VERSION "dbc-export 1 2026.26.6.5"

NS_ :

BS_:

BU_: ADSP APB APP APS APSB BB BMS CC CMP CMPD CP DAS DI DIF DIR DPB EPAS3P EPAS3S EPASTP EPASTS EPBL EPBR ESP EVSE FC GTW HCML HCMR HVP IBST ICR IDB LS OCS1P ODIN PARK PCS PCS2 PLG PM PMF PMR PNCD PTC RADC RCM RCM2 RCM3 RCU SCCM SCM SCS SDCR TAS TCU TCU2 TPMS TRCM UDS UI UIS UMC USM V2G VC VCBATT VCBATT0 VCBATT1 VCBATT2 VCCC VCFRONT VCFRONT1 VCFRONT2 VCLEFT VCRIGHT VCSEAT2L VCSEAT2R VCSEC VEH

BO_ 935 DIR_alertMatrix: 8 DIR
 SG_ DIR_matrixIndex M : 0|4@1+ (1,0) [0|15] "" Vector__XXX
 SG_ DIR_a001_hwPhaseAgateDrive m0 : 4|1@1+ (1,0) [0|1] "" Vector__XXX
 SG_ DIR_a002_hwPhaseBgateDrive m0 : 5|1@1+ (1,0) [0|1] "" Vector__XXX
 SG_ DIR_a003_hwPhaseCgateDrive m0 : 6|1@1+ (1,0) [0|1] "" Vector__XXX
 SG_ DIR_a004_hwPhaseApeak m0 : 7|1@1+ (1,0) [0|1] "" Vector__XXX
 SG_ DIR_a005_hwPhaseBpeak m0 : 8|1@1+ (1,0) [0|1] "" Vector__XXX
 SG_ DIR_a006_hwPhaseCpeak m0 : 9|1@1+ (1,0) [0|1] "" Vector__XXX
 SG_ DIR_a007_statorAnomalyDetected m0 : 10|1@1+ (1,0) [0|1] "" Vector__XXX
 SG_ DIR_a008_hwEncoderA m0 : 11|1@1+ (1,0) [0|1] "" Vector__XXX
 SG_ DIR_a009_hwEncoderB m0 : 12|1@1+ (1,0) [0|1] "" Vector__XXX
 SG_ DIR_a010_unintendedReset m0 : 13|1@1+ (1,0) [0|1] "" Vector__XXX
 SG_ DIR_a011_swPowerStageNotReady m0 : 14|1@1+ (1,0) [0|1] "" Vector__XXX
 SG_ DIR_a012_hvilNotClosed m0 : 15|1@1+ (1,0) [0|1] "" Vector__XXX
 SG_ DIR_a013_eccError m0 : 16|1@1+ (1,0) [0|1] "" Vector__XXX
 SG_ DIR_a014_activeDamping m0 : 17|1@1+ (1,0) [0|1] "" Vector__XXX
 SG_ DIR_a015_mechSafeStateAnomaly m0 : 18|1@1+ (1,0) [0|1] "" Vector__XXX
 SG_ DIR_a016_safeStateApplied m0 : 19|1@1+ (1,0) [0|1] "" Vector__XXX
 SG_ DIR_a017_hwPedalMonitor m0 : 20|1@1+ (1,0) [0|1] "" Vector__XXX
 SG_ DIR_a018_hwLVSupplyUV m0 : 21|1@1+ (1,0) [0|1] "" Vector__XXX
 SG_ DIR_a020_hwMotorEncoder m0 : 23|1@1+ (1,0) [0|1] "" Vector__XXX
 SG_ DIR_a021_hwBusOV m0 : 24|1@1+ (1,0) [0|1] "" Vector__XXX
 SG_ DIR_a022_hw5vSupplyUV m0 : 25|1@1+ (1,0) [0|1] "" Vector__XXX
 SG_ DIR_a024_selfTest m0 : 27|1@1+ (1,0) [0|1] "" Vector__XXX
 SG_ DIR_a025_phaseApeak m0 : 28|1@1+ (1,0) [0|1] "" Vector__XXX
 SG_ DIR_a026_phaseBpeak m0 : 29|1@1+ (1,0) [0|1] "" Vector__XXX
 SG_ DIR_a027_phaseCpeak m0 : 30|1@1+ (1,0) [0|1] "" Vector__XXX
 SG_ DIR_a028_phaseArms m0 : 31|1@1+ (1,0) [0|1] "" Vector__XXX
 SG_ DIR_a029_phaseBrms m0 : 32|1@1+ (1,0) [0|1] "" Vector__XXX
 SG_ DIR_a030_phaseCrms m0 : 33|1@1+ (1,0) [0|1] "" Vector__XXX
 SG_ DIR_a031_phaseAcurrentOffset m0 : 34|1@1+ (1,0) [0|1] "" Vector__XXX
 SG_ DIR_a032_phaseBcurrentOffset m0 : 35|1@1+ (1,0) [0|1] "" Vector__XXX
 SG_ DIR_a033_phaseAcurrentSensor m0 : 36|1@1+ (1,0) [0|1] "" Vector__XXX
 SG_ DIR_a034_phaseBcurrentSensor m0 : 37|1@1+ (1,0) [0|1] "" Vector__XXX
 SG_ DIR_a035_phaseCurrentBalance m0 : 38|1@1+ (1,0) [0|1] "" Vector__XXX
 SG_ DIR_a036_busOV m0 : 39|1@1+ (1,0) [0|1] "" Vector__XXX
 SG_ DIR_a037_busUV m0 : 40|1@1+ (1,0) [0|1] "" Vector__XXX
 SG_ DIR_a038_busVsensor m0 : 41|1@1+ (1,0) [0|1] "" Vector__XXX
 SG_ DIR_a039_exceptionUndefinedInstr m0 : 42|1@1+ (1,0) [0|1] "" Vector__XXX
 SG_ DIR_a040_difMIA m0 : 43|1@1+ (1,0) [0|1] "" Vector__XXX
 SG_ DIR_a041_sdcMIA m0 : 44|1@1+ (1,0) [0|1] "" Vector__XXX
 SG_ DIR_a042_inletSensor m0 : 45|1@1+ (1,0) [0|1] "" Vector__XXX
 SG_ DIR_a043_outletOT m0 : 46|1@1+ (1,0) [0|1] "" Vector__XXX
 SG_ DIR_a044_outletUT m0 : 47|1@1+ (1,0) [0|1] "" Vector__XXX
 SG_ DIR_a045_outletSensor m0 : 48|1@1+ (1,0) [0|1] "" Vector__XXX
 SG_ DIR_a046_statorOT m0 : 49|1@1+ (1,0) [0|1] "" Vector__XXX
 SG_ DIR_a047_statorSensor1 m0 : 50|1@1+ (1,0) [0|1] "" Vector__XXX
 SG_ DIR_a048_statorSensor2 m0 : 51|1@1+ (1,0) [0|1] "" Vector__XXX
 SG_ DIR_a049_statorSensorDiff m0 : 52|1@1+ (1,0) [0|1] "" Vector__XXX
 SG_ DIR_a050_noStatorSensor m0 : 53|1@1+ (1,0) [0|1] "" Vector__XXX
 SG_ DIR_a052_dirMIA m0 : 55|1@1+ (1,0) [0|1] "" Vector__XXX
 SG_ DIR_a053_unexpectedLatchState m0 : 56|1@1+ (1,0) [0|1] "" Vector__XXX
 SG_ DIR_a054_driveInverterOT m0 : 57|1@1+ (1,0) [0|1] "" Vector__XXX
 SG_ DIR_a055_trqCrossCheck m0 : 58|1@1+ (1,0) [0|1] "" Vector__XXX
 SG_ DIR_a056_ambientOT m0 : 59|1@1+ (1,0) [0|1] "" Vector__XXX
 SG_ DIR_a057_ambientUT m0 : 60|1@1+ (1,0) [0|1] "" Vector__XXX
 SG_ DIR_a058_ambientSensor m0 : 61|1@1+ (1,0) [0|1] "" Vector__XXX
 SG_ DIR_a059_heatsinkOT m0 : 62|1@1+ (1,0) [0|1] "" Vector__XXX
 SG_ DIR_a060_heatsinkUT m0 : 63|1@1+ (1,0) [0|1] "" Vector__XXX
 SG_ DIR_a061_heatsinkSensor m1 : 4|1@1+ (1,0) [0|1] "" Vector__XXX
 SG_ DIR_a062_systemLimpMode m1 : 5|1@1+ (1,0) [0|1] "" Vector__XXX
 SG_ DIR_a063_bbMIA m1 : 6|1@1+ (1,0) [0|1] "" Vector__XXX
 SG_ DIR_a064_torqueIntervention m1 : 7|1@1+ (1,0) [0|1] "" Vector__XXX
 SG_ DIR_a065_canHardwareBusB m1 : 8|1@1+ (1,0) [0|1] "" Vector__XXX
 SG_ DIR_a066_canDataBusB m1 : 9|1@1+ (1,0) [0|1] "" Vector__XXX
 SG_ DIR_a067_canOverrunBusB m1 : 10|1@1+ (1,0) [0|1] "" Vector__XXX
 SG_ DIR_a069_rotorTempLimit m1 : 12|1@1+ (1,0) [0|1] "" Vector__XXX
 SG_ DIR_a070_udsTransactionInitiated m1 : 13|1@1+ (1,0) [0|1] "" Vector__XXX
 SG_ DIR_a071_busDisconnected m1 : 14|1@1+ (1,0) [0|1] "" Vector__XXX
 SG_ DIR_a072_gateDriveFaultCounter m1 : 15|1@1+ (1,0) [0|1] "" Vector__XXX
 SG_ DIR_a073_motorSpeed m1 : 16|1@1+ (1,0) [0|1] "" Vector__XXX
 SG_ DIR_a074_motorEncoder m1 : 17|1@1+ (1,0) [0|1] "" Vector__XXX
 SG_ DIR_a075_motorSpeedMismatch m1 : 18|1@1+ (1,0) [0|1] "" Vector__XXX
 SG_ DIR_a076_lvSupplyOV m1 : 19|1@1+ (1,0) [0|1] "" Vector__XXX
 SG_ DIR_a077_lvSupplyUV m1 : 20|1@1+ (1,0) [0|1] "" Vector__XXX
 SG_ DIR_a078_adcRefLow m1 : 21|1@1+ (1,0) [0|1] "" Vector__XXX
 SG_ DIR_a079_adcRefHigh m1 : 22|1@1+ (1,0) [0|1] "" Vector__XXX
 SG_ DIR_a084_eccTestData0 m1 : 27|1@1+ (1,0) [0|1] "" Vector__XXX
 SG_ DIR_d085_driveInverterBoardFailu m1 : 28|1@1+ (1,0) [0|1] "" Vector__XXX
 SG_ DIR_a086_activeDischargeOn m1 : 29|1@1+ (1,0) [0|1] "" Vector__XXX
 SG_ DIR_a087_gtwMIA m1 : 30|1@1+ (1,0) [0|1] "" Vector__XXX
 SG_ DIR_a088_uiMIA m1 : 31|1@1+ (1,0) [0|1] "" Vector__XXX
 SG_ DIR_d089_invalidTorqueCommand m1 : 32|1@1+ (1,0) [0|1] "" Vector__XXX
 SG_ DIR_a090_pmMIA m1 : 33|1@1+ (1,0) [0|1] "" Vector__XXX
 SG_ DIR_a091_espMIA m1 : 34|1@1+ (1,0) [0|1] "" Vector__XXX
 SG_ DIR_a092_bmsMIA m1 : 35|1@1+ (1,0) [0|1] "" Vector__XXX
 SG_ DIR_a093_canHardwareBusA m1 : 36|1@1+ (1,0) [0|1] "" Vector__XXX
 SG_ DIR_a094_canDataBusA m1 : 37|1@1+ (1,0) [0|1] "" Vector__XXX
 SG_ DIR_a095_canOverrunBusA m1 : 38|1@1+ (1,0) [0|1] "" Vector__XXX
 SG_ DIR_a096_memoryError m1 : 39|1@1+ (1,0) [0|1] "" Vector__XXX
 SG_ DIR_a097_eepromError m1 : 40|1@1+ (1,0) [0|1] "" Vector__XXX
 SG_ DIR_a098_intTimeTooLong m1 : 41|1@1+ (1,0) [0|1] "" Vector__XXX
 SG_ DIR_a099_threadOverrun m1 : 42|1@1+ (1,0) [0|1] "" Vector__XXX
 SG_ DIR_a100_assertion m1 : 43|1@1+ (1,0) [0|1] "" Vector__XXX
 SG_ DIR_a101_eccTestData1 m1 : 44|1@1+ (1,0) [0|1] "" Vector__XXX
 SG_ DIR_a102_exceptionPrefetchAbort m1 : 45|1@1+ (1,0) [0|1] "" Vector__XXX
 SG_ DIR_a103_lowFlow m1 : 46|1@1+ (1,0) [0|1] "" Vector__XXX
 SG_ DIR_d104_resetUnintended m1 : 47|1@1+ (1,0) [0|1] "" Vector__XXX
 SG_ DIR_d105_busVoltageSensorIssue m1 : 48|1@1+ (1,0) [0|1] "" Vector__XXX
 SG_ DIR_a106_idleTaskStarving m1 : 49|1@1+ (1,0) [0|1] "" Vector__XXX
 SG_ DIR_a107_fpgaError m1 : 50|1@1+ (1,0) [0|1] "" Vector__XXX
 SG_ DIR_a108_stateTrans m1 : 51|1@1+ (1,0) [0|1] "" Vector__XXX
 SG_ DIR_a109_ahbWriteError m1 : 52|1@1+ (1,0) [0|1] "" Vector__XXX
 SG_ DIR_a110_brakeMIA m1 : 53|1@1+ (1,0) [0|1] "" Vector__XXX
 SG_ DIR_a111_badPhaseSensorCalib m1 : 54|1@1+ (1,0) [0|1] "" Vector__XXX
 SG_ DIR_a112_noPhaseCurrent m1 : 55|1@1+ (1,0) [0|1] "" Vector__XXX
 SG_ DIR_a113_noFuncHeatsinkSensor m1 : 56|1@1+ (1,0) [0|1] "" Vector__XXX
 SG_ DIR_a114_exceptionDataAbort m1 : 57|1@1+ (1,0) [0|1] "" Vector__XXX
 SG_ DIR_a115_exceptionDataAbort2 m1 : 58|1@1+ (1,0) [0|1] "" Vector__XXX
 SG_ DIR_a116_highSpeedWearCounter m1 : 59|1@1+ (1,0) [0|1] "" Vector__XXX
 SG_ DIR_a117_diMIA m1 : 60|1@1+ (1,0) [0|1] "" Vector__XXX
 SG_ DIR_d118_oilPumpCommsLost m1 : 61|1@1+ (1,0) [0|1] "" Vector__XXX
 SG_ DIR_a119_hvpMIA m1 : 62|1@1+ (1,0) [0|1] "" Vector__XXX
 SG_ DIR_a120_hvlinkMIA m1 : 63|1@1+ (1,0) [0|1] "" Vector__XXX
 SG_ DIR_a121_motorControlRegulation m2 : 4|1@1+ (1,0) [0|1] "" Vector__XXX
 SG_ DIR_a122_highStackUsage m2 : 5|1@1+ (1,0) [0|1] "" Vector__XXX
 SG_ DIR_a123_lossMotorControl m2 : 6|1@1+ (1,0) [0|1] "" Vector__XXX
 SG_ DIR_d124_oilPumpServiceRequired m2 : 7|1@1+ (1,0) [0|1] "" Vector__XXX
 SG_ DIR_d125_currentSensorIssue m2 : 8|1@1+ (1,0) [0|1] "" Vector__XXX
 SG_ DIR_a126_limpMode m2 : 9|1@1+ (1,0) [0|1] "" Vector__XXX
 SG_ DIR_a127_gracefulPowerOff m2 : 10|1@1+ (1,0) [0|1] "" Vector__XXX
 SG_ DIR_a128_fpgaVersionMismatch m2 : 11|1@1+ (1,0) [0|1] "" Vector__XXX
 SG_ DIR_d129_oilPumpIssue m2 : 12|1@1+ (1,0) [0|1] "" Vector__XXX
 SG_ DIR_d130_positionSensorIssue m2 : 13|1@1+ (1,0) [0|1] "" Vector__XXX
 SG_ DIR_d131_currentSensorOffset m2 : 14|1@1+ (1,0) [0|1] "" Vector__XXX
 SG_ DIR_d132_busUVIssue m2 : 15|1@1+ (1,0) [0|1] "" Vector__XXX
 SG_ DIR_a133_capacitorOT m2 : 16|1@1+ (1,0) [0|1] "" Vector__XXX
 SG_ DIR_a134_wheelSpeedIrrational m2 : 17|1@1+ (1,0) [0|1] "" Vector__XXX
 SG_ DIR_d135_rotatedStator m2 : 18|1@1+ (1,0) [0|1] "" Vector__XXX
 SG_ DIR_a136_spiError m2 : 19|1@1+ (1,0) [0|1] "" Vector__XXX
 SG_ DIR_d137_currentSensorOutOfRange m2 : 20|1@1+ (1,0) [0|1] "" Vector__XXX
 SG_ DIR_d138_inverterLVPowerSupplyLo m2 : 21|1@1+ (1,0) [0|1] "" Vector__XXX
 SG_ DIR_d141_coolingSystemIssue m2 : 24|1@1+ (1,0) [0|1] "" Vector__XXX
 SG_ DIR_a142_highLashAngle m2 : 25|1@1+ (1,0) [0|1] "" Vector__XXX
 SG_ DIR_d143_wheelSpeedCorrelationIs m2 : 26|1@1+ (1,0) [0|1] "" Vector__XXX
 SG_ DIR_a144_configMismatch m2 : 27|1@1+ (1,0) [0|1] "" Vector__XXX
 SG_ DIR_a147_highTorqueWearLimit m2 : 30|1@1+ (1,0) [0|1] "" Vector__XXX
 SG_ DIR_a148_burnInCycleEnded m2 : 31|1@1+ (1,0) [0|1] "" Vector__XXX
 SG_ DIR_a149_oilPumpFailure m2 : 32|1@1+ (1,0) [0|1] "" Vector__XXX
 SG_ DIR_a150_busVD m2 : 33|1@1+ (1,0) [0|1] "" Vector__XXX
 SG_ DIR_a151_shockTorqueLimiter m2 : 34|1@1+ (1,0) [0|1] "" Vector__XXX
 SG_ DIR_a152_linError m2 : 35|1@1+ (1,0) [0|1] "" Vector__XXX
 SG_ DIR_a153_oilPumpDiagnostics m2 : 36|1@1+ (1,0) [0|1] "" Vector__XXX
 SG_ DIR_a154_resolver m2 : 37|1@1+ (1,0) [0|1] "" Vector__XXX
 SG_ DIR_a155_vcfrontMIA m2 : 38|1@1+ (1,0) [0|1] "" Vector__XXX
 SG_ DIR_a156_currentObserver m2 : 39|1@1+ (1,0) [0|1] "" Vector__XXX
 SG_ DIR_a157_rcmMIA m2 : 40|1@1+ (1,0) [0|1] "" Vector__XXX
 SG_ DIR_a158_ibstMIA m2 : 41|1@1+ (1,0) [0|1] "" Vector__XXX
 SG_ DIR_a160_busVoltageAnomaly m2 : 43|1@1+ (1,0) [0|1] "" Vector__XXX
 SG_ DIR_a161_epas3pMIA m2 : 44|1@1+ (1,0) [0|1] "" Vector__XXX
 SG_ DIR_a162_endOfLifetimeBurnIn m2 : 45|1@1+ (1,0) [0|1] "" Vector__XXX
 SG_ DIR_d163_recoverableOvercurrent m2 : 46|1@1+ (1,0) [0|1] "" Vector__XXX
 SG_ DIR_d164_firmwareConfigMismatch m2 : 47|1@1+ (1,0) [0|1] "" Vector__XXX
 SG_ DIR_d165_statorOverTemperature m2 : 48|1@1+ (1,0) [0|1] "" Vector__XXX
 SG_ DIR_d166_rotorOverTemperature m2 : 49|1@1+ (1,0) [0|1] "" Vector__XXX
 SG_ DIR_d167_tempSensorIssue m2 : 50|1@1+ (1,0) [0|1] "" Vector__XXX
 SG_ DIR_a171_rdcError m2 : 54|1@1+ (1,0) [0|1] "" Vector__XXX
 SG_ DIR_a172_statorOilTempOT m2 : 55|1@1+ (1,0) [0|1] "" Vector__XXX
 SG_ DIR_a173_ascFdbkDiagnostic m2 : 56|1@1+ (1,0) [0|1] "" Vector__XXX
 SG_ DIR_a174_unitMayNotRestart m2 : 57|1@1+ (1,0) [0|1] "" Vector__XXX
 SG_ DIR_d175_oilPumpBCommsLost m2 : 58|1@1+ (1,0) [0|1] "" Vector__XXX
 SG_ DIR_a176_safetyICFault m2 : 59|1@1+ (1,0) [0|1] "" Vector__XXX
 SG_ DIR_a177_fluxReferenceCorrected m2 : 60|1@1+ (1,0) [0|1] "" Vector__XXX
 SG_ DIR_a178_spindownLearningBrakeAl m2 : 61|1@1+ (1,0) [0|1] "" Vector__XXX
 SG_ DIR_d179_oilPumpBIssue m2 : 62|1@1+ (1,0) [0|1] "" Vector__XXX
 SG_ DIR_a194_resolverGainAnomaly m3 : 17|1@1+ (1,0) [0|1] "" Vector__XXX
 SG_ DIR_a202_excessHeatUnavailable m3 : 25|1@1+ (1,0) [0|1] "" Vector__XXX
 SG_ DIR_a225_tmpEstPlausibility m3 : 48|1@1+ (1,0) [0|1] "" Vector__XXX
 SG_ DIR_a229_busVsensorOverCAN m3 : 52|1@1+ (1,0) [0|1] "" Vector__XXX
 SG_ DIR_a233_diMsgMissed m3 : 56|1@1+ (1,0) [0|1] "" Vector__XXX
 SG_ DIR_a234_pcsMIA m3 : 57|1@1+ (1,0) [0|1] "" Vector__XXX
 SG_ DIR_a236_tasMIA m3 : 59|1@1+ (1,0) [0|1] "" Vector__XXX
 SG_ DIR_a239_rotorDemagnetizationDet m3 : 62|1@1+ (1,0) [0|1] "" Vector__XXX
 SG_ DIR_a240_clearFusesRoutine m3 : 63|1@1+ (1,0) [0|1] "" Vector__XXX
 SG_ DIR_a241_systemThermallyLimited m4 : 4|1@1+ (1,0) [0|1] "" Vector__XXX
 SG_ DIR_a242_spinDownLearning m4 : 5|1@1+ (1,0) [0|1] "" Vector__XXX
 SG_ DIR_a243_ecuLogAvailable m4 : 6|1@1+ (1,0) [0|1] "" Vector__XXX
 SG_ DIR_a244_mechSafeStateApplied m4 : 7|1@1+ (1,0) [0|1] "" Vector__XXX
 SG_ DIR_a245_mechSafeStatePreWarn m4 : 8|1@1+ (1,0) [0|1] "" Vector__XXX
 SG_ DIR_a246_recoveryAtSpeedError m4 : 9|1@1+ (1,0) [0|1] "" Vector__XXX
 SG_ DIR_a247_rotorOffsetError m4 : 10|1@1+ (1,0) [0|1] "" Vector__XXX
 SG_ DIR_a248_vehicleSpeedLimited m4 : 11|1@1+ (1,0) [0|1] "" Vector__XXX
 SG_ DIR_a249_highStatorTempFromResis m4 : 12|1@1+ (1,0) [0|1] "" Vector__XXX
 SG_ DIR_a250_preregulatorRail m4 : 13|1@1+ (1,0) [0|1] "" Vector__XXX
 SG_ DIR_a251_oilPumpService m4 : 14|1@1+ (1,0) [0|1] "" Vector__XXX
 SG_ DIR_a252_currentCoreFallback m4 : 15|1@1+ (1,0) [0|1] "" Vector__XXX
 SG_ DIR_a253_lvBoostedRail m4 : 16|1@1+ (1,0) [0|1] "" Vector__XXX
 SG_ DIR_a254_activeDischargeRail m4 : 17|1@1+ (1,0) [0|1] "" Vector__XXX
 SG_ DIR_a255_currentGainFallback m4 : 18|1@1+ (1,0) [0|1] "" Vector__XXX

BO_ 2005 DIR_debug: 8 DIR
 SG_ DIR_debugSelector M : 0|8@1+ (1,0) [0|255] "" Vector__XXX
 SG_ DIR_phaseOutBusbarTemp m70 : 8|8@1+ (1,-40) [-39|215] "DegC" Vector__XXX
 SG_ DIR_phaseOutBusbarWeldTemp m70 : 16|8@1+ (1,-40) [-39|215] "DegC" Vector__XXX
 SG_ DIR_phaseOutLugTemp m70 : 24|8@1+ (1,-40) [-39|215] "DegC" Vector__XXX
 SG_ DIR_dcLinkCapTemp m70 : 32|8@1+ (1,-40) [-39|215] "DegC" Vector__XXX
 SG_ DIR_hvDcCableTemp m70 : 40|8@1+ (1,-40) [-39|215] "DegC" Vector__XXX
 SG_ DIR_negDcBusbarTemp m70 : 48|8@1+ (1,-40) [-39|215] "DegC" Vector__XXX
 SG_ DIR_posDcBusbarTemp m70 : 56|8@1+ (1,-40) [-39|215] "DegC" Vector__XXX
 SG_ DIR_statorEndWindingTemp m72 : 8|8@1+ (1,-40) [-39|215] "DegC" Vector__XXX
 SG_ DIR_rotorMaxMagnetTemp m72 : 16|8@1+ (1,-40) [-39|215] "DegC" Vector__XXX
 SG_ DIR_lightSenseV m72 : 24|6@1+ (0.1,0) [0|3.3] "V" Vector__XXX
 SG_ DIR_pyroSenseV m72 : 30|8@1+ (0.02,0) [0|3.3] "V" Vector__XXX
 SG_ DIR_statorSlotWindingTemp m72 : 46|8@1+ (1,-40) [-39|215] "DegC" Vector__XXX
 SG_ DIR_intervalMaxHvBusV m72 : 54|10@1+ (1,0) [0|1023] "V" Vector__XXX

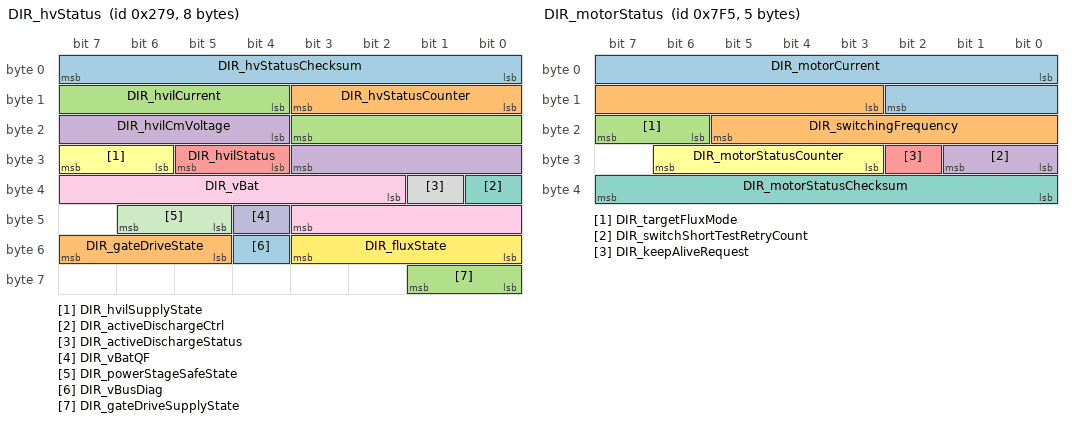
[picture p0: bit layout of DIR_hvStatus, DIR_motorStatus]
BO_ 633 DIR_hvStatus: 8 DIR
 SG_ DIR_hvStatusChecksum : 0|8@1+ (1,0) [0|255] "" Vector__XXX
 SG_ DIR_hvStatusCounter : 8|4@1+ (1,0) [0|15] "" Vector__XXX
 SG_ DIR_hvilCurrent : 12|8@1+ (0.1,0) [0|25.5] "mA" Vector__XXX
 SG_ DIR_hvilCmVoltage : 20|8@1+ (0.08,0) [0|20.4] "V" Vector__XXX
 SG_ DIR_hvilStatus : 28|2@1+ (1,0) [0|2] "" Vector__XXX
 SG_ DIR_hvilSupplyState : 30|2@1+ (1,0) [0|3] "" Vector__XXX
 SG_ DIR_activeDischargeCtrl : 32|1@1+ (1,0) [0|1] "" Vector__XXX
 SG_ DIR_activeDischargeStatus : 33|1@1+ (1,0) [0|1] "" Vector__XXX
 SG_ DIR_vBat : 34|10@1+ (1,0) [0|1023] "V" Vector__XXX
 SG_ DIR_vBatQF : 44|1@1+ (1,0) [0|1] "" Vector__XXX
 SG_ DIR_powerStageSafeState : 45|2@1+ (1,0) [0|3] "" Vector__XXX
 SG_ DIR_fluxState : 48|4@1+ (1,0) [0|15] "" Vector__XXX
 SG_ DIR_vBusDiag : 52|1@1+ (1,0) [0|1] "" Vector__XXX
 SG_ DIR_gateDriveState : 53|3@1+ (1,0) [0|7] "" Vector__XXX
 SG_ DIR_gateDriveSupplyState : 56|2@1+ (1,0) [0|3] "" Vector__XXX

BO_ 821 DIR_info: 8 DIR
 SG_ DIR_infoIndex M : 0|8@1+ (1,0) [0|255] "" Vector__XXX
 SG_ DIR_buildType m10 : 8|3@1+ (1,0) [0|7] "" Vector__XXX
 SG_ DIR_buildConfigurationId m10 : 16|16@1+ (1,0) [0|65535] "" Vector__XXX
 SG_ DIR_hardwareId m10 : 32|8@1+ (1,0) [0|252] "" Vector__XXX
 SG_ DIR_componentId m10 : 48|16@1+ (1,0) [0|65535] "" Vector__XXX
 SG_ DIR_pcbaId m11 : 16|8@1+ (1,0) [0|255] "" Vector__XXX
 SG_ DIR_assemblyId m11 : 24|8@1+ (1,0) [0|255] "" Vector__XXX
 SG_ DIR_usageId m11 : 32|16@1+ (1,0) [0|65535] "" Vector__XXX
 SG_ DIR_subUsageId m11 : 48|16@1+ (1,0) [0|65535] "" Vector__XXX
 SG_ DIR_motorType m12 : 8|6@1+ (1,0) [1|63] "" Vector__XXX
 SG_ DIR_siliconType m12 : 16|1@1+ (1,0) [0|1] "" Vector__XXX
 SG_ DIR_mechSafeStateType m12 : 24|2@1+ (1,0) [1|3] "" Vector__XXX
 SG_ DIR_applicationCrc m13 : 32|32@1+ (1,0) [0|4294967295] "" Vector__XXX
 SG_ DIR_oilPumpBuildType m16 : 8|3@1+ (1,0) [0|7] "" Vector__XXX
 SG_ DIR_oilPumpAppCrc m16 : 16|32@1+ (1,0) [0|4294967295] "" Vector__XXX
 SG_ DIR_FPGA_version m16 : 48|8@1+ (1,0) [0|254] "" Vector__XXX
 SG_ DIR_appGitHash m17 : 8|56@1+ (1,0) [0|7.20575940379e+16] "" Vector__XXX
 SG_ DIR_bootGitHash m18 : 8|56@1+ (1,0) [0|7.20575940379e+16] "" Vector__XXX
 SG_ DIR_infoBootLdUdsProtocolVersion m20 : 8|8@1+ (1,0) [0|255] "" Vector__XXX
 SG_ DIR_bootloaderCrc m20 : 32|32@1+ (1,0) [0|4294967295] "" Vector__XXX
 SG_ DIR_oilPumpPcbaId m33 : 8|8@1+ (1,0) [0|255] "" Vector__XXX
 SG_ DIR_oilPumpAssemblyId m33 : 16|8@1+ (1,0) [0|255] "" Vector__XXX
 SG_ DIR_oilPumpUsageId m33 : 24|16@1+ (1,0) [0|65535] "" Vector__XXX
 SG_ DIR_refRotorFlux m35 : 8|16@1+ (0.0001,0) [0|6.5535] "Wb" Vector__XXX
 SG_ DIR_refRotorOffset m35 : 24|12@1- (0.1,0) [-180|180] "deg" Vector__XXX
 SG_ DIR_speedWearTotal m36 : 8|8@1+ (0.4,0) [0|100] "%" Vector__XXX
 SG_ DIR_torqueWearTotal m36 : 24|8@1+ (0.02,0) [0|5.08] "1" Vector__XXX

BO_ 2037 DIR_motorStatus: 5 DIR
 SG_ DIR_motorCurrent : 0|11@1+ (1,0) [0|2047] "A" Vector__XXX
 SG_ DIR_switchingFrequency : 11|11@1+ (0.01,0) [0|20] "kHz" Vector__XXX
 SG_ DIR_targetFluxMode : 22|2@1+ (1,0) [0|3] "" Vector__XXX
 SG_ DIR_switchShortTestRetryCount : 24|2@1+ (1,0) [0|3] "" Vector__XXX
 SG_ DIR_keepAliveRequest : 26|1@1+ (1,0) [0|1] "" Vector__XXX
 SG_ DIR_motorStatusCounter : 27|4@1+ (1,0) [0|15] "" Vector__XXX
 SG_ DIR_motorStatusChecksum : 32|8@1+ (1,0) [0|255] "" Vector__XXX

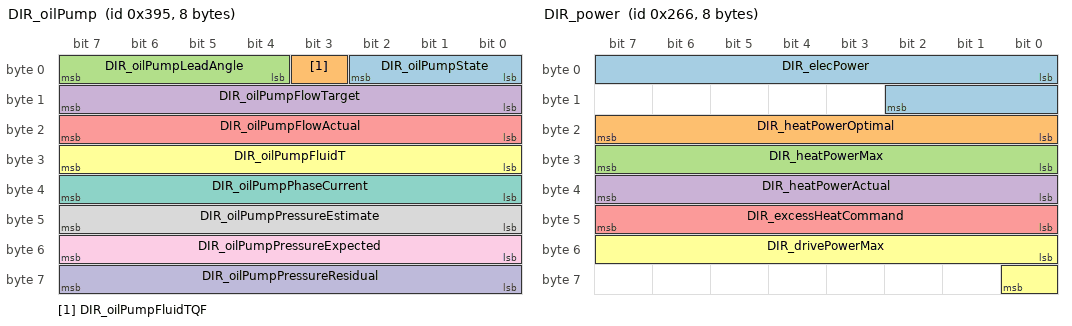
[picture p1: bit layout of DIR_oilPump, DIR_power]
BO_ 917 DIR_oilPump: 8 DIR
 SG_ DIR_oilPumpState : 0|3@1+ (1,0) [0|6] "" Vector__XXX
 SG_ DIR_oilPumpFluidTQF : 3|1@1+ (1,0) [0|1] "" Vector__XXX
 SG_ DIR_oilPumpLeadAngle : 4|4@1+ (1.875,0) [0|28.125] "degrees" Vector__XXX
 SG_ DIR_oilPumpFlowTarget : 8|8@1+ (0.1,0) [0|25.4] "LPM" Vector__XXX
 SG_ DIR_oilPumpFlowActual : 16|8@1+ (0.1,0) [0|25.4] "LPM" Vector__XXX
 SG_ DIR_oilPumpFluidT : 24|8@1+ (1,-40) [-40|214] "DegC" Vector__XXX
 SG_ DIR_oilPumpPhaseCurrent : 32|8@1+ (0.1,0) [0|25.4] "A" Vector__XXX
 SG_ DIR_oilPumpPressureEstimate : 40|8@1+ (2,0) [0|500] "kPa" Vector__XXX
 SG_ DIR_oilPumpPressureExpected : 48|8@1+ (2,0) [0|500] "kPa" Vector__XXX
 SG_ DIR_oilPumpPressureResidual : 56|8@1+ (4,-500) [-500|500] "kPa" Vector__XXX

BO_ 614 DIR_power: 8 DIR
 SG_ DIR_elecPower : 0|11@1- (0.5,0) [-500|500] "kW" Vector__XXX
 SG_ DIR_heatPowerOptimal : 16|8@1+ (0.08,0) [0|20] "kW" Vector__XXX
 SG_ DIR_heatPowerMax : 24|8@1+ (0.08,0) [0|20] "kW" Vector__XXX
 SG_ DIR_heatPowerActual : 32|8@1+ (0.08,0) [0|20] "kW" Vector__XXX
 SG_ DIR_excessHeatCommand : 40|8@1+ (0.08,0) [0|20] "kW" Vector__XXX
 SG_ DIR_drivePowerMax : 48|9@1+ (1,0) [0|400] "kW" Vector__XXX

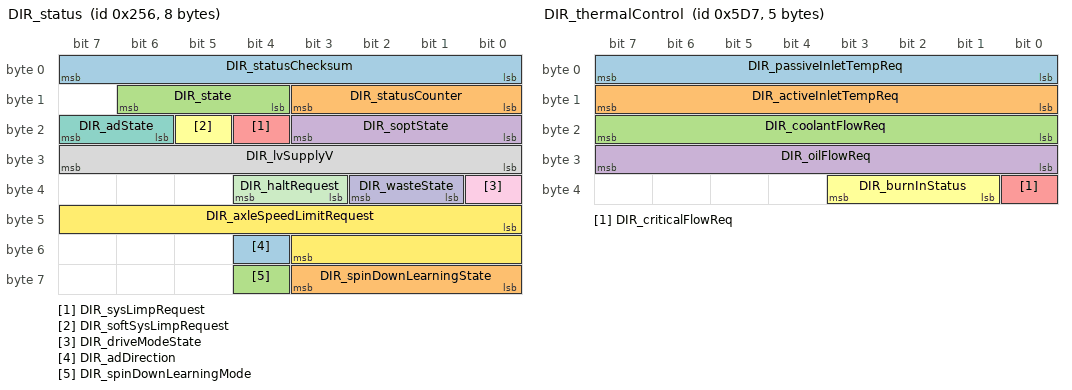
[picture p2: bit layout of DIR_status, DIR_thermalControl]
BO_ 598 DIR_status: 8 DIR
 SG_ DIR_statusChecksum : 0|8@1+ (1,0) [0|255] "" Vector__XXX
 SG_ DIR_statusCounter : 8|4@1+ (1,0) [0|15] "" Vector__XXX
 SG_ DIR_state : 12|3@1+ (1,0) [0|7] "" Vector__XXX
 SG_ DIR_soptState : 16|4@1+ (1,0) [0|15] "" Vector__XXX
 SG_ DIR_sysLimpRequest : 20|1@1+ (1,0) [0|1] "" Vector__XXX
 SG_ DIR_softSysLimpRequest : 21|1@1+ (1,0) [0|1] "" Vector__XXX
 SG_ DIR_adState : 22|2@1+ (1,0) [0|3] "" Vector__XXX
 SG_ DIR_lvSupplyV : 24|8@1+ (0.1,0) [0|25.5] "V" Vector__XXX
 SG_ DIR_driveModeState : 32|1@1+ (1,0) [0|1] "" Vector__XXX
 SG_ DIR_wasteState : 33|2@1+ (1,0) [0|3] "" Vector__XXX
 SG_ DIR_haltRequest : 35|2@1+ (1,0) [0|3] "" Vector__XXX
 SG_ DIR_axleSpeedLimitRequest : 40|12@1+ (1,40) [400|2750] "RPM" Vector__XXX
 SG_ DIR_adDirection : 52|1@1+ (1,0) [0|1] "" Vector__XXX
 SG_ DIR_spinDownLearningState : 56|4@1+ (1,0) [0|15] "" Vector__XXX
 SG_ DIR_spinDownLearningMode : 60|1@1+ (1,0) [0|1] "" Vector__XXX

BO_ 789 DIR_temperature: 8 DIR
 SG_ DIR_tempIndex M : 0|3@1+ (1,0) [0|7] "" Vector__XXX
 SG_ DIR_inverterTQF m0 : 3|2@1+ (1,0) [0|3] "" Vector__XXX
 SG_ DIR_pcbT m0 : 8|8@1+ (1,-40) [-39|215] "DegC" Vector__XXX
 SG_ DIR_inverterT m0 : 16|8@1+ (1,-40) [-40|215] "DegC" Vector__XXX
 SG_ DIR_statorT m0 : 24|8@1+ (1,-40) [-39|215] "DegC" Vector__XXX
 SG_ DIR_dcCapT m0 : 32|8@1+ (1,-40) [-39|215] "DegC" Vector__XXX
 SG_ DIR_heatsinkT m0 : 40|8@1+ (1,-40) [-39|215] "DegC" Vector__XXX
 SG_ DIR_inverterTpct m0 : 48|8@1+ (0.4,0) [0|100] "%" Vector__XXX
 SG_ DIR_statorTpct m0 : 56|8@1+ (0.4,0) [0|100] "%" Vector__XXX
 SG_ DIR_fluidInTemp m2 : 8|8@1+ (1,-40) [-39|215] "DegC" Vector__XXX
 SG_ DIR_normalFetBurnIn m2 : 16|16@1+ (0.00763,0) [0|500] "Hours" Vector__XXX
 SG_ DIR_additionalFetBurnIn m2 : 32|16@1+ (0.00763,0) [0|500] "Hours" Vector__XXX
 SG_ DIR_currentWeibullMiles m3 : 3|16@1+ (8,0) [0|500000] "miles" Vector__XXX
 SG_ DIR_endOfServiceWeibullMiles m3 : 19|16@1+ (8,0) [0|500000] "miles" Vector__XXX
 SG_ DIR_burnInDamageRatio m3 : 35|9@1+ (0.01,0) [0|5] "1" Vector__XXX
 SG_ DIR_inverterSensorEst m3 : 44|8@1+ (1,-40) [-40|120] "C" Vector__XXX
 SG_ DIR_inverterHS1Est m3 : 52|8@1+ (1,-40) [-40|120] "C" Vector__XXX
 SG_ DIR_initialBurnInVehicleOdometer m4 : 8|32@1+ (0.001,0) [0|4294967.294] "km" Vector__XXX
 SG_ DIR_inverterHS2Est m4 : 40|8@1+ (1,-40) [-40|120] "C" Vector__XXX
 SG_ DIR_inverterInletEst m4 : 48|8@1+ (1,-40) [-40|120] "C" Vector__XXX
 SG_ DIR_statorHousingTemp m4 : 56|8@1+ (1,-40) [-39|215] "DegC" Vector__XXX

BO_ 1495 DIR_thermalControl: 5 DIR
 SG_ DIR_passiveInletTempReq : 0|8@1+ (1,-40) [-40|215] "DegC" Vector__XXX
 SG_ DIR_activeInletTempReq : 8|8@1+ (1,-40) [-40|215] "DegC" Vector__XXX
 SG_ DIR_coolantFlowReq : 16|8@1+ (0.2,0) [0|50] "LPM" Vector__XXX
 SG_ DIR_oilFlowReq : 24|8@1+ (0.1,0) [0|25.4] "LPM" Vector__XXX
 SG_ DIR_criticalFlowReq : 32|1@1+ (1,0) [0|1] "" Vector__XXX
 SG_ DIR_burnInStatus : 33|3@1+ (1,0) [0|7] "" Vector__XXX

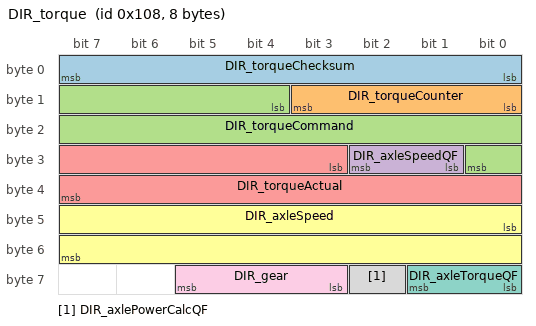
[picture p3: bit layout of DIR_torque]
BO_ 264 DIR_torque: 8 DIR
 SG_ DIR_torqueChecksum : 0|8@1+ (1,0) [0|255] "" Vector__XXX
 SG_ DIR_torqueCounter : 8|4@1+ (1,0) [0|15] "" Vector__XXX
 SG_ DIR_torqueCommand : 12|13@1- (2,0) [-7500|7500] "Nm" Vector__XXX
 SG_ DIR_axleSpeedQF : 25|2@1+ (1,0) [0|3] "" Vector__XXX
 SG_ DIR_torqueActual : 27|13@1- (2,0) [-7500|7500] "Nm" Vector__XXX
 SG_ DIR_axleSpeed : 40|16@1- (0.1,0) [-2750|2750] "RPM" Vector__XXX
 SG_ DIR_axleTorqueQF : 56|2@1+ (1,0) [0|3] "" Vector__XXX
 SG_ DIR_axlePowerCalcQF : 58|1@1+ (1,0) [0|1] "" Vector__XXX
 SG_ DIR_gear : 59|3@1+ (1,0) [0|6] "" Vector__XXX

BO_ 1558 DIR_udsResponse: 8 DIR
 SG_ DIR_udsResponseData : 7|64@0+ (1,0) [0|1.84467440737e+19] "" Vector__XXX

BO_ 1319 DI_alertLog: 8 DI
 SG_ DI_alertID M : 0|8@1+ (1,0) [0|255] "" Vector__XXX
 SG_ DI_alertState : 15|1@1+ (1,0) [0|1] "" Vector__XXX
 SG_ DI_a004_unavailableReason m4 : 16|5@1+ (1,0) [1|31] "" Vector__XXX
 SG_ DI_a007_button m7 : 16|2@1+ (1,0) [0|3] "" Vector__XXX
 SG_ DI_a007_buttonStuckTime m7 : 24|15@1+ (0.25,0) [0|8191.75] "second" Vector__XXX
 SG_ DI_a010_sccReset m10 : 16|1@1+ (1,0) [0|1] "" Vector__XXX
 SG_ DI_a010_hibernate m10 : 17|1@1+ (1,0) [0|1] "" Vector__XXX
 SG_ DI_a010_hwBist m10 : 18|1@1+ (1,0) [0|1] "" Vector__XXX
 SG_ DI_a010_nmiWatchdog m10 : 19|1@1+ (1,0) [0|1] "" Vector__XXX
 SG_ DI_a010_watchdog m10 : 20|1@1+ (1,0) [0|1] "" Vector__XXX
 SG_ DI_a010_clockFailNmi m10 : 21|1@1+ (1,0) [0|1] "" Vector__XXX
 SG_ DI_a010_ramUncErrorNmi m10 : 22|1@1+ (1,0) [0|1] "" Vector__XXX
 SG_ DI_a010_flashUncErrorNmi m10 : 23|1@1+ (1,0) [0|1] "" Vector__XXX
 SG_ DI_a010_cpu1signMismatchNmi m10 : 24|1@1+ (1,0) [0|1] "" Vector__XXX
 SG_ DI_a010_cpu2signMismatchNmi m10 : 25|1@1+ (1,0) [0|1] "" Vector__XXX
 SG_ DI_a010_pieVectErrorNmi m10 : 26|1@1+ (1,0) [0|1] "" Vector__XXX
 SG_ DI_a010_sysDbgNmi m10 : 27|1@1+ (1,0) [0|1] "" Vector__XXX
 SG_ DI_a010_rlNmi m10 : 28|1@1+ (1,0) [0|1] "" Vector__XXX
 SG_ DI_a010_ovfNmi m10 : 29|1@1+ (1,0) [0|1] "" Vector__XXX
 SG_ DI_a010_wdtFlags m10 : 32|16@1+ (1,0) [0|65535] "" Vector__XXX
 SG_ DI_a012_accel1SupplyV m12 : 16|16@1+ (0.001,0) [0|65.535] "V" Vector__XXX
 SG_ DI_a012_accel2SupplyV m12 : 32|16@1+ (0.001,0) [0|65.535] "V" Vector__XXX
 SG_ DI_a013_address m13 : 16|32@1+ (1,0) [0|4294967295] "" Vector__XXX
 SG_ DI_a013_errorType m13 : 48|4@1+ (1,0) [0|15] "" Vector__XXX
 SG_ DI_a015_reason m15 : 16|1@1+ (1,0) [0|1] "" Vector__XXX
 SG_ DI_a020_difHvilStatus m20 : 16|2@1+ (1,0) [0|2] "" Vector__XXX
 SG_ DI_a020_difStatusValid m20 : 18|1@1+ (1,0) [0|1] "" Vector__XXX
 SG_ DI_a020_dirHvilStatus m20 : 19|2@1+ (1,0) [0|2] "" Vector__XXX
 SG_ DI_a020_dirStatusValid m20 : 21|1@1+ (1,0) [0|1] "" Vector__XXX
 SG_ DI_a020_vehiclePowerState m20 : 22|2@1+ (1,0) [0|3] "" Vector__XXX
 SG_ DI_a020_hvilSystemStatus m20 : 24|2@1+ (1,0) [0|2] "" Vector__XXX
 SG_ DI_a021_packVoltage m21 : 16|16@1+ (0.1,0) [0|6553.5] "V" Vector__XXX
 SG_ DI_a021_maxBusVoltage m21 : 32|16@1+ (0.1,0) [0|6553.5] "V" Vector__XXX
 SG_ DI_a024_pedalPos m24 : 16|8@1+ (0.4,0) [0|102] "%" Vector__XXX
 SG_ DI_a024_brakePressed m24 : 24|1@1+ (1,0) [0|1] "" Vector__XXX
 SG_ DI_a024_currentGear m24 : 25|3@1+ (1,0) [0|6] "" Vector__XXX
 SG_ DI_a025_backfillState m25 : 16|2@1+ (1,0) [0|3] "" Vector__XXX
 SG_ DI_a025_bfillUnavailableReason m25 : 18|5@1+ (1,0) [0|31] "" Vector__XXX
 SG_ DI_a036_numFaultedUnits m36 : 16|4@1+ (1,0) [0|15] "" Vector__XXX
 SG_ DI_a036_numAvailableUnits m36 : 20|4@1+ (1,0) [0|15] "" Vector__XXX
 SG_ DI_a040_torque m40 : 16|1@1+ (1,0) [0|1] "" Vector__XXX
 SG_ DI_a040_capability m40 : 17|1@1+ (1,0) [0|1] "" Vector__XXX
 SG_ DI_a040_power m40 : 18|1@1+ (1,0) [0|1] "" Vector__XXX
 SG_ DI_a040_status m40 : 19|1@1+ (1,0) [0|1] "" Vector__XXX
 SG_ DI_a040_capability2 m40 : 20|1@1+ (1,0) [0|1] "" Vector__XXX
 SG_ DI_a040_hvStatus m40 : 21|1@1+ (1,0) [0|1] "" Vector__XXX
 SG_ DI_a040_temperature m40 : 22|1@1+ (1,0) [0|1] "" Vector__XXX
 SG_ DI_a042_state4 m42 : 16|1@1+ (1,0) [0|1] "" Vector__XXX
 SG_ DI_a043_state4 m43 : 16|1@1+ (1,0) [0|1] "" Vector__XXX
 SG_ DI_a051_dcCableCurrentEst m51 : 16|16@1- (0.1,0) [-3276.8|3276.7] "A" Vector__XXX
 SG_ DI_a051_packCurrent m51 : 32|16@1- (0.1,0) [-3276.8|3276.7] "A" Vector__XXX
 SG_ DI_a052_torque m52 : 16|1@1+ (1,0) [0|1] "" Vector__XXX
 SG_ DI_a052_capability m52 : 17|1@1+ (1,0) [0|1] "" Vector__XXX
 SG_ DI_a052_power m52 : 18|1@1+ (1,0) [0|1] "" Vector__XXX
 SG_ DI_a052_status m52 : 19|1@1+ (1,0) [0|1] "" Vector__XXX
 SG_ DI_a052_capability2 m52 : 20|1@1+ (1,0) [0|1] "" Vector__XXX
 SG_ DI_a052_hvStatus m52 : 21|1@1+ (1,0) [0|1] "" Vector__XXX
 SG_ DI_a052_temperature m52 : 22|1@1+ (1,0) [0|1] "" Vector__XXX
 SG_ DI_a062_limpReason m62 : 16|6@1+ (1,0) [0|63] "" Vector__XXX
 SG_ DI_a063_gpoReason m63 : 16|4@1+ (1,0) [0|15] "" Vector__XXX
 SG_ DI_a064_hvState m64 : 16|3@1+ (1,0) [0|7] "" Vector__XXX
 SG_ DI_a064_vehiclePowerState m64 : 19|2@1+ (1,0) [0|3] "" Vector__XXX
 SG_ DI_a064_vehicleSpeed m64 : 24|12@1+ (0.08,-40) [-40|287.6] "kph" Vector__XXX
 SG_ DI_a074_recoveredGear m74 : 16|3@1+ (1,0) [0|6] "" Vector__XXX
 SG_ DI_a074_vehicleSpeed m74 : 19|12@1+ (0.08,-40) [-40|287.6] "kph" Vector__XXX
 SG_ DI_a074_attemptCount m74 : 32|4@1+ (1,0) [0|15] "" Vector__XXX
 SG_ DI_a074_unit0Gear m74 : 36|3@1+ (1,0) [0|6] "" Vector__XXX
 SG_ DI_a074_unit1Gear m74 : 40|3@1+ (1,0) [0|6] "" Vector__XXX
 SG_ DI_a074_unit2Gear m74 : 43|3@1+ (1,0) [0|6] "" Vector__XXX
 SG_ DI_a074_failureReason m74 : 48|4@1+ (1,0) [0|15] "" Vector__XXX
 SG_ DI_a074_epbSystemStatus m74 : 52|4@1+ (1,0) [0|14] "" Vector__XXX
 SG_ DI_a076_lvSupplyV m76 : 16|16@1+ (0.001,0) [0|65.535] "V" Vector__XXX
 SG_ DI_a077_lvSupplyV m77 : 16|16@1+ (0.001,0) [0|65.535] "V" Vector__XXX
 SG_ DI_a078_adcRefChan m78 : 16|4@1+ (1,0) [0|15] "" Vector__XXX
 SG_ DI_a078_adcRefLowAvg m78 : 24|16@1+ (1,0) [0|65535] "" Vector__XXX
 SG_ DI_a079_adcRefChan m79 : 16|4@1+ (1,0) [0|15] "" Vector__XXX
 SG_ DI_a079_adcRefHighAvg m79 : 24|16@1+ (1,0) [0|65535] "" Vector__XXX
 SG_ DI_a083_brakeSwitchNO m83 : 16|1@1+ (1,0) [0|1] "" Vector__XXX
 SG_ DI_a083_brakeSwitchNC m83 : 17|1@1+ (1,0) [0|1] "" Vector__XXX
 SG_ DI_a083_brakeSwitchIrrationalNO m83 : 18|1@1+ (1,0) [0|1] "" Vector__XXX
 SG_ DI_a083_brakeSwitchIrrationalNC m83 : 19|1@1+ (1,0) [0|1] "" Vector__XXX
 SG_ DI_a086_DPB_actuator3 m86 : 16|1@1+ (1,0) [0|1] "" Vector__XXX
 SG_ DI_a086_DPB_redundantBrakingStat m86 : 17|1@1+ (1,0) [0|1] "" Vector__XXX
 SG_ DI_a087_gtwCarConfig m87 : 16|1@1+ (1,0) [0|1] "" Vector__XXX
 SG_ DI_a087_gtwTime m87 : 17|1@1+ (1,0) [0|1] "" Vector__XXX
 SG_ DI_a087_gtwUpdateStatus m87 : 18|1@1+ (1,0) [0|1] "" Vector__XXX
 SG_ DI_a087_gearControl m87 : 19|1@1+ (1,0) [0|1] "" Vector__XXX
 SG_ DI_a087_carState m87 : 20|1@1+ (1,0) [0|1] "" Vector__XXX
 SG_ DI_a089_SCCM_rightStalk m89 : 16|1@1+ (1,0) [0|1] "" Vector__XXX
 SG_ DI_a090_reason m90 : 16|1@1+ (1,0) [0|1] "" Vector__XXX
 SG_ DI_a090_systemState m90 : 17|1@1+ (1,0) [0|1] "" Vector__XXX
 SG_ DI_a090_state m90 : 18|1@1+ (1,0) [0|1] "" Vector__XXX
 SG_ DI_a090_locState m90 : 19|1@1+ (1,0) [0|1] "" Vector__XXX
 SG_ DI_a090_state2 m90 : 20|1@1+ (1,0) [0|1] "" Vector__XXX
 SG_ DI_a090_state4 m90 : 21|1@1+ (1,0) [0|1] "" Vector__XXX
 SG_ DI_a091_ESP_brakeTorque m91 : 16|1@1+ (1,0) [0|1] "" Vector__XXX
 SG_ DI_a091_ESP_wheelSpeeds m91 : 17|1@1+ (1,0) [0|1] "" Vector__XXX
 SG_ DI_a091_ESP_wheelRotation m91 : 18|1@1+ (1,0) [0|1] "" Vector__XXX
 SG_ DI_a091_ESP_motorLimits m91 : 19|1@1+ (1,0) [0|1] "" Vector__XXX
 SG_ DI_a091_ESP_offsets m91 : 20|1@1+ (1,0) [0|1] "" Vector__XXX
 SG_ DI_a091_ESP_status m91 : 21|1@1+ (1,0) [0|1] "" Vector__XXX
 SG_ DI_a091_ESP_party3 m91 : 22|1@1+ (1,0) [0|1] "" Vector__XXX
 SG_ DI_a091_ESP_redundantBrakingStat m91 : 23|1@1+ (1,0) [0|1] "" Vector__XXX
 SG_ DI_a092_bmsStatus m92 : 16|1@1+ (1,0) [0|1] "" Vector__XXX
 SG_ DI_a092_bmsDriveLimits m92 : 17|1@1+ (1,0) [0|1] "" Vector__XXX
 SG_ DI_a092_bmsHvBusStatus m92 : 18|1@1+ (1,0) [0|1] "" Vector__XXX
 SG_ DI_a092_bmsPowerAvailable m92 : 19|1@1+ (1,0) [0|1] "" Vector__XXX
 SG_ DI_a092_bmsBmbMinMax m92 : 20|1@1+ (1,0) [0|1] "" Vector__XXX
 SG_ DI_a092_bmsSocStatus m92 : 21|1@1+ (1,0) [0|1] "" Vector__XXX
 SG_ DI_a092_bmsThermalStatus m92 : 22|1@1+ (1,0) [0|1] "" Vector__XXX
 SG_ DI_a092_bmsCtrStatus m92 : 23|1@1+ (1,0) [0|1] "" Vector__XXX
 SG_ DI_a092_bmsVoltageRegGain m92 : 24|1@1+ (1,0) [0|1] "" Vector__XXX
 SG_ DI_a092_bmsPackConfig m92 : 25|1@1+ (1,0) [0|1] "" Vector__XXX
 SG_ DI_a092_bmsSystemStatus m92 : 26|1@1+ (1,0) [0|1] "" Vector__XXX
 SG_ DI_a096_const_fast m96 : 16|1@1+ (1,0) [0|1] "" Vector__XXX
 SG_ DI_a096_text_fast m96 : 17|1@1+ (1,0) [0|1] "" Vector__XXX
 SG_ DI_a096_text_flash m96 : 18|1@1+ (1,0) [0|1] "" Vector__XXX
 SG_ DI_a096_mem_data m96 : 19|1@1+ (1,0) [0|1] "" Vector__XXX
 SG_ DI_a096_mem_regs m96 : 20|1@1+ (1,0) [0|1] "" Vector__XXX
 SG_ DI_a096_boot_flash m96 : 21|1@1+ (1,0) [0|1] "" Vector__XXX
 SG_ DI_a096_word1 m96 : 24|16@1+ (1,0) [0|65535] "" Vector__XXX
 SG_ DI_a096_word2 m96 : 40|16@1+ (1,0) [0|65535] "" Vector__XXX
 SG_ DI_a097_errorType m97 : 16|3@1+ (1,0) [0|7] "" Vector__XXX
 SG_ DI_a097_lineNumber m97 : 24|16@1+ (1,0) [0|65535] "" Vector__XXX
 SG_ DI_a097_argument m97 : 40|16@1+ (1,0) [0|65535] "" Vector__XXX
 SG_ DI_a098_page0Counter m98 : 16|8@1+ (1,0) [0|255] "" Vector__XXX
 SG_ DI_a098_page1Counter m98 : 24|8@1+ (1,0) [0|255] "" Vector__XXX
 SG_ DI_a098_page2Counter m98 : 32|8@1+ (1,0) [0|255] "" Vector__XXX
 SG_ DI_a098_pageID m98 : 40|2@1+ (1,0) [0|3] "" Vector__XXX
 SG_ DI_a098_recordID m98 : 42|4@1+ (1,0) [0|15] "" Vector__XXX
 SG_ DI_a098_errorCode m98 : 48|4@1+ (1,0) [0|15] "" Vector__XXX
 SG_ DI_a103_BB_status m103 : 16|1@1+ (1,0) [0|1] "" Vector__XXX
 SG_ DI_a103_BB_brakeActuation m103 : 17|1@1+ (1,0) [0|1] "" Vector__XXX
 SG_ DI_a104_proxIrrationalReason m104 : 16|1@1+ (1,0) [0|1] "" Vector__XXX
 SG_ DI_a105_cpStatus m105 : 16|1@1+ (1,0) [0|1] "" Vector__XXX
 SG_ DI_a110_EPBL_status m110 : 16|1@1+ (1,0) [0|1] "" Vector__XXX
 SG_ DI_a110_EPBR_status m110 : 17|1@1+ (1,0) [0|1] "" Vector__XXX
 SG_ DI_a110_EPBL_autonomyHealth m110 : 18|1@1+ (1,0) [0|1] "" Vector__XXX
 SG_ DI_a110_EPBR_autonomyHealth m110 : 19|1@1+ (1,0) [0|1] "" Vector__XXX
 SG_ DI_a120_blendingState m120 : 16|2@1+ (1,0) [0|3] "" Vector__XXX
 SG_ DI_a120_blendingUnavailableReaso m120 : 18|5@1+ (1,0) [0|31] "" Vector__XXX
 SG_ DI_a124_undrivenWheelMPH m124 : 16|16@1+ (0.1,0) [0|6553.5] "MPH" Vector__XXX
 SG_ DI_a124_cruiseFaultReason m124 : 32|5@1+ (1,0) [0|31] "" Vector__XXX
 SG_ DI_a124_cruiseFaultStack m124 : 37|3@1+ (1,0) [1|7] "" Vector__XXX
 SG_ DI_a125_maxDischargeCurrent m125 : 16|16@1- (0.1,0) [-3276.8|3276.7] "A" Vector__XXX
 SG_ DI_a125_maxChargeCurrent m125 : 32|16@1- (0.1,0) [-3276.8|3276.7] "A" Vector__XXX
 SG_ DI_a125_minBusVoltage m125 : 48|16@1+ (0.1,0) [0|6553.5] "V" Vector__XXX
 SG_ DI_a130_aebFaultReason m130 : 16|4@1+ (1,0) [0|15] "" Vector__XXX
 SG_ DI_a130_aebSmState m130 : 20|3@1+ (1,0) [0|7] "" Vector__XXX
 SG_ DI_a130_dasAebEvent m130 : 24|2@1+ (1,0) [0|2] "" Vector__XXX
 SG_ DI_a130_aebBrakeTorqueCommand m130 : 26|13@1+ (3,0) [0|24573] "Nm" Vector__XXX
 SG_ DI_a131_totalTimeRemaining m131 : 16|16@1+ (1,0) [0|65535] "" Vector__XXX
 SG_ DI_a131_warnSpeedLimit m131 : 32|16@1+ (1,0) [0|65535] "RPM" Vector__XXX
 SG_ DI_a131_warnTimeRemaining m131 : 48|16@1+ (1,0) [0|65535] "" Vector__XXX
 SG_ DI_a133_vhldSmState m133 : 16|4@1+ (1,0) [0|15] "" Vector__XXX
 SG_ DI_a133_reverseGear m133 : 20|1@1+ (1,0) [0|1] "" Vector__XXX
 SG_ DI_a133_vhldGrade m133 : 24|8@1+ (0.01,-1) [-1|1.55] "G" Vector__XXX
 SG_ DI_a134_wheelSpeedDiffFrL m134 : 16|12@1- (0.0625,0) [-128|127.9375] "kph" Vector__XXX
 SG_ DI_a134_wheelSpeedDiffFrR m134 : 28|12@1- (0.0625,0) [-128|127.9375] "kph" Vector__XXX
 SG_ DI_a134_wheelSpeedDiffReL m134 : 40|12@1- (0.0625,0) [-128|127.9375] "kph" Vector__XXX
 SG_ DI_a134_wheelSpeedDiffReR m134 : 52|12@1- (0.0625,0) [-128|127.9375] "kph" Vector__XXX
 SG_ DI_a135_vhldFaultReason m135 : 16|4@1+ (1,0) [0|15] "" Vector__XXX
 SG_ DI_a135_vhldSmState m135 : 20|4@1+ (1,0) [0|15] "" Vector__XXX
 SG_ DI_a135_vhldBrakeApply m135 : 24|1@1+ (1,0) [0|1] "" Vector__XXX
 SG_ DI_a135_vhldBrakeTorqueCommand m135 : 25|10@1+ (10,0) [0|10230] "Nm" Vector__XXX
 SG_ DI_a135_vhldTotalBrakeTorque m135 : 35|10@1+ (10,0) [0|10230] "Nm" Vector__XXX
 SG_ DI_a135_vhldPropulsiveTorque m135 : 45|10@1- (1,0) [-512|511] "Nm" Vector__XXX
 SG_ DI_a135_vhldGrade m135 : 56|8@1+ (0.01,-1) [-1|1.55] "G" Vector__XXX
 SG_ DI_a140_PTC_feedbackStatus m140 : 16|1@1+ (1,0) [0|1] "" Vector__XXX
 SG_ DI_a141_DAS_control m141 : 16|1@1+ (1,0) [0|1] "" Vector__XXX
 SG_ DI_a141_DAS_pmmControl m141 : 17|1@1+ (1,0) [0|1] "" Vector__XXX
 SG_ DI_a141_DAS_status m141 : 18|1@1+ (1,0) [0|1] "" Vector__XXX
 SG_ DI_a141_DAS_status2 m141 : 19|1@1+ (1,0) [0|1] "" Vector__XXX
 SG_ DI_a141_DAS_smartShift m141 : 20|1@1+ (1,0) [0|1] "" Vector__XXX
 SG_ DI_a141_DAS_longControl m141 : 21|1@1+ (1,0) [0|1] "" Vector__XXX
 SG_ DI_a141_DAS_longControlTuningPar m141 : 22|1@1+ (1,0) [0|1] "" Vector__XXX
 SG_ DI_a141_DAS_autonomyControl m141 : 23|1@1+ (1,0) [0|1] "" Vector__XXX
 SG_ DI_a141_DAS_redundantBrakingCont m141 : 24|1@1+ (1,0) [0|1] "" Vector__XXX
 SG_ DI_a143_mechPowerLimit m143 : 16|1@1+ (1,0) [0|1] "" Vector__XXX
 SG_ DI_a143_systemTorqueLimit m143 : 17|1@1+ (1,0) [0|1] "" Vector__XXX
 SG_ DI_a144_autopilot m144 : 16|1@1+ (1,0) [0|1] "" Vector__XXX
 SG_ DI_a144_chassisType m144 : 17|1@1+ (1,0) [0|1] "" Vector__XXX
 SG_ DI_a144_drivetrainType m144 : 18|1@1+ (1,0) [0|1] "" Vector__XXX
 SG_ DI_a144_packEnergy m144 : 19|1@1+ (1,0) [0|1] "" Vector__XXX
 SG_ DI_a144_packPerformanceDeviation m144 : 20|1@1+ (1,0) [0|1] "" Vector__XXX
 SG_ DI_a144_performancePackage m144 : 21|1@1+ (1,0) [0|1] "" Vector__XXX
 SG_ DI_a144_vdcType m144 : 22|1@1+ (1,0) [0|1] "" Vector__XXX
 SG_ DI_a144_brakeHWType m144 : 23|1@1+ (1,0) [0|1] "" Vector__XXX
 SG_ DI_a144_inverterHardware m144 : 24|1@1+ (1,0) [0|1] "" Vector__XXX
 SG_ DI_a144_cabinPTCHeaterType m144 : 25|1@1+ (1,0) [0|1] "" Vector__XXX
 SG_ DI_a144_frunkLatchType m144 : 26|1@1+ (1,0) [0|1] "" Vector__XXX
 SG_ DI_a144_platformMaxBusVoltage m144 : 27|1@1+ (1,0) [0|1] "" Vector__XXX
 SG_ DI_a144_oilPump1HwType m144 : 28|1@1+ (1,0) [0|1] "" Vector__XXX
 SG_ DI_a144_oilPump2HwType m144 : 29|1@1+ (1,0) [0|1] "" Vector__XXX
 SG_ DI_a144_heatsinkType m144 : 30|1@1+ (1,0) [0|1] "" Vector__XXX
 SG_ DI_a144_softPerformanceLimit m144 : 31|1@1+ (1,0) [0|1] "" Vector__XXX
 SG_ DI_a144_brakeActuationType m144 : 32|1@1+ (1,0) [0|1] "" Vector__XXX
 SG_ DI_a144_dasHw m144 : 33|1@1+ (1,0) [0|1] "" Vector__XXX
 SG_ DI_a144_powerLiftgateType m144 : 34|1@1+ (1,0) [0|1] "" Vector__XXX
 SG_ DI_a144_chassisSubType m144 : 35|1@1+ (1,0) [0|1] "" Vector__XXX
 SG_ DI_a144_autonomyFeatureType m144 : 36|1@1+ (1,0) [0|1] "" Vector__XXX
 SG_ DI_a146_panicReason m146 : 16|3@1+ (1,0) [0|7] "" Vector__XXX
 SG_ DI_a155_sensors m155 : 16|1@1+ (1,0) [0|1] "" Vector__XXX
 SG_ DI_a155_coolant m155 : 17|1@1+ (1,0) [0|1] "" Vector__XXX
 SG_ DI_a155_LVPowerState m155 : 18|1@1+ (1,0) [0|1] "" Vector__XXX
 SG_ DI_a155_vehicleStatus m155 : 19|1@1+ (1,0) [0|1] "" Vector__XXX
 SG_ DI_a155_status m155 : 20|1@1+ (1,0) [0|1] "" Vector__XXX
 SG_ DI_a155_leftDoorStatus m155 : 21|1@1+ (1,0) [0|1] "" Vector__XXX
 SG_ DI_a155_rightDoorStatus m155 : 22|1@1+ (1,0) [0|1] "" Vector__XXX
 SG_ DI_a155_vcleftSwitchStatus m155 : 23|1@1+ (1,0) [0|1] "" Vector__XXX
 SG_ DI_a155_restraintStatus m155 : 24|1@1+ (1,0) [0|1] "" Vector__XXX
 SG_ DI_a155_systemStatus m155 : 25|1@1+ (1,0) [0|1] "" Vector__XXX
 SG_ DI_a155_prndStatus m155 : 26|1@1+ (1,0) [0|1] "" Vector__XXX
 SG_ DI_a155_liftgateStatus m155 : 27|1@1+ (1,0) [0|1] "" Vector__XXX
 SG_ DI_a157_RCM_inertial1 m157 : 16|1@1+ (1,0) [0|1] "" Vector__XXX
 SG_ DI_a157_RCM_inertial2 m157 : 17|1@1+ (1,0) [0|1] "" Vector__XXX
 SG_ DI_a158_IBST_party1 m158 : 16|1@1+ (1,0) [0|1] "" Vector__XXX
 SG_ DI_a158_BUS1_IBST_status m158 : 17|1@1+ (1,0) [0|1] "" Vector__XXX
 SG_ DI_a158_BUS2_IBST_status m158 : 18|1@1+ (1,0) [0|1] "" Vector__XXX
 SG_ DI_a158_IBST_redundantBrakingSta m158 : 19|1@1+ (1,0) [0|1] "" Vector__XXX
 SG_ DI_a160_kTire m160 : 16|7@1+ (0.001,0.008) [0.008|0.135] "-" Vector__XXX
 SG_ DI_a160_tireFitment m160 : 24|2@1+ (1,0) [0|2] "" Vector__XXX
 SG_ DI_a160_wearFactorFrL m160 : 26|6@1+ (0.00125,0.96) [0.96|1.03875] "ratio" Vector__XXX
 SG_ DI_a160_wearFactorFrR m160 : 32|6@1+ (0.00125,0.96) [0.96|1.03875] "ratio" Vector__XXX
 SG_ DI_a160_wearFactorReL m160 : 40|6@1+ (0.00125,0.96) [0.96|1.03875] "ratio" Vector__XXX
 SG_ DI_a160_distanceSinceLastTireCon m160 : 48|12@1+ (0.01,0) [0|40.94] "km" Vector__XXX
 SG_ DI_a161_EPAS3P_sysStatus m161 : 16|1@1+ (1,0) [0|1] "" Vector__XXX
 SG_ DI_a161_EPAS3P_angleCalib m161 : 17|1@1+ (1,0) [0|1] "" Vector__XXX
 SG_ DI_a162_shiftDeniedReason m162 : 16|4@1+ (1,0) [0|15] "" Vector__XXX
 SG_ DI_a162_motorSpeed m162 : 20|10@1- (0.2,0) [-102.4|102.2] "MPH" Vector__XXX
 SG_ DI_a162_essContClosed m162 : 30|1@1+ (1,0) [0|1] "" Vector__XXX
 SG_ DI_a162_autonomyBehavior m162 : 31|2@1+ (1,0) [0|3] "" Vector__XXX
 SG_ DI_a162_pedalPos m162 : 33|7@1+ (0.8,0) [0|101.6] "%" Vector__XXX
 SG_ DI_a162_currentGear m162 : 40|3@1+ (1,0) [0|6] "" Vector__XXX
 SG_ DI_a162_requestedGear m162 : 43|3@1+ (1,0) [0|6] "" Vector__XXX
 SG_ DI_a162_requestSource m162 : 46|4@1+ (1,0) [0|15] "" Vector__XXX
 SG_ DI_a162_timeSinceCruiseCancel m162 : 50|7@1+ (0.5,0) [0|63.5] "second" Vector__XXX
 SG_ DI_a162_chargeCableConnected m162 : 57|1@1+ (1,0) [0|1] "" Vector__XXX
 SG_ DI_a162_frunkOpen m162 : 58|1@1+ (1,0) [0|1] "" Vector__XXX
 SG_ DI_a162_sysStateExitCondition m162 : 59|5@1+ (1,0) [0|31] "" Vector__XXX
 SG_ DI_a163_motorSpeed m163 : 16|16@1- (0.01,0) [-327.68|327.67] "MPH" Vector__XXX
 SG_ DI_a163_currentGear m163 : 32|3@1+ (1,0) [0|6] "" Vector__XXX
 SG_ DI_a163_requestedGear m163 : 35|3@1+ (1,0) [0|6] "" Vector__XXX
 SG_ DI_a163_requestSource m163 : 40|4@1+ (1,0) [0|15] "" Vector__XXX
 SG_ DI_a164_motorSpeed m164 : 16|16@1- (0.01,0) [-327.68|327.67] "MPH" Vector__XXX
 SG_ DI_a164_pedalPos m164 : 32|8@1+ (0.4,0) [0|102] "%" Vector__XXX
 SG_ DI_a164_torqueDriver m164 : 40|14@1- (0.2,0) [-1638.4|1638.2] "Nm" Vector__XXX
 SG_ DI_a170_tireSeasonSelected m170 : 16|1@1+ (1,0) [0|1] "" Vector__XXX
 SG_ DI_a170_kTire m170 : 17|7@1+ (0.001,0.008) [0.008|0.135] "-" Vector__XXX
 SG_ DI_a170_tireFitment m170 : 24|2@1+ (1,0) [0|2] "" Vector__XXX
 SG_ DI_a170_wearFactorFrL m170 : 26|6@1+ (0.00125,0.96) [0.96|1.03875] "ratio" Vector__XXX
 SG_ DI_a170_wearFactorFrR m170 : 32|6@1+ (0.00125,0.96) [0.96|1.03875] "ratio" Vector__XXX
 SG_ DI_a170_wearFactorReL m170 : 38|6@1+ (0.00125,0.96) [0.96|1.03875] "ratio" Vector__XXX
 SG_ DI_a170_odometer m170 : 44|12@1+ (500,0) [0|2047000] "km" Vector__XXX
 SG_ DI_a170_distanceSinceLastTireCon m170 : 56|6@1+ (500,0) [0|31000] "km" Vector__XXX
 SG_ DI_a170_treadDepthAlertSet m170 : 62|1@1+ (1,0) [0|1] "" Vector__XXX
 SG_ DI_a172_motorSpeed m172 : 16|16@1- (0.01,0) [-327.68|327.67] "MPH" Vector__XXX
 SG_ DI_a172_pedalPos m172 : 32|8@1+ (0.4,0) [0|102] "%" Vector__XXX
 SG_ DI_a172_currentGear m172 : 40|3@1+ (1,0) [0|6] "" Vector__XXX
 SG_ DI_a172_timeSinceCruiseCancel m172 : 48|7@1+ (0.5,0) [0|63.5] "second" Vector__XXX
 SG_ DI_a173_brakeApply m173 : 16|16@1- (0.01,0) [-327.68|327.67] "bar" Vector__XXX
 SG_ DI_a173_pedalPos m173 : 32|8@1+ (0.4,0) [0|102] "%" Vector__XXX
 SG_ DI_a175_crsNotAvailableReason m175 : 16|6@1+ (1,0) [0|63] "" Vector__XXX
 SG_ DI_a175_crsNotAvailableStack m175 : 24|3@1+ (1,0) [1|7] "" Vector__XXX
 SG_ DI_a177_newFitment m177 : 16|2@1+ (1,0) [0|2] "" Vector__XXX
 SG_ DI_a178_offsetValue m178 : 16|8@1- (0.16,0) [-20.48|20.32] "deg" Vector__XXX
 SG_ DI_a180_crsNotAvailableReason m180 : 16|6@1+ (1,0) [0|63] "" Vector__XXX
 SG_ DI_a184_apcCancelReason m184 : 16|5@1+ (1,0) [0|31] "" Vector__XXX
 SG_ DI_a184_apcUnavailableReason m184 : 24|4@1+ (1,0) [0|15] "" Vector__XXX
 SG_ DI_a184_autoparkInternalState m184 : 32|5@1+ (1,0) [0|31] "" Vector__XXX
 SG_ DI_a185_summonActive m185 : 16|1@1+ (1,0) [0|1] "" Vector__XXX
 SG_ DI_a185_apcCancelReason m185 : 17|5@1+ (1,0) [0|31] "" Vector__XXX
 SG_ DI_a185_apcUnavailableReason m185 : 24|4@1+ (1,0) [0|15] "" Vector__XXX
 SG_ DI_a185_crsNotAvailableReason m185 : 32|6@1+ (1,0) [0|63] "" Vector__XXX
 SG_ DI_a185_crsFaultReason m185 : 40|5@1+ (1,0) [0|31] "" Vector__XXX
 SG_ DI_a185_autoparkInternalState m185 : 48|5@1+ (1,0) [0|31] "" Vector__XXX
 SG_ DI_a187_filteredAccel m187 : 16|16@1- (0.01,0) [-327.68|327.67] "m/s^2" Vector__XXX
 SG_ DI_a187_rawPedal m187 : 32|8@1+ (0.4,0) [0|102] "%" Vector__XXX
 SG_ DI_a187_systemTorqueCommand m187 : 40|16@1- (1,0) [-32768|32767] "Nm" Vector__XXX
 SG_ DI_a189_accelPedal m189 : 16|5@1+ (3.125,0) [0|96.875] "%" Vector__XXX
 SG_ DI_a189_grade m189 : 24|4@1- (4,0) [-32|28] "%" Vector__XXX
 SG_ DI_a189_brakePressed m189 : 28|1@1+ (1,0) [0|1] "" Vector__XXX
 SG_ DI_a189_systemTorque m189 : 32|8@1- (10,0) [-1280|1270] "Nm" Vector__XXX
 SG_ DI_a189_motorSpeed m189 : 40|5@1- (0.5,0) [-8|7.5] "MPH" Vector__XXX
 SG_ DI_a190_relativeTireTreadDepth m190 : 16|6@1+ (0.2,0) [0|12.6] "mm" Vector__XXX
 SG_ DI_a190_treadWearFactorFrL m190 : 24|6@1+ (0.001,0.969) [0.969|1.032] "ratio" Vector__XXX
 SG_ DI_a190_treadWearFactorFrR m190 : 32|6@1+ (0.001,0.969) [0.969|1.032] "ratio" Vector__XXX
 SG_ DI_a190_treadWearFactorReL m190 : 40|6@1+ (0.001,0.969) [0.969|1.032] "ratio" Vector__XXX
 SG_ DI_a190_treadWearFactorAvgConfid m190 : 48|5@1+ (0.05,0) [0|1.55] "ratio" Vector__XXX
 SG_ DI_a190_tireFitment m190 : 53|2@1+ (1,0) [0|2] "" Vector__XXX
 SG_ DI_a191_motorSpeed m191 : 16|16@1- (0.01,0) [-327.68|327.67] "MPH" Vector__XXX
 SG_ DI_a191_reverseDeniedAfterCruise m191 : 32|1@1+ (1,0) [0|1] "" Vector__XXX
 SG_ DI_a191_currentGear m191 : 33|3@1+ (1,0) [0|6] "" Vector__XXX
 SG_ DI_a191_requestedGear m191 : 36|3@1+ (1,0) [0|6] "" Vector__XXX
 SG_ DI_a191_requestSource m191 : 40|4@1+ (1,0) [0|15] "" Vector__XXX
 SG_ DI_a191_timeSinceCruiseCancel m191 : 48|7@1+ (0.5,0) [0|63.5] "second" Vector__XXX
 SG_ DI_a193_brakeTorqueFrL m193 : 16|3@1+ (1,0) [0|7] "" Vector__XXX
 SG_ DI_a193_brakeTorqueFrLLastVal m193 : 19|10@1+ (12,0) [0|12276] "Nm" Vector__XXX
 SG_ DI_a193_brakeTorqueFrLCurrVal m193 : 29|10@1+ (12,0) [0|12276] "Nm" Vector__XXX
 SG_ DI_a193_brakeTorqueFrR m193 : 40|3@1+ (1,0) [0|7] "" Vector__XXX
 SG_ DI_a193_brakeTorqueFrRLastVal m193 : 43|10@1+ (12,0) [0|12276] "Nm" Vector__XXX
 SG_ DI_a193_brakeTorqueFrRCurrVal m193 : 53|10@1+ (12,0) [0|12276] "Nm" Vector__XXX
 SG_ DI_a194_brakeTorqueReL m194 : 16|3@1+ (1,0) [0|7] "" Vector__XXX
 SG_ DI_a194_brakeTorqueReLLastVal m194 : 19|10@1+ (12,0) [0|12276] "Nm" Vector__XXX
 SG_ DI_a194_brakeTorqueReLCurrVal m194 : 29|10@1+ (12,0) [0|12276] "Nm" Vector__XXX
 SG_ DI_a194_brakeTorqueReR m194 : 40|3@1+ (1,0) [0|7] "" Vector__XXX
 SG_ DI_a194_brakeTorqueReRLastVal m194 : 43|10@1+ (12,0) [0|12276] "Nm" Vector__XXX
 SG_ DI_a194_brakeTorqueReRCurrVal m194 : 53|10@1+ (12,0) [0|12276] "Nm" Vector__XXX
 SG_ DI_a198_MCPressure m198 : 16|3@1+ (1,0) [0|7] "" Vector__XXX
 SG_ DI_a198_MCPressureLastValue m198 : 19|10@1- (0.3,123.6) [-30|276.9] "bar" Vector__XXX
 SG_ DI_a198_MCPressCurrValue m198 : 29|10@1- (0.3,123.6) [-30|276.9] "bar" Vector__XXX
 SG_ DI_a198_steeringAngle m198 : 40|3@1+ (1,0) [0|7] "" Vector__XXX
 SG_ DI_a198_steeringAngleLastVal m198 : 43|10@1- (1.6,0) [-819.2|817.6] "deg" Vector__XXX
 SG_ DI_a198_steeringAngleCurrVal m198 : 53|10@1- (1.6,0) [-819.2|817.6] "deg" Vector__XXX
 SG_ DI_a199_muVehicleLearnDown m199 : 16|5@1+ (0.05,0) [0|1.55] "-" Vector__XXX
 SG_ DI_a199_muVehicleDecFilt m199 : 21|5@1+ (0.05,0) [0|1.55] "-" Vector__XXX
 SG_ DI_a199_bankAngle m199 : 26|6@1- (0.016,0) [-0.512|0.496] "rad" Vector__XXX
 SG_ DI_a199_lateralAccelFilt m199 : 32|6@1- (0.5,0) [-16|15.5] "m/s^2" Vector__XXX
 SG_ DI_a199_driverIntendedYawRate m199 : 38|7@1- (0.024,0) [-1.536|1.512] "rad/s" Vector__XXX
 SG_ DI_a199_vehicleVelocity m199 : 45|5@1+ (2,0) [0|62] "m/s" Vector__XXX
 SG_ DI_a199_sensorYawRate m199 : 50|7@1- (0.024,0) [-1.536|1.512] "rad/s" Vector__XXX
 SG_ DI_a199_preControlActive m199 : 57|1@1+ (1,0) [0|1] "" Vector__XXX
 SG_ DI_a199_oversteerdMzActive m199 : 58|1@1+ (1,0) [0|1] "" Vector__XXX
 SG_ DI_a199_decelControlActive m199 : 59|1@1+ (1,0) [0|1] "" Vector__XXX
 SG_ DI_a199_understeerdMzActive m199 : 60|1@1+ (1,0) [0|1] "" Vector__XXX
 SG_ DI_a199_vdcMode m199 : 61|2@1+ (1,0) [0|3] "" Vector__XXX
 SG_ DI_a200_MBPCheckStatus m200 : 16|1@1+ (1,0) [0|1] "" Vector__XXX
 SG_ DI_a200_MBPFailedCase m200 : 17|6@1+ (1,0) [0|63] "" Vector__XXX
 SG_ DI_a200_MBPFaultProbability m200 : 24|10@1+ (0.008,0) [0|8.184] "-" Vector__XXX
 SG_ DI_a202_reason m202 : 16|4@1+ (1,0) [0|15] "" Vector__XXX
 SG_ DI_a202_movement m202 : 20|9@1+ (0.005,0) [0|2.555] "m" Vector__XXX
 SG_ DI_a202_sysStateExitCondition m202 : 32|5@1+ (1,0) [0|31] "" Vector__XXX
 SG_ DI_a203_ptcStateLocal m203 : 16|3@1+ (1,0) [0|7] "" Vector__XXX
 SG_ DI_a203_btcState m203 : 19|1@1+ (1,0) [0|1] "" Vector__XXX
 SG_ DI_a204_longAccel m204 : 16|3@1+ (1,0) [0|7] "" Vector__XXX
 SG_ DI_a204_longAccelLastVal m204 : 19|10@1- (0.08,0) [-40.96|40.88] "m/s^2" Vector__XXX
 SG_ DI_a204_longAccelCurrVal m204 : 29|10@1- (0.08,0) [-40.96|40.88] "m/s^2" Vector__XXX
 SG_ DI_a204_rollRate m204 : 40|3@1+ (1,0) [0|7] "" Vector__XXX
 SG_ DI_a204_rollRateLastVal m204 : 43|10@1- (0.006,0) [-3.072|3.066] "rad/s" Vector__XXX
 SG_ DI_a204_rollRateCurrVal m204 : 53|10@1- (0.006,0) [-3.072|3.066] "rad/s" Vector__XXX
 SG_ DI_a205_latAccel m205 : 16|3@1+ (1,0) [0|7] "" Vector__XXX
 SG_ DI_a205_latAccelLastVal m205 : 19|10@1- (0.08,0) [-40.96|40.88] "m/s^2" Vector__XXX
 SG_ DI_a205_latAccelCurrVal m205 : 29|10@1- (0.08,0) [-40.96|40.88] "m/s^2" Vector__XXX
 SG_ DI_a205_pitchRate m205 : 40|3@1+ (1,0) [0|7] "" Vector__XXX
 SG_ DI_a205_pitchRateLastVal m205 : 43|10@1- (0.006,0) [-3.072|3.066] "rad/s" Vector__XXX
 SG_ DI_a205_pitchRateCurrVal m205 : 53|10@1- (0.006,0) [-3.072|3.066] "rad/s" Vector__XXX
 SG_ DI_a206_verticalAccel m206 : 16|3@1+ (1,0) [0|7] "" Vector__XXX
 SG_ DI_a206_verticalAccelLastVal m206 : 19|10@1- (0.08,0) [-40.96|40.88] "m/s^2" Vector__XXX
 SG_ DI_a206_verticalAccelCurrVal m206 : 29|10@1- (0.08,0) [-40.96|40.88] "m/s^2" Vector__XXX
 SG_ DI_a206_yawRate m206 : 40|3@1+ (1,0) [0|7] "" Vector__XXX
 SG_ DI_a206_yawRateLastVal m206 : 43|10@1- (0.006,0) [-3.072|3.066] "rad/s" Vector__XXX
 SG_ DI_a206_yawRateCurrVal m206 : 53|10@1- (0.006,0) [-3.072|3.066] "rad/s" Vector__XXX
 SG_ DI_a210_ptcStateGlobal m210 : 16|2@1+ (1,0) [0|2] "" Vector__XXX
 SG_ DI_a210_espActuatorState m210 : 18|2@1+ (1,0) [0|3] "" Vector__XXX
 SG_ DI_a210_brakeTmpEstStateFaulted m210 : 20|1@1+ (1,0) [0|1] "" Vector__XXX
 SG_ DI_a210_secondaryBrakeActuatorIs m210 : 21|1@1+ (1,0) [0|1] "" Vector__XXX
 SG_ DI_a223_ptcStateLocal m223 : 16|3@1+ (1,0) [0|7] "" Vector__XXX
 SG_ DI_a223_btcState m223 : 19|1@1+ (1,0) [0|1] "" Vector__XXX
 SG_ DI_a223_velocityEstimatorState m223 : 20|3@1+ (1,0) [0|7] "" Vector__XXX
 SG_ DI_a223_addState_dir m223 : 24|2@1+ (1,0) [0|3] "" Vector__XXX
 SG_ DI_a223_addState_dif m223 : 26|2@1+ (1,0) [0|3] "" Vector__XXX
 SG_ DI_a223_DI_tractionControlMode m223 : 28|3@1+ (1,0) [0|7] "" Vector__XXX
 SG_ DI_a223_UI_tractionControlMode m223 : 32|3@1+ (1,0) [0|7] "" Vector__XXX
 SG_ DI_a223_vehicleVelocity m223 : 40|7@1- (1,48) [-16|111] "m/s" Vector__XXX
 SG_ DI_a223_musurf m223 : 48|4@1+ (0.1,0) [0|1.5] "-" Vector__XXX
 SG_ DI_a223_musurfHigh m223 : 52|4@1+ (0.1,0) [0|1.5] "-" Vector__XXX
 SG_ DI_a223_driveTCActive m223 : 56|1@1+ (1,0) [0|1] "" Vector__XXX
 SG_ DI_a223_regenTCActive m223 : 57|1@1+ (1,0) [0|1] "" Vector__XXX
 SG_ DI_a223_surfaceUtility m223 : 58|3@1+ (15,0) [0|105] "%" Vector__XXX
 SG_ DI_a224_brakeFLTemp m224 : 16|10@1- (1,300) [-212|811] "degC" Vector__XXX
 SG_ DI_a224_brakeFRTemp m224 : 26|10@1- (1,300) [-212|811] "degC" Vector__XXX
 SG_ DI_a224_brakeRLTemp m224 : 36|10@1- (1,300) [-212|811] "degC" Vector__XXX
 SG_ DI_a224_brakeRRTemp m224 : 46|10@1- (1,300) [-212|811] "degC" Vector__XXX
 SG_ DI_a227_hvState m227 : 16|3@1+ (1,0) [0|7] "" Vector__XXX
 SG_ DI_a227_vehiclePowerState m227 : 19|2@1+ (1,0) [0|3] "" Vector__XXX
 SG_ DI_a230_CMP_HVStatus m230 : 16|1@1+ (1,0) [0|1] "" Vector__XXX
 SG_ DI_a230_CMPD_state m230 : 17|1@1+ (1,0) [0|1] "" Vector__XXX
 SG_ DI_a232_velocityEstimatorState m232 : 16|3@1+ (1,0) [0|7] "" Vector__XXX
 SG_ DI_a232_UI_tractionControlMode m232 : 19|3@1+ (1,0) [0|7] "" Vector__XXX
 SG_ DI_a232_vehicleVelocity m232 : 24|6@1+ (1,0) [0|63] "m/s" Vector__XXX
 SG_ DI_a232_musurf m232 : 32|3@1+ (0.15,0.15) [0.15|1.2] "-" Vector__XXX
 SG_ DI_a232_musurfHigh m232 : 35|3@1+ (0.15,0.15) [0.15|1.2] "-" Vector__XXX
 SG_ DI_a232_allWhlSpeedRotationAvail m232 : 38|1@1+ (1,0) [0|1] "" Vector__XXX
 SG_ DI_a232_BrakeMasterCylPressValid m232 : 39|1@1+ (1,0) [0|1] "" Vector__XXX
 SG_ DI_a232_WheelBrakeTorquesValid m232 : 40|1@1+ (1,0) [0|1] "" Vector__XXX
 SG_ DI_a232_AbsBrakeEventActiveValid m232 : 41|1@1+ (1,0) [0|1] "" Vector__XXX
 SG_ DI_a232_UndersteerActiveValid m232 : 42|1@1+ (1,0) [0|1] "" Vector__XXX
 SG_ DI_a232_OversteerActiveValid m232 : 43|1@1+ (1,0) [0|1] "" Vector__XXX
 SG_ DI_a232_allMotorTorquesValid m232 : 44|1@1+ (1,0) [0|1] "" Vector__XXX
 SG_ DI_a232_lateralAccelValid m232 : 45|1@1+ (1,0) [0|1] "" Vector__XXX
 SG_ DI_a232_longitudinalAccelValid m232 : 46|1@1+ (1,0) [0|1] "" Vector__XXX
 SG_ DI_a232_yawRateValid m232 : 47|1@1+ (1,0) [0|1] "" Vector__XXX
 SG_ DI_a232_steerAngleValid m232 : 48|1@1+ (1,0) [0|1] "" Vector__XXX
 SG_ DI_a236_states m236 : 16|1@1+ (1,0) [0|1] "" Vector__XXX
 SG_ DI_a237_lateralAccel m237 : 16|8@1- (0.25,0) [-32|31.75] "m/s^2" Vector__XXX
 SG_ DI_a237_verticalAccel m237 : 24|8@1- (0.25,0) [-32|31.75] "m/s^2" Vector__XXX
 SG_ DI_a237_longitudinalAccel m237 : 32|8@1- (0.25,0) [-32|31.75] "m/s^2" Vector__XXX
 SG_ DI_a237_vehicleSpeed m237 : 40|6@1+ (1,0) [0|63] "m/s" Vector__XXX
 SG_ DI_a239_numRequests m239 : 16|16@1+ (1,0) [0|65535] "" Vector__XXX
 SG_ DI_a243_RCU_status m243 : 16|1@1+ (1,0) [0|1] "" Vector__XXX
 SG_ DI_a243_RCU_actuation m243 : 17|1@1+ (1,0) [0|1] "" Vector__XXX
 SG_ DI_a245_ebrStatus m245 : 16|2@1+ (1,0) [0|3] "" Vector__XXX
 SG_ DI_a245_vehicleHoldState m245 : 18|3@1+ (1,0) [0|7] "" Vector__XXX
 SG_ DI_a246_onePedalDrivingState m246 : 16|4@1+ (1,0) [0|15] "" Vector__XXX
 SG_ DI_a246_opdUnavailableReason m246 : 24|5@1+ (1,0) [0|31] "" Vector__XXX
 SG_ DI_a249_learning_DIF m249 : 16|1@1+ (1,0) [0|1] "" Vector__XXX
 SG_ DI_a249_learning_DIR m249 : 17|1@1+ (1,0) [0|1] "" Vector__XXX
 SG_ DI_a250_tasRequest m250 : 16|1@1+ (1,0) [0|1] "" Vector__XXX
 SG_ DI_a250_tasMIA m250 : 17|1@1+ (1,0) [0|1] "" Vector__XXX

BO_TX_BU_ 935 : DIR;
BO_TX_BU_ 2005 : DIR;
BO_TX_BU_ 633 : DIR;
BO_TX_BU_ 821 : DIR;
BO_TX_BU_ 2037 : DIR;
BO_TX_BU_ 917 : DIR;
BO_TX_BU_ 614 : DIR;
BO_TX_BU_ 598 : DIR;
BO_TX_BU_ 789 : DIR;
BO_TX_BU_ 1495 : DIR;
BO_TX_BU_ 264 : DIR;
BO_TX_BU_ 1558 : DIR;
BO_TX_BU_ 1319 : DI;
CM_ BO_ 935 "Rear drive inverter message: alert matrix";
CM_ SG_ 935 DIR_matrixIndex "Rear drive inverter: matrix index";
CM_ SG_ 935 DIR_a001_hwPhaseAgateDrive "Rear drive inverter: a001 hw phase agate drive";
CM_ SG_ 935 DIR_a002_hwPhaseBgateDrive "Rear drive inverter: a002 hw phase bgate drive";
CM_ SG_ 935 DIR_a003_hwPhaseCgateDrive "Rear drive inverter: a003 hw phase cgate drive";
CM_ SG_ 935 DIR_a004_hwPhaseApeak "Rear drive inverter: a004 hw phase apeak";
CM_ SG_ 935 DIR_a005_hwPhaseBpeak "Rear drive inverter: a005 hw phase bpeak";
CM_ SG_ 935 DIR_a006_hwPhaseCpeak "Rear drive inverter: a006 hw phase cpeak";
CM_ SG_ 935 DIR_a007_statorAnomalyDetected "Rear drive inverter: a007 stator anomaly detected";
CM_ SG_ 935 DIR_a008_hwEncoderA "Rear drive inverter: a008 hw encoder a";
CM_ SG_ 935 DIR_a009_hwEncoderB "Rear drive inverter: a009 hw encoder b";
CM_ SG_ 935 DIR_a010_unintendedReset "Rear drive inverter: a010 unintended reset";
CM_ SG_ 935 DIR_a011_swPowerStageNotReady "Rear drive inverter: a011 sw power stage not ready";
CM_ SG_ 935 DIR_a012_hvilNotClosed "Rear drive inverter: a012 hvil not closed";
CM_ SG_ 935 DIR_a013_eccError "Rear drive inverter: a013 ecc error";
CM_ SG_ 935 DIR_a014_activeDamping "Rear drive inverter: a014 active damping";
CM_ SG_ 935 DIR_a015_mechSafeStateAnomaly "Rear drive inverter: a015 mech safe state anomaly";
CM_ SG_ 935 DIR_a016_safeStateApplied "Rear drive inverter: a016 safe state applied";
CM_ SG_ 935 DIR_a017_hwPedalMonitor "Rear drive inverter: a017 hw pedal monitor";
CM_ SG_ 935 DIR_a018_hwLVSupplyUV "Rear drive inverter: a018 hw LV supply UV";
CM_ SG_ 935 DIR_a020_hwMotorEncoder "Rear drive inverter: a020 hw motor encoder";
CM_ SG_ 935 DIR_a021_hwBusOV "Rear drive inverter: a021 hw bus OV";
CM_ SG_ 935 DIR_a022_hw5vSupplyUV "Rear drive inverter: a022 hw5v supply UV";
CM_ SG_ 935 DIR_a024_selfTest "Rear drive inverter: a024 self test";
CM_ SG_ 935 DIR_a025_phaseApeak "Rear drive inverter: a025 phase apeak";
CM_ SG_ 935 DIR_a026_phaseBpeak "Rear drive inverter: a026 phase bpeak";
CM_ SG_ 935 DIR_a027_phaseCpeak "Rear drive inverter: a027 phase cpeak";
CM_ SG_ 935 DIR_a028_phaseArms "Rear drive inverter: a028 phase arms";
CM_ SG_ 935 DIR_a029_phaseBrms "Rear drive inverter: a029 phase brms";
CM_ SG_ 935 DIR_a030_phaseCrms "Rear drive inverter: a030 phase crms";
CM_ SG_ 935 DIR_a031_phaseAcurrentOffset "Rear drive inverter: a031 phase acurrent offset";
CM_ SG_ 935 DIR_a032_phaseBcurrentOffset "Rear drive inverter: a032 phase bcurrent offset";
CM_ SG_ 935 DIR_a033_phaseAcurrentSensor "Rear drive inverter: a033 phase acurrent sensor";
CM_ SG_ 935 DIR_a034_phaseBcurrentSensor "Rear drive inverter: a034 phase bcurrent sensor";
CM_ SG_ 935 DIR_a035_phaseCurrentBalance "Rear drive inverter: a035 phase current balance";
CM_ SG_ 935 DIR_a036_busOV "Rear drive inverter: a036 bus OV";
CM_ SG_ 935 DIR_a037_busUV "Rear drive inverter: a037 bus UV";
CM_ SG_ 935 DIR_a038_busVsensor "Rear drive inverter: a038 bus vsensor";
CM_ SG_ 935 DIR_a039_exceptionUndefinedInstr "Rear drive inverter: a039 exception undefined instruction";
CM_ SG_ 935 DIR_a040_difMIA "Rear drive inverter: a040 dif MIA";
CM_ SG_ 935 DIR_a041_sdcMIA "Rear drive inverter: a041 sdc MIA";
CM_ SG_ 935 DIR_a042_inletSensor "Rear drive inverter: a042 inlet sensor";
CM_ SG_ 935 DIR_a043_outletOT "Rear drive inverter: a043 outlet OT";
CM_ SG_ 935 DIR_a044_outletUT "Rear drive inverter: a044 outlet UT";
CM_ SG_ 935 DIR_a045_outletSensor "Rear drive inverter: a045 outlet sensor";
CM_ SG_ 935 DIR_a046_statorOT "Rear drive inverter: a046 stator OT";
CM_ SG_ 935 DIR_a047_statorSensor1 "Rear drive inverter: a047 stator sensor1";
CM_ SG_ 935 DIR_a048_statorSensor2 "Rear drive inverter: a048 stator sensor2";
CM_ SG_ 935 DIR_a049_statorSensorDiff "Rear drive inverter: a049 stator sensor diff";
CM_ SG_ 935 DIR_a050_noStatorSensor "Rear drive inverter: a050 no stator sensor";
CM_ SG_ 935 DIR_a052_dirMIA "Rear drive inverter: a052 dir MIA";
CM_ SG_ 935 DIR_a053_unexpectedLatchState "Rear drive inverter: a053 unexpected latch state";
CM_ SG_ 935 DIR_a054_driveInverterOT "Rear drive inverter: a054 drive inverter OT";
CM_ SG_ 935 DIR_a055_trqCrossCheck "Rear drive inverter: a055 trq cross check";
CM_ SG_ 935 DIR_a056_ambientOT "Rear drive inverter: a056 ambient OT";
CM_ SG_ 935 DIR_a057_ambientUT "Rear drive inverter: a057 ambient UT";
CM_ SG_ 935 DIR_a058_ambientSensor "Rear drive inverter: a058 ambient sensor";
CM_ SG_ 935 DIR_a059_heatsinkOT "Rear drive inverter: a059 heatsink OT";
CM_ SG_ 935 DIR_a060_heatsinkUT "Rear drive inverter: a060 heatsink UT";
CM_ SG_ 935 DIR_a061_heatsinkSensor "Rear drive inverter: a061 heatsink sensor";
CM_ SG_ 935 DIR_a062_systemLimpMode "Rear drive inverter: a062 system limp mode";
CM_ SG_ 935 DIR_a063_bbMIA "Rear drive inverter: a063 bb MIA";
CM_ SG_ 935 DIR_a064_torqueIntervention "Rear drive inverter: a064 torque intervention";
CM_ SG_ 935 DIR_a065_canHardwareBusB "Rear drive inverter: a065 can hardware bus b";
CM_ SG_ 935 DIR_a066_canDataBusB "Rear drive inverter: a066 can data bus b";
CM_ SG_ 935 DIR_a067_canOverrunBusB "Rear drive inverter: a067 can overrun bus b";
CM_ SG_ 935 DIR_a069_rotorTempLimit "Rear drive inverter: a069 rotor temp limit";
CM_ SG_ 935 DIR_a070_udsTransactionInitiated "Rear drive inverter: a070 uds transaction initiated";
CM_ SG_ 935 DIR_a071_busDisconnected "Rear drive inverter: a071 bus disconnected";
CM_ SG_ 935 DIR_a072_gateDriveFaultCounter "Rear drive inverter: a072 gate drive fault counter";
CM_ SG_ 935 DIR_a073_motorSpeed "Rear drive inverter: a073 motor speed";
CM_ SG_ 935 DIR_a074_motorEncoder "Rear drive inverter: a074 motor encoder";
CM_ SG_ 935 DIR_a075_motorSpeedMismatch "Rear drive inverter: a075 motor speed mismatch";
CM_ SG_ 935 DIR_a076_lvSupplyOV "Rear drive inverter: a076 lv supply OV";
CM_ SG_ 935 DIR_a077_lvSupplyUV "Rear drive inverter: a077 lv supply UV";
CM_ SG_ 935 DIR_a078_adcRefLow "Rear drive inverter: a078 adc ref low";
CM_ SG_ 935 DIR_a079_adcRefHigh "Rear drive inverter: a079 adc ref high";
CM_ SG_ 935 DIR_a084_eccTestData0 "Rear drive inverter: a084 ecc test data0";
CM_ SG_ 935 DIR_d085_driveInverterBoardFailu "Rear drive inverter: d085 drive inverter board failure";
CM_ SG_ 935 DIR_a086_activeDischargeOn "Rear drive inverter: a086 active discharge on";
CM_ SG_ 935 DIR_a087_gtwMIA "Rear drive inverter: a087 gtw MIA";
CM_ SG_ 935 DIR_a088_uiMIA "Rear drive inverter: a088 ui MIA";
CM_ SG_ 935 DIR_d089_invalidTorqueCommand "Rear drive inverter: d089 invalid torque command";
CM_ SG_ 935 DIR_a090_pmMIA "Rear drive inverter: a090 pm MIA";
CM_ SG_ 935 DIR_a091_espMIA "Rear drive inverter: a091 esp MIA";
CM_ SG_ 935 DIR_a092_bmsMIA "Rear drive inverter: a092 bms MIA";
CM_ SG_ 935 DIR_a093_canHardwareBusA "Rear drive inverter: a093 can hardware bus a";
CM_ SG_ 935 DIR_a094_canDataBusA "Rear drive inverter: a094 can data bus a";
CM_ SG_ 935 DIR_a095_canOverrunBusA "Rear drive inverter: a095 can overrun bus a";
CM_ SG_ 935 DIR_a096_memoryError "Rear drive inverter: a096 memory error";
CM_ SG_ 935 DIR_a097_eepromError "Rear drive inverter: a097 eeprom error";
CM_ SG_ 935 DIR_a098_intTimeTooLong "Rear drive inverter: a098 int time too long";
CM_ SG_ 935 DIR_a099_threadOverrun "Rear drive inverter: a099 thread overrun";
CM_ SG_ 935 DIR_a100_assertion "Rear drive inverter: a100 assertion";
CM_ SG_ 935 DIR_a101_eccTestData1 "Rear drive inverter: a101 ecc test data1";
CM_ SG_ 935 DIR_a102_exceptionPrefetchAbort "Rear drive inverter: a102 exception prefetch abort";
CM_ SG_ 935 DIR_a103_lowFlow "Rear drive inverter: a103 low flow";
CM_ SG_ 935 DIR_d104_resetUnintended "Rear drive inverter: d104 reset unintended";
CM_ SG_ 935 DIR_d105_busVoltageSensorIssue "Rear drive inverter: d105 bus voltage sensor issue";
CM_ SG_ 935 DIR_a106_idleTaskStarving "Rear drive inverter: a106 idle task starving";
CM_ SG_ 935 DIR_a107_fpgaError "Rear drive inverter: a107 fpga error";
CM_ SG_ 935 DIR_a108_stateTrans "Rear drive inverter: a108 state trans";
CM_ SG_ 935 DIR_a109_ahbWriteError "Rear drive inverter: a109 ahb write error";
CM_ SG_ 935 DIR_a110_brakeMIA "Rear drive inverter: a110 brake MIA";
CM_ SG_ 935 DIR_a111_badPhaseSensorCalib "Rear drive inverter: a111 bad phase sensor calib";
CM_ SG_ 935 DIR_a112_noPhaseCurrent "Rear drive inverter: a112 no phase current";
CM_ SG_ 935 DIR_a113_noFuncHeatsinkSensor "Rear drive inverter: a113 no func heatsink sensor";
CM_ SG_ 935 DIR_a114_exceptionDataAbort "Rear drive inverter: a114 exception data abort";
CM_ SG_ 935 DIR_a115_exceptionDataAbort2 "Rear drive inverter: a115 exception data abort2";
CM_ SG_ 935 DIR_a116_highSpeedWearCounter "Rear drive inverter: a116 high speed wear counter";
CM_ SG_ 935 DIR_a117_diMIA "Rear drive inverter: a117 di MIA";
CM_ SG_ 935 DIR_d118_oilPumpCommsLost "Rear drive inverter: d118 oil pump comms lost";
CM_ SG_ 935 DIR_a119_hvpMIA "Rear drive inverter: a119 hvp MIA";
CM_ SG_ 935 DIR_a120_hvlinkMIA "Rear drive inverter: a120 hvlink MIA";
CM_ SG_ 935 DIR_a121_motorControlRegulation "Rear drive inverter: a121 motor control regulation";
CM_ SG_ 935 DIR_a122_highStackUsage "Rear drive inverter: a122 high stack usage";
CM_ SG_ 935 DIR_a123_lossMotorControl "Rear drive inverter: a123 loss motor control";
CM_ SG_ 935 DIR_d124_oilPumpServiceRequired "Rear drive inverter: d124 oil pump service required";
CM_ SG_ 935 DIR_d125_currentSensorIssue "Rear drive inverter: d125 current sensor issue";
CM_ SG_ 935 DIR_a126_limpMode "Rear drive inverter: a126 limp mode";
CM_ SG_ 935 DIR_a127_gracefulPowerOff "Rear drive inverter: a127 graceful power off";
CM_ SG_ 935 DIR_a128_fpgaVersionMismatch "Rear drive inverter: a128 fpga version mismatch";
CM_ SG_ 935 DIR_d129_oilPumpIssue "Rear drive inverter: d129 oil pump issue";
CM_ SG_ 935 DIR_d130_positionSensorIssue "Rear drive inverter: d130 position sensor issue";
CM_ SG_ 935 DIR_d131_currentSensorOffset "Rear drive inverter: d131 current sensor offset";
CM_ SG_ 935 DIR_d132_busUVIssue "Rear drive inverter: d132 bus UV issue";
CM_ SG_ 935 DIR_a133_capacitorOT "Rear drive inverter: a133 capacitor OT";
CM_ SG_ 935 DIR_a134_wheelSpeedIrrational "Rear drive inverter: a134 wheel speed irrational";
CM_ SG_ 935 DIR_d135_rotatedStator "Rear drive inverter: d135 rotated stator";
CM_ SG_ 935 DIR_a136_spiError "Rear drive inverter: a136 spi error";
CM_ SG_ 935 DIR_d137_currentSensorOutOfRange "Rear drive inverter: d137 current sensor out of range";
CM_ SG_ 935 DIR_d138_inverterLVPowerSupplyLo "Rear drive inverter: d138 inverter LV power supply low";
CM_ SG_ 935 DIR_d141_coolingSystemIssue "Rear drive inverter: d141 cooling system issue";
CM_ SG_ 935 DIR_a142_highLashAngle "Rear drive inverter: a142 high lash angle";
CM_ SG_ 935 DIR_d143_wheelSpeedCorrelationIs "Rear drive inverter: d143 wheel speed correlation issue";
CM_ SG_ 935 DIR_a144_configMismatch "Rear drive inverter: a144 config mismatch";
CM_ SG_ 935 DIR_a147_highTorqueWearLimit "Rear drive inverter: a147 high torque wear limit";
CM_ SG_ 935 DIR_a148_burnInCycleEnded "Rear drive inverter: a148 burn in cycle ended";
CM_ SG_ 935 DIR_a149_oilPumpFailure "Rear drive inverter: a149 oil pump failure";
CM_ SG_ 935 DIR_a150_busVD "Rear drive inverter: a150 bus VD";
CM_ SG_ 935 DIR_a151_shockTorqueLimiter "Rear drive inverter: a151 shock torque limiter";
CM_ SG_ 935 DIR_a152_linError "Rear drive inverter: a152 lin error";
CM_ SG_ 935 DIR_a153_oilPumpDiagnostics "Rear drive inverter: a153 oil pump diagnostics";
CM_ SG_ 935 DIR_a154_resolver "Rear drive inverter: a154 resolver";
CM_ SG_ 935 DIR_a155_vcfrontMIA "Rear drive inverter: a155 vcfront MIA";
CM_ SG_ 935 DIR_a156_currentObserver "Rear drive inverter: a156 current observer";
CM_ SG_ 935 DIR_a157_rcmMIA "Rear drive inverter: a157 rcm MIA";
CM_ SG_ 935 DIR_a158_ibstMIA "Rear drive inverter: a158 ibst MIA";
CM_ SG_ 935 DIR_a160_busVoltageAnomaly "Rear drive inverter: a160 bus voltage anomaly";
CM_ SG_ 935 DIR_a161_epas3pMIA "Rear drive inverter: a161 epas3p MIA";
CM_ SG_ 935 DIR_a162_endOfLifetimeBurnIn "Rear drive inverter: a162 end of lifetime burn in";
CM_ SG_ 935 DIR_d163_recoverableOvercurrent "Rear drive inverter: d163 recoverable overcurrent";
CM_ SG_ 935 DIR_d164_firmwareConfigMismatch "Rear drive inverter: d164 firmware config mismatch";
CM_ SG_ 935 DIR_d165_statorOverTemperature "Rear drive inverter: d165 stator over temperature";
CM_ SG_ 935 DIR_d166_rotorOverTemperature "Rear drive inverter: d166 rotor over temperature";
CM_ SG_ 935 DIR_d167_tempSensorIssue "Rear drive inverter: d167 temp sensor issue";
CM_ SG_ 935 DIR_a171_rdcError "Rear drive inverter: a171 rdc error";
CM_ SG_ 935 DIR_a172_statorOilTempOT "Rear drive inverter: a172 stator oil temp OT";
CM_ SG_ 935 DIR_a173_ascFdbkDiagnostic "Rear drive inverter: a173 asc fdbk diagnostic";
CM_ SG_ 935 DIR_a174_unitMayNotRestart "Rear drive inverter: a174 unit may not restart";
CM_ SG_ 935 DIR_d175_oilPumpBCommsLost "Rear drive inverter: d175 oil pump b comms lost";
CM_ SG_ 935 DIR_a176_safetyICFault "Rear drive inverter: a176 safety IC fault";
CM_ SG_ 935 DIR_a177_fluxReferenceCorrected "Rear drive inverter: a177 flux reference corrected";
CM_ SG_ 935 DIR_a178_spindownLearningBrakeAl "Rear drive inverter: a178 spindown learning brake allowed";
CM_ SG_ 935 DIR_d179_oilPumpBIssue "Rear drive inverter: d179 oil pump b issue";
CM_ SG_ 935 DIR_a194_resolverGainAnomaly "Rear drive inverter: a194 resolver gain anomaly";
CM_ SG_ 935 DIR_a202_excessHeatUnavailable "Rear drive inverter: a202 excess heat unavailable";
CM_ SG_ 935 DIR_a225_tmpEstPlausibility "Rear drive inverter: a225 tmp est plausibility";
CM_ SG_ 935 DIR_a229_busVsensorOverCAN "Rear drive inverter: a229 bus vsensor over CAN";
CM_ SG_ 935 DIR_a233_diMsgMissed "Rear drive inverter: a233 di msg missed";
CM_ SG_ 935 DIR_a234_pcsMIA "Rear drive inverter: a234 pcs MIA";
CM_ SG_ 935 DIR_a236_tasMIA "Rear drive inverter: a236 tas MIA";
CM_ SG_ 935 DIR_a239_rotorDemagnetizationDet "Rear drive inverter: a239 rotor demagnetization detected";
CM_ SG_ 935 DIR_a240_clearFusesRoutine "Rear drive inverter: a240 clear fuses routine";
CM_ SG_ 935 DIR_a241_systemThermallyLimited "Rear drive inverter: a241 system thermally limited";
CM_ SG_ 935 DIR_a242_spinDownLearning "Rear drive inverter: a242 spin down learning";
CM_ SG_ 935 DIR_a243_ecuLogAvailable "Rear drive inverter: a243 ecu log available";
CM_ SG_ 935 DIR_a244_mechSafeStateApplied "Rear drive inverter: a244 mech safe state applied";
CM_ SG_ 935 DIR_a245_mechSafeStatePreWarn "Rear drive inverter: a245 mech safe state pre warn";
CM_ SG_ 935 DIR_a246_recoveryAtSpeedError "Rear drive inverter: a246 recovery at speed error";
CM_ SG_ 935 DIR_a247_rotorOffsetError "Rear drive inverter: a247 rotor offset error";
CM_ SG_ 935 DIR_a248_vehicleSpeedLimited "Rear drive inverter: a248 vehicle speed limited";
CM_ SG_ 935 DIR_a249_highStatorTempFromResis "Rear drive inverter: a249 high stator temp from resist";
CM_ SG_ 935 DIR_a250_preregulatorRail "Rear drive inverter: a250 preregulator rail";
CM_ SG_ 935 DIR_a251_oilPumpService "Rear drive inverter: a251 oil pump service";
CM_ SG_ 935 DIR_a252_currentCoreFallback "Rear drive inverter: a252 current core fallback";
CM_ SG_ 935 DIR_a253_lvBoostedRail "Rear drive inverter: a253 lv boosted rail";
CM_ SG_ 935 DIR_a254_activeDischargeRail "Rear drive inverter: a254 active discharge rail";
CM_ SG_ 935 DIR_a255_currentGainFallback "Rear drive inverter: a255 current gain fallback";
CM_ BO_ 2005 "Rear drive inverter message: debug";
CM_ SG_ 2005 DIR_debugSelector "Rear drive inverter: debug selector";
CM_ SG_ 2005 DIR_phaseOutBusbarTemp "Rear drive inverter: phase out busbar temp; raw 0 = signal not available (SNA)";
CM_ SG_ 2005 DIR_phaseOutBusbarWeldTemp "Rear drive inverter: phase out busbar weld temp; raw 0 = signal not available (SNA)";
CM_ SG_ 2005 DIR_phaseOutLugTemp "Rear drive inverter: phase out lug temp; raw 0 = signal not available (SNA)";
CM_ SG_ 2005 DIR_dcLinkCapTemp "Rear drive inverter: dc link cap temp; raw 0 = signal not available (SNA)";
CM_ SG_ 2005 DIR_hvDcCableTemp "Rear drive inverter: hv dc cable temp; raw 0 = signal not available (SNA)";
CM_ SG_ 2005 DIR_negDcBusbarTemp "Rear drive inverter: neg dc busbar temp; raw 0 = signal not available (SNA)";
CM_ SG_ 2005 DIR_posDcBusbarTemp "Rear drive inverter: pos dc busbar temp; raw 0 = signal not available (SNA)";
CM_ SG_ 2005 DIR_statorEndWindingTemp "Rear drive inverter: stator end winding temp; raw 0 = signal not available (SNA)";
CM_ SG_ 2005 DIR_rotorMaxMagnetTemp "Reports the maximum temperature of the rotor magnet; raw 0 = signal not available (SNA)";
CM_ SG_ 2005 DIR_lightSenseV "Rear drive inverter: light sense v";
CM_ SG_ 2005 DIR_pyroSenseV "Rear drive inverter: pyro sense v";
CM_ SG_ 2005 DIR_statorSlotWindingTemp "Rear drive inverter: stator slot winding temp; raw 0 = signal not available (SNA)";
CM_ SG_ 2005 DIR_intervalMaxHvBusV "Rear drive inverter: interval max hv bus v";
CM_ BO_ 633 "Rear drive inverter message: hv status";
CM_ SG_ 633 DIR_hvStatusChecksum "Rear drive inverter: hv status checksum";
CM_ SG_ 633 DIR_hvStatusCounter "Rear drive inverter: hv status counter";
CM_ SG_ 633 DIR_hvilCurrent "HVIL Current";
CM_ SG_ 633 DIR_hvilCmVoltage "HVIL Common Mode Voltage";
CM_ SG_ 633 DIR_hvilStatus "Aggregated hardware and measured HVIL unit status; raw 3 = signal not available (SNA)";
CM_ SG_ 633 DIR_hvilSupplyState "Rear drive inverter: hvil supply state";
CM_ SG_ 633 DIR_activeDischargeCtrl "Rear drive inverter: active discharge ctrl";
CM_ SG_ 633 DIR_activeDischargeStatus "Active discharge status from HVIL_FAULT signal.";
CM_ SG_ 633 DIR_vBat "Reports the battery voltage measured by the Drive Inverter's local Analog to Digital Converter (ADC).";
CM_ SG_ 633 DIR_vBatQF "Rear drive inverter: v bat QF";
CM_ SG_ 633 DIR_powerStageSafeState "Rear drive inverter: power stage safe state";
CM_ SG_ 633 DIR_fluxState "Rear drive inverter: flux state";
CM_ SG_ 633 DIR_vBusDiag "Rear drive inverter: v bus diag";
CM_ SG_ 633 DIR_gateDriveState "Rear drive inverter: gate drive state";
CM_ SG_ 633 DIR_gateDriveSupplyState "Rear drive inverter: gate drive supply state";
CM_ BO_ 821 "Rear drive inverter message: info";
CM_ SG_ 821 DIR_infoIndex "Rear drive inverter: info index";
CM_ SG_ 821 DIR_buildType "Rear drive inverter: build type";
CM_ SG_ 821 DIR_buildConfigurationId "Rear drive inverter: build configuration id";
CM_ SG_ 821 DIR_hardwareId "Rear drive inverter: hardware id";
CM_ SG_ 821 DIR_componentId "Rear drive inverter: component id";
CM_ SG_ 821 DIR_pcbaId "Rear drive inverter: pcba id";
CM_ SG_ 821 DIR_assemblyId "Rear drive inverter: assembly id";
CM_ SG_ 821 DIR_usageId "Rear drive inverter: usage id";
CM_ SG_ 821 DIR_subUsageId "Rear drive inverter: sub usage id";
CM_ SG_ 821 DIR_motorType "Rear drive inverter: motor type; raw 0 = signal not available (SNA)";
CM_ SG_ 821 DIR_siliconType "Rear drive inverter: silicon type";
CM_ SG_ 821 DIR_mechSafeStateType "Rear drive inverter: mech safe state type; raw 0 = signal not available (SNA)";
CM_ SG_ 821 DIR_applicationCrc "Rear drive inverter: application crc";
CM_ SG_ 821 DIR_oilPumpBuildType "Rear drive inverter: oil pump build type";
CM_ SG_ 821 DIR_oilPumpAppCrc "Rear drive inverter: oil pump app crc";
CM_ SG_ 821 DIR_FPGA_version "Rear drive inverter: FPGA version; raw 255 = signal not available (SNA)";
CM_ SG_ 821 DIR_appGitHash "Rear drive inverter: app git hash";
CM_ SG_ 821 DIR_bootGitHash "Rear drive inverter: boot git hash";
CM_ SG_ 821 DIR_infoBootLdUdsProtocolVersion "Rear drive inverter: info boot ld uds protocol version";
CM_ SG_ 821 DIR_bootloaderCrc "Rear drive inverter: bootloader crc";
CM_ SG_ 821 DIR_oilPumpPcbaId "Rear drive inverter: oil pump pcba id";
CM_ SG_ 821 DIR_oilPumpAssemblyId "Rear drive inverter: oil pump assembly id";
CM_ SG_ 821 DIR_oilPumpUsageId "Rear drive inverter: oil pump usage id";
CM_ SG_ 821 DIR_refRotorFlux "Rear drive inverter: ref rotor flux";
CM_ SG_ 821 DIR_refRotorOffset "Rear drive inverter: ref rotor offset; raw 2048 = signal not available (SNA)";
CM_ SG_ 821 DIR_speedWearTotal "Rear drive inverter: speed wear total; raw 255 = signal not available (SNA)";
CM_ SG_ 821 DIR_torqueWearTotal "Rear drive inverter: torque wear total; raw 255 = signal not available (SNA)";
CM_ BO_ 2037 "Rear drive inverter message: motor status";
CM_ SG_ 2037 DIR_motorCurrent "Drive Inverer measured motor RMS phase current.";
CM_ SG_ 2037 DIR_switchingFrequency "Rear drive inverter: switching frequency";
CM_ SG_ 2037 DIR_targetFluxMode "Rear drive inverter: target flux mode";
CM_ SG_ 2037 DIR_switchShortTestRetryCount "Rear drive inverter: switch short test retry count";
CM_ SG_ 2037 DIR_keepAliveRequest "Used to detect that the Drive Inverter (DI) expects 12V and High Voltage (HV) to be kept up in order to protect hardware.";
CM_ SG_ 2037 DIR_motorStatusCounter "Rear drive inverter: motor status counter";
CM_ SG_ 2037 DIR_motorStatusChecksum "Rear drive inverter: motor status checksum";
CM_ BO_ 917 "Rear drive inverter message: oil pump";
CM_ SG_ 917 DIR_oilPumpState "Reports the state of the oil pump; raw 7 = signal not available (SNA)";
CM_ SG_ 917 DIR_oilPumpFluidTQF "Rear drive inverter: oil pump fluid TQF";
CM_ SG_ 917 DIR_oilPumpLeadAngle "Rear drive inverter: oil pump lead angle";
CM_ SG_ 917 DIR_oilPumpFlowTarget "Detects oil pump flow target; raw 255 = signal not available (SNA)";
CM_ SG_ 917 DIR_oilPumpFlowActual "Detects oil pump flow; raw 255 = signal not available (SNA)";
CM_ SG_ 917 DIR_oilPumpFluidT "Detects oil pump fluid tester; raw 255 = signal not available (SNA)";
CM_ SG_ 917 DIR_oilPumpPhaseCurrent "Rear drive inverter: oil pump phase current; raw 255 = signal not available (SNA)";
CM_ SG_ 917 DIR_oilPumpPressureEstimate "Oil pump pressure estimate; raw 255 = signal not available (SNA)";
CM_ SG_ 917 DIR_oilPumpPressureExpected "Oil pump pressure expected; raw 255 = signal not available (SNA)";
CM_ SG_ 917 DIR_oilPumpPressureResidual "Oil pressure error outside of allowed tolerance; raw 255 = signal not available (SNA)";
CM_ BO_ 614 "Rear drive inverter message: power";
CM_ SG_ 614 DIR_elecPower "Rear drive inverter: elec power; raw 1024 = signal not available (SNA)";
CM_ SG_ 614 DIR_heatPowerOptimal "Rear drive inverter: heat power optimal";
CM_ SG_ 614 DIR_heatPowerMax "Drive Inverter maximum heat power capability";
CM_ SG_ 614 DIR_heatPowerActual "Drive Inverter heat power";
CM_ SG_ 614 DIR_excessHeatCommand "Drive Inverter excess heat command";
CM_ SG_ 614 DIR_drivePowerMax "Rear drive inverter: drive power max; raw 511 = signal not available (SNA)";
CM_ BO_ 598 "Rear drive inverter message: status";
CM_ SG_ 598 DIR_statusChecksum "Rear drive inverter: status checksum";
CM_ SG_ 598 DIR_statusCounter "Rear drive inverter: status counter";
CM_ SG_ 598 DIR_state "DI unit state machine state.";
CM_ SG_ 598 DIR_soptState "Detects the state of the the Switch Off Path Test (SOPT); raw 8 = signal not available (SNA)";
CM_ SG_ 598 DIR_sysLimpRequest "Rear drive inverter: sys limp request";
CM_ SG_ 598 DIR_softSysLimpRequest "Rear drive inverter: soft sys limp request";
CM_ SG_ 598 DIR_adState "Rear drive inverter: ad state";
CM_ SG_ 598 DIR_lvSupplyV "Rear drive inverter: lv supply v";
CM_ SG_ 598 DIR_driveModeState "Rear drive inverter: drive mode state";
CM_ SG_ 598 DIR_wasteState "Reports the Drive Inverter (DI) waste heat state.";
CM_ SG_ 598 DIR_haltRequest "Rear drive inverter: halt request";
CM_ SG_ 598 DIR_axleSpeedLimitRequest "Rear drive inverter: axle speed limit request";
CM_ SG_ 598 DIR_adDirection "Rear drive inverter: ad direction";
CM_ SG_ 598 DIR_spinDownLearningState "Rear drive inverter: spin down learning state";
CM_ SG_ 598 DIR_spinDownLearningMode "Rear drive inverter: spin down learning mode";
CM_ BO_ 789 "Rear drive inverter message: temperature";
CM_ SG_ 789 DIR_tempIndex "Rear drive inverter: temp index";
CM_ SG_ 789 DIR_inverterTQF "Detects the Drive Inverter (DI) outlet temperature qualifier.";
CM_ SG_ 789 DIR_pcbT "Rear drive inverter: pcb t; raw 0 = signal not available (SNA)";
CM_ SG_ 789 DIR_inverterT "Drive Inverter measured outlet temperature";
CM_ SG_ 789 DIR_statorT "Drive Inverter measured stator temperature; raw 0 = signal not available (SNA)";
CM_ SG_ 789 DIR_dcCapT "Rear drive inverter: dc cap t; raw 0 = signal not available (SNA)";
CM_ SG_ 789 DIR_heatsinkT "Drive Inverter measured heatsink temperature; raw 0 = signal not available (SNA)";
CM_ SG_ 789 DIR_inverterTpct "Rear drive inverter: inverter tpct";
CM_ SG_ 789 DIR_statorTpct "Rear drive inverter: stator tpct";
CM_ SG_ 789 DIR_fluidInTemp "Inlet fluid temperature; raw 0 = signal not available (SNA)";
CM_ SG_ 789 DIR_normalFetBurnIn "Rear drive inverter: normal fet burn in; raw 65535 = signal not available (SNA)";
CM_ SG_ 789 DIR_additionalFetBurnIn "Rear drive inverter: additional fet burn in; raw 65535 = signal not available (SNA)";
CM_ SG_ 789 DIR_currentWeibullMiles "Rear drive inverter: current weibull miles; raw 32767 = signal not available (SNA)";
CM_ SG_ 789 DIR_endOfServiceWeibullMiles "Rear drive inverter: end of service weibull miles; raw 32767 = signal not available (SNA)";
CM_ SG_ 789 DIR_burnInDamageRatio "Rear drive inverter: burn in damage ratio; raw 511 = signal not available (SNA)";
CM_ SG_ 789 DIR_inverterSensorEst "Rear drive inverter: inverter sensor est";
CM_ SG_ 789 DIR_inverterHS1Est "Rear drive inverter: inverter HS1 est";
CM_ SG_ 789 DIR_initialBurnInVehicleOdometer "Rear drive inverter: initial burn in vehicle odometer; raw 4294967295 = signal not available (SNA)";
CM_ SG_ 789 DIR_inverterHS2Est "Rear drive inverter: inverter HS2 est";
CM_ SG_ 789 DIR_inverterInletEst "Rear drive inverter: inverter inlet est";
CM_ SG_ 789 DIR_statorHousingTemp "Rear drive inverter: stator housing temp; raw 0 = signal not available (SNA)";
CM_ BO_ 1495 "Rear drive inverter message: thermal control";
CM_ SG_ 1495 DIR_passiveInletTempReq "Rear drive inverter: passive inlet temp req";
CM_ SG_ 1495 DIR_activeInletTempReq "Rear drive inverter: active inlet temp req";
CM_ SG_ 1495 DIR_coolantFlowReq "Coolant flow requested";
CM_ SG_ 1495 DIR_oilFlowReq "Rear drive inverter: oil flow req; raw 255 = signal not available (SNA)";
CM_ SG_ 1495 DIR_criticalFlowReq "Rear drive inverter: critical flow req";
CM_ SG_ 1495 DIR_burnInStatus "Rear drive inverter: burn in status";
CM_ BO_ 264 "Rear drive inverter message: torque";
CM_ SG_ 264 DIR_torqueChecksum "Rear drive inverter: torque checksum";
CM_ SG_ 264 DIR_torqueCounter "Rear drive inverter: torque counter";
CM_ SG_ 264 DIR_torqueCommand "Torque commanded to the drive unit, referred to the axle/wheel; raw 4096 = signal not available (SNA)";
CM_ SG_ 264 DIR_axleSpeedQF "Rear drive inverter: axle speed QF";
CM_ SG_ 264 DIR_torqueActual "Actual torque the drive unit is controlling to referred to the axle/wheel; raw 4096 = signal not available (SNA)";
CM_ SG_ 264 DIR_axleSpeed "Drive Inverter motor speed normalized at axle level; raw 32768 = signal not available (SNA)";
CM_ SG_ 264 DIR_axleTorqueQF "Rear drive inverter: axle torque QF";
CM_ SG_ 264 DIR_axlePowerCalcQF "Rear drive inverter: axle power calc QF";
CM_ SG_ 264 DIR_gear "Rear drive inverter: gear; raw 7 = signal not available (SNA)";
CM_ BO_ 1558 "Rear drive inverter message: uds response";
CM_ SG_ 1558 DIR_udsResponseData "Rear drive inverter: uds response data";
CM_ BO_ 1319 "Drive inverter message: alert log";
CM_ SG_ 1319 DI_alertID "Drive inverter: alert ID";
CM_ SG_ 1319 DI_alertState "Drive inverter: alert state";
CM_ SG_ 1319 DI_a004_unavailableReason "Drive inverter: a004 unavailable reason; raw 0 = signal not available (SNA)";
CM_ SG_ 1319 DI_a007_button "Drive inverter: a007 button";
CM_ SG_ 1319 DI_a007_buttonStuckTime "Drive inverter: a007 button stuck time";
CM_ SG_ 1319 DI_a010_sccReset "Drive inverter: a010 scc reset";
CM_ SG_ 1319 DI_a010_hibernate "Drive inverter: a010 hibernate";
CM_ SG_ 1319 DI_a010_hwBist "Drive inverter: a010 hw bist";
CM_ SG_ 1319 DI_a010_nmiWatchdog "Drive inverter: a010 nmi watchdog";
CM_ SG_ 1319 DI_a010_watchdog "Drive inverter: a010 watchdog";
CM_ SG_ 1319 DI_a010_clockFailNmi "Drive inverter: a010 clock fail nmi";
CM_ SG_ 1319 DI_a010_ramUncErrorNmi "Drive inverter: a010 ram unc error nmi";
CM_ SG_ 1319 DI_a010_flashUncErrorNmi "Drive inverter: a010 flash unc error nmi";
CM_ SG_ 1319 DI_a010_cpu1signMismatchNmi "Drive inverter: a010 cpu1sign mismatch nmi";
CM_ SG_ 1319 DI_a010_cpu2signMismatchNmi "Drive inverter: a010 cpu2sign mismatch nmi";
CM_ SG_ 1319 DI_a010_pieVectErrorNmi "Drive inverter: a010 pie vect error nmi";
CM_ SG_ 1319 DI_a010_sysDbgNmi "Drive inverter: a010 sys dbg nmi";
CM_ SG_ 1319 DI_a010_rlNmi "Drive inverter: a010 rl nmi";
CM_ SG_ 1319 DI_a010_ovfNmi "Drive inverter: a010 ovf nmi";
CM_ SG_ 1319 DI_a010_wdtFlags "Drive inverter: a010 wdt flags";
CM_ SG_ 1319 DI_a012_accel1SupplyV "Drive inverter: a012 accel1 supply v";
CM_ SG_ 1319 DI_a012_accel2SupplyV "Drive inverter: a012 accel2 supply v";
CM_ SG_ 1319 DI_a013_address "Drive inverter: a013 address";
CM_ SG_ 1319 DI_a013_errorType "Drive inverter: a013 error type";
CM_ SG_ 1319 DI_a015_reason "Drive inverter: a015 reason";
CM_ SG_ 1319 DI_a020_difHvilStatus "Drive inverter: a020 dif hvil status; raw 3 = signal not available (SNA)";
CM_ SG_ 1319 DI_a020_difStatusValid "Drive inverter: a020 dif status valid";
CM_ SG_ 1319 DI_a020_dirHvilStatus "Drive inverter: a020 dir hvil status; raw 3 = signal not available (SNA)";
CM_ SG_ 1319 DI_a020_dirStatusValid "Drive inverter: a020 dir status valid";
CM_ SG_ 1319 DI_a020_vehiclePowerState "Drive inverter: a020 vehicle power state";
CM_ SG_ 1319 DI_a020_hvilSystemStatus "Drive inverter: a020 hvil system status; raw 3 = signal not available (SNA)";
CM_ SG_ 1319 DI_a021_packVoltage "Drive inverter: a021 pack voltage";
CM_ SG_ 1319 DI_a021_maxBusVoltage "Drive inverter: a021 max bus voltage";
CM_ SG_ 1319 DI_a024_pedalPos "Drive inverter: a024 pedal pos";
CM_ SG_ 1319 DI_a024_brakePressed "Drive inverter: a024 brake pressed";
CM_ SG_ 1319 DI_a024_currentGear "Drive inverter: a024 current gear; raw 7 = signal not available (SNA)";
CM_ SG_ 1319 DI_a025_backfillState "Drive inverter: a025 backfill state";
CM_ SG_ 1319 DI_a025_bfillUnavailableReason "Drive inverter: a025 bfill unavailable reason";
CM_ SG_ 1319 DI_a036_numFaultedUnits "Drive inverter: a036 num faulted units";
CM_ SG_ 1319 DI_a036_numAvailableUnits "Drive inverter: a036 num available units";
CM_ SG_ 1319 DI_a040_torque "Drive inverter: a040 torque";
CM_ SG_ 1319 DI_a040_capability "Drive inverter: a040 capability";
CM_ SG_ 1319 DI_a040_power "Drive inverter: a040 power";
CM_ SG_ 1319 DI_a040_status "Drive inverter: a040 status";
CM_ SG_ 1319 DI_a040_capability2 "Drive inverter: a040 capability2";
CM_ SG_ 1319 DI_a040_hvStatus "Drive inverter: a040 hv status";
CM_ SG_ 1319 DI_a040_temperature "Drive inverter: a040 temperature";
CM_ SG_ 1319 DI_a042_state4 "Drive inverter: a042 state4";
CM_ SG_ 1319 DI_a043_state4 "Drive inverter: a043 state4";
CM_ SG_ 1319 DI_a051_dcCableCurrentEst "Drive inverter: a051 dc cable current est";
CM_ SG_ 1319 DI_a051_packCurrent "Drive inverter: a051 pack current";
CM_ SG_ 1319 DI_a052_torque "Drive inverter: a052 torque";
CM_ SG_ 1319 DI_a052_capability "Drive inverter: a052 capability";
CM_ SG_ 1319 DI_a052_power "Drive inverter: a052 power";
CM_ SG_ 1319 DI_a052_status "Drive inverter: a052 status";
CM_ SG_ 1319 DI_a052_capability2 "Drive inverter: a052 capability2";
CM_ SG_ 1319 DI_a052_hvStatus "Drive inverter: a052 hv status";
CM_ SG_ 1319 DI_a052_temperature "Drive inverter: a052 temperature";
CM_ SG_ 1319 DI_a062_limpReason "Drive inverter: a062 limp reason";
CM_ SG_ 1319 DI_a063_gpoReason "Drive inverter: a063 gpo reason";
CM_ SG_ 1319 DI_a064_hvState "Drive inverter: a064 hv state";
CM_ SG_ 1319 DI_a064_vehiclePowerState "Drive inverter: a064 vehicle power state";
CM_ SG_ 1319 DI_a064_vehicleSpeed "Drive inverter: a064 vehicle speed";
CM_ SG_ 1319 DI_a074_recoveredGear "Drive inverter: a074 recovered gear; raw 7 = signal not available (SNA)";
CM_ SG_ 1319 DI_a074_vehicleSpeed "Drive inverter: a074 vehicle speed";
CM_ SG_ 1319 DI_a074_attemptCount "Drive inverter: a074 attempt count";
CM_ SG_ 1319 DI_a074_unit0Gear "Drive inverter: a074 unit0 gear; raw 7 = signal not available (SNA)";
CM_ SG_ 1319 DI_a074_unit1Gear "Drive inverter: a074 unit1 gear; raw 7 = signal not available (SNA)";
CM_ SG_ 1319 DI_a074_unit2Gear "Drive inverter: a074 unit2 gear; raw 7 = signal not available (SNA)";
CM_ SG_ 1319 DI_a074_failureReason "Drive inverter: a074 failure reason";
CM_ SG_ 1319 DI_a074_epbSystemStatus "Drive inverter: a074 epb system status; raw 15 = signal not available (SNA)";
CM_ SG_ 1319 DI_a076_lvSupplyV "Drive inverter: a076 lv supply v";
CM_ SG_ 1319 DI_a077_lvSupplyV "Drive inverter: a077 lv supply v";
CM_ SG_ 1319 DI_a078_adcRefChan "Drive inverter: a078 adc ref chan";
CM_ SG_ 1319 DI_a078_adcRefLowAvg "Drive inverter: a078 adc ref low avg";
CM_ SG_ 1319 DI_a079_adcRefChan "Drive inverter: a079 adc ref chan";
CM_ SG_ 1319 DI_a079_adcRefHighAvg "Drive inverter: a079 adc ref high avg";
CM_ SG_ 1319 DI_a083_brakeSwitchNO "Drive inverter: a083 brake switch NO";
CM_ SG_ 1319 DI_a083_brakeSwitchNC "Drive inverter: a083 brake switch NC";
CM_ SG_ 1319 DI_a083_brakeSwitchIrrationalNO "Drive inverter: a083 brake switch irrational NO";
CM_ SG_ 1319 DI_a083_brakeSwitchIrrationalNC "Drive inverter: a083 brake switch irrational NC";
CM_ SG_ 1319 DI_a086_DPB_actuator3 "Drive inverter: a086 DPB actuator3";
CM_ SG_ 1319 DI_a086_DPB_redundantBrakingStat "Drive inverter: a086 DPB redundant braking status";
CM_ SG_ 1319 DI_a087_gtwCarConfig "Drive inverter: a087 gtw car config";
CM_ SG_ 1319 DI_a087_gtwTime "Drive inverter: a087 gtw time";
CM_ SG_ 1319 DI_a087_gtwUpdateStatus "Drive inverter: a087 gtw update status";
CM_ SG_ 1319 DI_a087_gearControl "Drive inverter: a087 gear control";
CM_ SG_ 1319 DI_a087_carState "Drive inverter: a087 car state";
CM_ SG_ 1319 DI_a089_SCCM_rightStalk "Drive inverter: a089 SCCM right stalk";
CM_ SG_ 1319 DI_a090_reason "Drive inverter: a090 reason";
CM_ SG_ 1319 DI_a090_systemState "Drive inverter: a090 system state";
CM_ SG_ 1319 DI_a090_state "Drive inverter: a090 state";
CM_ SG_ 1319 DI_a090_locState "Drive inverter: a090 loc state";
CM_ SG_ 1319 DI_a090_state2 "Drive inverter: a090 state2";
CM_ SG_ 1319 DI_a090_state4 "Drive inverter: a090 state4";
CM_ SG_ 1319 DI_a091_ESP_brakeTorque "Drive inverter: a091 ESP brake torque";
CM_ SG_ 1319 DI_a091_ESP_wheelSpeeds "Drive inverter: a091 ESP wheel speeds";
CM_ SG_ 1319 DI_a091_ESP_wheelRotation "Drive inverter: a091 ESP wheel rotation";
CM_ SG_ 1319 DI_a091_ESP_motorLimits "Drive inverter: a091 ESP motor limits";
CM_ SG_ 1319 DI_a091_ESP_offsets "Drive inverter: a091 ESP offsets";
CM_ SG_ 1319 DI_a091_ESP_status "Drive inverter: a091 ESP status";
CM_ SG_ 1319 DI_a091_ESP_party3 "Drive inverter: a091 ESP party3";
CM_ SG_ 1319 DI_a091_ESP_redundantBrakingStat "Drive inverter: a091 ESP redundant braking status";
CM_ SG_ 1319 DI_a092_bmsStatus "Drive inverter: a092 bms status";
CM_ SG_ 1319 DI_a092_bmsDriveLimits "Drive inverter: a092 bms drive limits";
CM_ SG_ 1319 DI_a092_bmsHvBusStatus "Drive inverter: a092 bms hv bus status";
CM_ SG_ 1319 DI_a092_bmsPowerAvailable "Drive inverter: a092 bms power available";
CM_ SG_ 1319 DI_a092_bmsBmbMinMax "Drive inverter: a092 bms bmb min max";
CM_ SG_ 1319 DI_a092_bmsSocStatus "Drive inverter: a092 bms soc status";
CM_ SG_ 1319 DI_a092_bmsThermalStatus "Drive inverter: a092 bms thermal status";
CM_ SG_ 1319 DI_a092_bmsCtrStatus "Drive inverter: a092 bms ctr status";
CM_ SG_ 1319 DI_a092_bmsVoltageRegGain "Drive inverter: a092 bms voltage reg gain";
CM_ SG_ 1319 DI_a092_bmsPackConfig "Drive inverter: a092 bms pack config";
CM_ SG_ 1319 DI_a092_bmsSystemStatus "Drive inverter: a092 bms system status";
CM_ SG_ 1319 DI_a096_const_fast "Drive inverter: a096 const fast";
CM_ SG_ 1319 DI_a096_text_fast "Drive inverter: a096 text fast";
CM_ SG_ 1319 DI_a096_text_flash "Drive inverter: a096 text flash";
CM_ SG_ 1319 DI_a096_mem_data "Drive inverter: a096 mem data";
CM_ SG_ 1319 DI_a096_mem_regs "Drive inverter: a096 mem regs";
CM_ SG_ 1319 DI_a096_boot_flash "Drive inverter: a096 boot flash";
CM_ SG_ 1319 DI_a096_word1 "Drive inverter: a096 word1";
CM_ SG_ 1319 DI_a096_word2 "Drive inverter: a096 word2";
CM_ SG_ 1319 DI_a097_errorType "Drive inverter: a097 error type";
CM_ SG_ 1319 DI_a097_lineNumber "Drive inverter: a097 line number";
CM_ SG_ 1319 DI_a097_argument "Drive inverter: a097 argument";
CM_ SG_ 1319 DI_a098_page0Counter "Drive inverter: a098 page0 counter";
CM_ SG_ 1319 DI_a098_page1Counter "Drive inverter: a098 page1 counter";
CM_ SG_ 1319 DI_a098_page2Counter "Drive inverter: a098 page2 counter";
CM_ SG_ 1319 DI_a098_pageID "Drive inverter: a098 page ID";
CM_ SG_ 1319 DI_a098_recordID "Drive inverter: a098 record ID";
CM_ SG_ 1319 DI_a098_errorCode "Drive inverter: a098 error code";
CM_ SG_ 1319 DI_a103_BB_status "Drive inverter: a103 BB status";
CM_ SG_ 1319 DI_a103_BB_brakeActuation "Drive inverter: a103 BB brake actuation";
CM_ SG_ 1319 DI_a104_proxIrrationalReason "Drive inverter: a104 prox irrational reason";
CM_ SG_ 1319 DI_a105_cpStatus "Drive inverter: a105 cp status";
CM_ SG_ 1319 DI_a110_EPBL_status "Drive inverter: a110 EPBL status";
CM_ SG_ 1319 DI_a110_EPBR_status "Drive inverter: a110 EPBR status";
CM_ SG_ 1319 DI_a110_EPBL_autonomyHealth "Drive inverter: a110 EPBL autonomy health";
CM_ SG_ 1319 DI_a110_EPBR_autonomyHealth "Drive inverter: a110 EPBR autonomy health";
CM_ SG_ 1319 DI_a120_blendingState "Drive inverter: a120 blending state";
CM_ SG_ 1319 DI_a120_blendingUnavailableReaso "Drive inverter: a120 blending unavailable reason";
CM_ SG_ 1319 DI_a124_undrivenWheelMPH "Drive inverter: a124 undriven wheel MPH";
CM_ SG_ 1319 DI_a124_cruiseFaultReason "Drive inverter: a124 cruise fault reason; raw 17 = signal not available (SNA)";
CM_ SG_ 1319 DI_a124_cruiseFaultStack "Drive inverter: a124 cruise fault stack; raw 0 = signal not available (SNA)";
CM_ SG_ 1319 DI_a125_maxDischargeCurrent "Drive inverter: a125 max discharge current";
CM_ SG_ 1319 DI_a125_maxChargeCurrent "Drive inverter: a125 max charge current";
CM_ SG_ 1319 DI_a125_minBusVoltage "Drive inverter: a125 min bus voltage";
CM_ SG_ 1319 DI_a130_aebFaultReason "Drive inverter: a130 aeb fault reason; raw 6 = signal not available (SNA)";
CM_ SG_ 1319 DI_a130_aebSmState "Drive inverter: a130 aeb sm state";
CM_ SG_ 1319 DI_a130_dasAebEvent "Drive inverter: a130 das aeb event; raw 3 = signal not available (SNA)";
CM_ SG_ 1319 DI_a130_aebBrakeTorqueCommand "Drive inverter: a130 aeb brake torque command";
CM_ SG_ 1319 DI_a131_totalTimeRemaining "Drive inverter: a131 total time remaining";
CM_ SG_ 1319 DI_a131_warnSpeedLimit "Drive inverter: a131 warn speed limit";
CM_ SG_ 1319 DI_a131_warnTimeRemaining "Drive inverter: a131 warn time remaining";
CM_ SG_ 1319 DI_a133_vhldSmState "Drive inverter: a133 vhld sm state";
CM_ SG_ 1319 DI_a133_reverseGear "Drive inverter: a133 reverse gear";
CM_ SG_ 1319 DI_a133_vhldGrade "Drive inverter: a133 vhld grade";
CM_ SG_ 1319 DI_a134_wheelSpeedDiffFrL "Drive inverter: a134 wheel speed diff fr l";
CM_ SG_ 1319 DI_a134_wheelSpeedDiffFrR "Drive inverter: a134 wheel speed diff fr r";
CM_ SG_ 1319 DI_a134_wheelSpeedDiffReL "Drive inverter: a134 wheel speed diff re l";
CM_ SG_ 1319 DI_a134_wheelSpeedDiffReR "Drive inverter: a134 wheel speed diff re r";
CM_ SG_ 1319 DI_a135_vhldFaultReason "Drive inverter: a135 vhld fault reason";
CM_ SG_ 1319 DI_a135_vhldSmState "Drive inverter: a135 vhld sm state";
CM_ SG_ 1319 DI_a135_vhldBrakeApply "Drive inverter: a135 vhld brake apply";
CM_ SG_ 1319 DI_a135_vhldBrakeTorqueCommand "Drive inverter: a135 vhld brake torque command";
CM_ SG_ 1319 DI_a135_vhldTotalBrakeTorque "Drive inverter: a135 vhld total brake torque";
CM_ SG_ 1319 DI_a135_vhldPropulsiveTorque "Drive inverter: a135 vhld propulsive torque";
CM_ SG_ 1319 DI_a135_vhldGrade "Drive inverter: a135 vhld grade";
CM_ SG_ 1319 DI_a140_PTC_feedbackStatus "Drive inverter: a140 PTC feedback status";
CM_ SG_ 1319 DI_a141_DAS_control "Drive inverter: a141 DAS control";
CM_ SG_ 1319 DI_a141_DAS_pmmControl "Drive inverter: a141 DAS pmm control";
CM_ SG_ 1319 DI_a141_DAS_status "Drive inverter: a141 DAS status";
CM_ SG_ 1319 DI_a141_DAS_status2 "Drive inverter: a141 DAS status2";
CM_ SG_ 1319 DI_a141_DAS_smartShift "Drive inverter: a141 DAS smart shift";
CM_ SG_ 1319 DI_a141_DAS_longControl "Drive inverter: a141 DAS long control";
CM_ SG_ 1319 DI_a141_DAS_longControlTuningPar "Drive inverter: a141 DAS long control tuning parameters";
CM_ SG_ 1319 DI_a141_DAS_autonomyControl "Drive inverter: a141 DAS autonomy control";
CM_ SG_ 1319 DI_a141_DAS_redundantBrakingCont "Drive inverter: a141 DAS redundant braking control";
CM_ SG_ 1319 DI_a143_mechPowerLimit "Drive inverter: a143 mech power limit";
CM_ SG_ 1319 DI_a143_systemTorqueLimit "Drive inverter: a143 system torque limit";
CM_ SG_ 1319 DI_a144_autopilot "Drive inverter: a144 autopilot";
CM_ SG_ 1319 DI_a144_chassisType "Drive inverter: a144 chassis type";
CM_ SG_ 1319 DI_a144_drivetrainType "Drive inverter: a144 drivetrain type";
CM_ SG_ 1319 DI_a144_packEnergy "Drive inverter: a144 pack energy";
CM_ SG_ 1319 DI_a144_packPerformanceDeviation "Drive inverter: a144 pack performance deviation";
CM_ SG_ 1319 DI_a144_performancePackage "Drive inverter: a144 performance package";
CM_ SG_ 1319 DI_a144_vdcType "Drive inverter: a144 vdc type";
CM_ SG_ 1319 DI_a144_brakeHWType "Drive inverter: a144 brake HW type";
CM_ SG_ 1319 DI_a144_inverterHardware "Drive inverter: a144 inverter hardware";
CM_ SG_ 1319 DI_a144_cabinPTCHeaterType "Drive inverter: a144 cabin PTC heater type";
CM_ SG_ 1319 DI_a144_frunkLatchType "Drive inverter: a144 frunk latch type";
CM_ SG_ 1319 DI_a144_platformMaxBusVoltage "Drive inverter: a144 platform max bus voltage";
CM_ SG_ 1319 DI_a144_oilPump1HwType "Drive inverter: a144 oil pump1 hw type";
CM_ SG_ 1319 DI_a144_oilPump2HwType "Drive inverter: a144 oil pump2 hw type";
CM_ SG_ 1319 DI_a144_heatsinkType "Drive inverter: a144 heatsink type";
CM_ SG_ 1319 DI_a144_softPerformanceLimit "Drive inverter: a144 soft performance limit";
CM_ SG_ 1319 DI_a144_brakeActuationType "Drive inverter: a144 brake actuation type";
CM_ SG_ 1319 DI_a144_dasHw "Drive inverter: a144 das hw";
CM_ SG_ 1319 DI_a144_powerLiftgateType "Drive inverter: a144 power liftgate type";
CM_ SG_ 1319 DI_a144_chassisSubType "Drive inverter: a144 chassis sub type";
CM_ SG_ 1319 DI_a144_autonomyFeatureType "Drive inverter: a144 autonomy feature type";
CM_ SG_ 1319 DI_a146_panicReason "Drive inverter: a146 panic reason";
CM_ SG_ 1319 DI_a155_sensors "Drive inverter: a155 sensors";
CM_ SG_ 1319 DI_a155_coolant "Drive inverter: a155 coolant";
CM_ SG_ 1319 DI_a155_LVPowerState "Drive inverter: a155 LV power state";
CM_ SG_ 1319 DI_a155_vehicleStatus "Drive inverter: a155 vehicle status";
CM_ SG_ 1319 DI_a155_status "Drive inverter: a155 status";
CM_ SG_ 1319 DI_a155_leftDoorStatus "Drive inverter: a155 left door status";
CM_ SG_ 1319 DI_a155_rightDoorStatus "Drive inverter: a155 right door status";
CM_ SG_ 1319 DI_a155_vcleftSwitchStatus "Drive inverter: a155 vcleft switch status";
CM_ SG_ 1319 DI_a155_restraintStatus "Drive inverter: a155 restraint status";
CM_ SG_ 1319 DI_a155_systemStatus "Drive inverter: a155 system status";
CM_ SG_ 1319 DI_a155_prndStatus "Drive inverter: a155 prnd status";
CM_ SG_ 1319 DI_a155_liftgateStatus "Drive inverter: a155 liftgate status";
CM_ SG_ 1319 DI_a157_RCM_inertial1 "Drive inverter: a157 RCM inertial1";
CM_ SG_ 1319 DI_a157_RCM_inertial2 "Drive inverter: a157 RCM inertial2";
CM_ SG_ 1319 DI_a158_IBST_party1 "Drive inverter: a158 IBST party1";
CM_ SG_ 1319 DI_a158_BUS1_IBST_status "Drive inverter: a158 BUS1 IBST status";
CM_ SG_ 1319 DI_a158_BUS2_IBST_status "Drive inverter: a158 BUS2 IBST status";
CM_ SG_ 1319 DI_a158_IBST_redundantBrakingSta "Drive inverter: a158 IBST redundant braking status";
CM_ SG_ 1319 DI_a160_kTire "Drive inverter: a160 k tire";
CM_ SG_ 1319 DI_a160_tireFitment "Drive inverter: a160 tire fitment; raw 3 = signal not available (SNA)";
CM_ SG_ 1319 DI_a160_wearFactorFrL "Drive inverter: a160 wear factor fr l";
CM_ SG_ 1319 DI_a160_wearFactorFrR "Drive inverter: a160 wear factor fr r";
CM_ SG_ 1319 DI_a160_wearFactorReL "Drive inverter: a160 wear factor re l";
CM_ SG_ 1319 DI_a160_distanceSinceLastTireCon "Drive inverter: a160 distance since last tire config; raw 4095 = signal not available (SNA)";
CM_ SG_ 1319 DI_a161_EPAS3P_sysStatus "Drive inverter: a161 EPAS3 p sys status";
CM_ SG_ 1319 DI_a161_EPAS3P_angleCalib "Drive inverter: a161 EPAS3 p angle calib";
CM_ SG_ 1319 DI_a162_shiftDeniedReason "Drive inverter: a162 shift denied reason";
CM_ SG_ 1319 DI_a162_motorSpeed "Drive inverter: a162 motor speed";
CM_ SG_ 1319 DI_a162_essContClosed "Drive inverter: a162 ess cont closed";
CM_ SG_ 1319 DI_a162_autonomyBehavior "Drive inverter: a162 autonomy behavior";
CM_ SG_ 1319 DI_a162_pedalPos "Drive inverter: a162 pedal pos";
CM_ SG_ 1319 DI_a162_currentGear "Drive inverter: a162 current gear; raw 7 = signal not available (SNA)";
CM_ SG_ 1319 DI_a162_requestedGear "Drive inverter: a162 requested gear; raw 7 = signal not available (SNA)";
CM_ SG_ 1319 DI_a162_requestSource "Drive inverter: a162 request source";
CM_ SG_ 1319 DI_a162_timeSinceCruiseCancel "Drive inverter: a162 time since cruise cancel";
CM_ SG_ 1319 DI_a162_chargeCableConnected "Drive inverter: a162 charge cable connected";
CM_ SG_ 1319 DI_a162_frunkOpen "Drive inverter: a162 frunk open";
CM_ SG_ 1319 DI_a162_sysStateExitCondition "Drive inverter: a162 sys state exit condition";
CM_ SG_ 1319 DI_a163_motorSpeed "Drive inverter: a163 motor speed";
CM_ SG_ 1319 DI_a163_currentGear "Drive inverter: a163 current gear; raw 7 = signal not available (SNA)";
CM_ SG_ 1319 DI_a163_requestedGear "Drive inverter: a163 requested gear; raw 7 = signal not available (SNA)";
CM_ SG_ 1319 DI_a163_requestSource "Drive inverter: a163 request source";
CM_ SG_ 1319 DI_a164_motorSpeed "Drive inverter: a164 motor speed";
CM_ SG_ 1319 DI_a164_pedalPos "Drive inverter: a164 pedal pos";
CM_ SG_ 1319 DI_a164_torqueDriver "Drive inverter: a164 torque driver";
CM_ SG_ 1319 DI_a170_tireSeasonSelected "Drive inverter: a170 tire season selected";
CM_ SG_ 1319 DI_a170_kTire "Drive inverter: a170 k tire";
CM_ SG_ 1319 DI_a170_tireFitment "Drive inverter: a170 tire fitment; raw 3 = signal not available (SNA)";
CM_ SG_ 1319 DI_a170_wearFactorFrL "Drive inverter: a170 wear factor fr l";
CM_ SG_ 1319 DI_a170_wearFactorFrR "Drive inverter: a170 wear factor fr r";
CM_ SG_ 1319 DI_a170_wearFactorReL "Drive inverter: a170 wear factor re l";
CM_ SG_ 1319 DI_a170_odometer "Drive inverter: a170 odometer; raw 4095 = signal not available (SNA)";
CM_ SG_ 1319 DI_a170_distanceSinceLastTireCon "Drive inverter: a170 distance since last tire config; raw 63 = signal not available (SNA)";
CM_ SG_ 1319 DI_a170_treadDepthAlertSet "Drive inverter: a170 tread depth alert set";
CM_ SG_ 1319 DI_a172_motorSpeed "Drive inverter: a172 motor speed";
CM_ SG_ 1319 DI_a172_pedalPos "Drive inverter: a172 pedal pos";
CM_ SG_ 1319 DI_a172_currentGear "Drive inverter: a172 current gear; raw 7 = signal not available (SNA)";
CM_ SG_ 1319 DI_a172_timeSinceCruiseCancel "Drive inverter: a172 time since cruise cancel";
CM_ SG_ 1319 DI_a173_brakeApply "Drive inverter: a173 brake apply";
CM_ SG_ 1319 DI_a173_pedalPos "Drive inverter: a173 pedal pos";
CM_ SG_ 1319 DI_a175_crsNotAvailableReason "Drive inverter: a175 crs not available reason; raw 20 = signal not available (SNA)";
CM_ SG_ 1319 DI_a175_crsNotAvailableStack "Drive inverter: a175 crs not available stack; raw 0 = signal not available (SNA)";
CM_ SG_ 1319 DI_a177_newFitment "Drive inverter: a177 new fitment; raw 3 = signal not available (SNA)";
CM_ SG_ 1319 DI_a178_offsetValue "Drive inverter: a178 offset value";
CM_ SG_ 1319 DI_a180_crsNotAvailableReason "Drive inverter: a180 crs not available reason; raw 20 = signal not available (SNA)";
CM_ SG_ 1319 DI_a184_apcCancelReason "Drive inverter: a184 apc cancel reason";
CM_ SG_ 1319 DI_a184_apcUnavailableReason "Drive inverter: a184 apc unavailable reason";
CM_ SG_ 1319 DI_a184_autoparkInternalState "Drive inverter: a184 autopark internal state";
CM_ SG_ 1319 DI_a185_summonActive "Drive inverter: a185 summon active";
CM_ SG_ 1319 DI_a185_apcCancelReason "Drive inverter: a185 apc cancel reason";
CM_ SG_ 1319 DI_a185_apcUnavailableReason "Drive inverter: a185 apc unavailable reason";
CM_ SG_ 1319 DI_a185_crsNotAvailableReason "Drive inverter: a185 crs not available reason; raw 20 = signal not available (SNA)";
CM_ SG_ 1319 DI_a185_crsFaultReason "Drive inverter: a185 crs fault reason; raw 17 = signal not available (SNA)";
CM_ SG_ 1319 DI_a185_autoparkInternalState "Drive inverter: a185 autopark internal state";
CM_ SG_ 1319 DI_a187_filteredAccel "Drive inverter: a187 filtered accel";
CM_ SG_ 1319 DI_a187_rawPedal "Drive inverter: a187 raw pedal";
CM_ SG_ 1319 DI_a187_systemTorqueCommand "Drive inverter: a187 system torque command";
CM_ SG_ 1319 DI_a189_accelPedal "Drive inverter: a189 accel pedal";
CM_ SG_ 1319 DI_a189_grade "Drive inverter: a189 grade";
CM_ SG_ 1319 DI_a189_brakePressed "Drive inverter: a189 brake pressed";
CM_ SG_ 1319 DI_a189_systemTorque "Drive inverter: a189 system torque";
CM_ SG_ 1319 DI_a189_motorSpeed "Drive inverter: a189 motor speed";
CM_ SG_ 1319 DI_a190_relativeTireTreadDepth "Drive inverter: a190 relative tire tread depth";
CM_ SG_ 1319 DI_a190_treadWearFactorFrL "Drive inverter: a190 tread wear factor fr l";
CM_ SG_ 1319 DI_a190_treadWearFactorFrR "Drive inverter: a190 tread wear factor fr r";
CM_ SG_ 1319 DI_a190_treadWearFactorReL "Drive inverter: a190 tread wear factor re l";
CM_ SG_ 1319 DI_a190_treadWearFactorAvgConfid "Drive inverter: a190 tread wear factor avg confidence";
CM_ SG_ 1319 DI_a190_tireFitment "Drive inverter: a190 tire fitment; raw 3 = signal not available (SNA)";
CM_ SG_ 1319 DI_a191_motorSpeed "Drive inverter: a191 motor speed";
CM_ SG_ 1319 DI_a191_reverseDeniedAfterCruise "Drive inverter: a191 reverse denied after cruise";
CM_ SG_ 1319 DI_a191_currentGear "Drive inverter: a191 current gear; raw 7 = signal not available (SNA)";
CM_ SG_ 1319 DI_a191_requestedGear "Drive inverter: a191 requested gear; raw 7 = signal not available (SNA)";
CM_ SG_ 1319 DI_a191_requestSource "Drive inverter: a191 request source";
CM_ SG_ 1319 DI_a191_timeSinceCruiseCancel "Drive inverter: a191 time since cruise cancel";
CM_ SG_ 1319 DI_a193_brakeTorqueFrL "Drive inverter: a193 brake torque fr l";
CM_ SG_ 1319 DI_a193_brakeTorqueFrLLastVal "Drive inverter: a193 brake torque fr l last val";
CM_ SG_ 1319 DI_a193_brakeTorqueFrLCurrVal "Drive inverter: a193 brake torque fr l curr val";
CM_ SG_ 1319 DI_a193_brakeTorqueFrR "Drive inverter: a193 brake torque fr r";
CM_ SG_ 1319 DI_a193_brakeTorqueFrRLastVal "Drive inverter: a193 brake torque fr r last val";
CM_ SG_ 1319 DI_a193_brakeTorqueFrRCurrVal "Drive inverter: a193 brake torque fr r curr val";
CM_ SG_ 1319 DI_a194_brakeTorqueReL "Drive inverter: a194 brake torque re l";
CM_ SG_ 1319 DI_a194_brakeTorqueReLLastVal "Drive inverter: a194 brake torque re l last val";
CM_ SG_ 1319 DI_a194_brakeTorqueReLCurrVal "Drive inverter: a194 brake torque re l curr val";
CM_ SG_ 1319 DI_a194_brakeTorqueReR "Drive inverter: a194 brake torque re r";
CM_ SG_ 1319 DI_a194_brakeTorqueReRLastVal "Drive inverter: a194 brake torque re r last val";
CM_ SG_ 1319 DI_a194_brakeTorqueReRCurrVal "Drive inverter: a194 brake torque re r curr val";
CM_ SG_ 1319 DI_a198_MCPressure "Drive inverter: a198 MC pressure";
CM_ SG_ 1319 DI_a198_MCPressureLastValue "Drive inverter: a198 MC pressure last value";
CM_ SG_ 1319 DI_a198_MCPressCurrValue "Drive inverter: a198 MC press curr value";
CM_ SG_ 1319 DI_a198_steeringAngle "Drive inverter: a198 steering angle";
CM_ SG_ 1319 DI_a198_steeringAngleLastVal "Drive inverter: a198 steering angle last val";
CM_ SG_ 1319 DI_a198_steeringAngleCurrVal "Drive inverter: a198 steering angle curr val";
CM_ SG_ 1319 DI_a199_muVehicleLearnDown "Drive inverter: a199 mu vehicle learn down";
CM_ SG_ 1319 DI_a199_muVehicleDecFilt "Drive inverter: a199 mu vehicle dec filt";
CM_ SG_ 1319 DI_a199_bankAngle "Drive inverter: a199 bank angle";
CM_ SG_ 1319 DI_a199_lateralAccelFilt "Drive inverter: a199 lateral accel filt";
CM_ SG_ 1319 DI_a199_driverIntendedYawRate "Drive inverter: a199 driver intended yaw rate";
CM_ SG_ 1319 DI_a199_vehicleVelocity "Drive inverter: a199 vehicle velocity";
CM_ SG_ 1319 DI_a199_sensorYawRate "Drive inverter: a199 sensor yaw rate";
CM_ SG_ 1319 DI_a199_preControlActive "Drive inverter: a199 pre control active";
CM_ SG_ 1319 DI_a199_oversteerdMzActive "Drive inverter: a199 oversteerd mz active";
CM_ SG_ 1319 DI_a199_decelControlActive "Drive inverter: a199 decel control active";
CM_ SG_ 1319 DI_a199_understeerdMzActive "Drive inverter: a199 understeerd mz active";
CM_ SG_ 1319 DI_a199_vdcMode "Drive inverter: a199 vdc mode";
CM_ SG_ 1319 DI_a200_MBPCheckStatus "Drive inverter: a200 MBP check status";
CM_ SG_ 1319 DI_a200_MBPFailedCase "Drive inverter: a200 MBP failed case";
CM_ SG_ 1319 DI_a200_MBPFaultProbability "Drive inverter: a200 MBP fault probability";
CM_ SG_ 1319 DI_a202_reason "Drive inverter: a202 reason";
CM_ SG_ 1319 DI_a202_movement "Drive inverter: a202 movement";
CM_ SG_ 1319 DI_a202_sysStateExitCondition "Drive inverter: a202 sys state exit condition";
CM_ SG_ 1319 DI_a203_ptcStateLocal "Drive inverter: a203 ptc state local; raw 6 = signal not available (SNA)";
CM_ SG_ 1319 DI_a203_btcState "Drive inverter: a203 btc state";
CM_ SG_ 1319 DI_a204_longAccel "Drive inverter: a204 long accel";
CM_ SG_ 1319 DI_a204_longAccelLastVal "Drive inverter: a204 long accel last val";
CM_ SG_ 1319 DI_a204_longAccelCurrVal "Drive inverter: a204 long accel curr val";
CM_ SG_ 1319 DI_a204_rollRate "Drive inverter: a204 roll rate";
CM_ SG_ 1319 DI_a204_rollRateLastVal "Drive inverter: a204 roll rate last val";
CM_ SG_ 1319 DI_a204_rollRateCurrVal "Drive inverter: a204 roll rate curr val";
CM_ SG_ 1319 DI_a205_latAccel "Drive inverter: a205 lat accel";
CM_ SG_ 1319 DI_a205_latAccelLastVal "Drive inverter: a205 lat accel last val";
CM_ SG_ 1319 DI_a205_latAccelCurrVal "Drive inverter: a205 lat accel curr val";
CM_ SG_ 1319 DI_a205_pitchRate "Drive inverter: a205 pitch rate";
CM_ SG_ 1319 DI_a205_pitchRateLastVal "Drive inverter: a205 pitch rate last val";
CM_ SG_ 1319 DI_a205_pitchRateCurrVal "Drive inverter: a205 pitch rate curr val";
CM_ SG_ 1319 DI_a206_verticalAccel "Drive inverter: a206 vertical accel";
CM_ SG_ 1319 DI_a206_verticalAccelLastVal "Drive inverter: a206 vertical accel last val";
CM_ SG_ 1319 DI_a206_verticalAccelCurrVal "Drive inverter: a206 vertical accel curr val";
CM_ SG_ 1319 DI_a206_yawRate "Drive inverter: a206 yaw rate";
CM_ SG_ 1319 DI_a206_yawRateLastVal "Drive inverter: a206 yaw rate last val";
CM_ SG_ 1319 DI_a206_yawRateCurrVal "Drive inverter: a206 yaw rate curr val";
CM_ SG_ 1319 DI_a210_ptcStateGlobal "Drive inverter: a210 ptc state global; raw 3 = signal not available (SNA)";
CM_ SG_ 1319 DI_a210_espActuatorState "Drive inverter: a210 esp actuator state";
CM_ SG_ 1319 DI_a210_brakeTmpEstStateFaulted "Drive inverter: a210 brake tmp est state faulted";
CM_ SG_ 1319 DI_a210_secondaryBrakeActuatorIs "Drive inverter: a210 secondary brake actuator is master";
CM_ SG_ 1319 DI_a223_ptcStateLocal "Drive inverter: a223 ptc state local; raw 6 = signal not available (SNA)";
CM_ SG_ 1319 DI_a223_btcState "Drive inverter: a223 btc state";
CM_ SG_ 1319 DI_a223_velocityEstimatorState "Drive inverter: a223 velocity estimator state";
CM_ SG_ 1319 DI_a223_addState_dir "Drive inverter: a223 add state dir";
CM_ SG_ 1319 DI_a223_addState_dif "Drive inverter: a223 add state dif";
CM_ SG_ 1319 DI_a223_DI_tractionControlMode "Drive inverter: a223 DI traction control mode";
CM_ SG_ 1319 DI_a223_UI_tractionControlMode "Drive inverter: a223 UI traction control mode";
CM_ SG_ 1319 DI_a223_vehicleVelocity "Drive inverter: a223 vehicle velocity";
CM_ SG_ 1319 DI_a223_musurf "Drive inverter: a223 musurf";
CM_ SG_ 1319 DI_a223_musurfHigh "Drive inverter: a223 musurf high";
CM_ SG_ 1319 DI_a223_driveTCActive "Drive inverter: a223 drive TC active";
CM_ SG_ 1319 DI_a223_regenTCActive "Drive inverter: a223 regen TC active";
CM_ SG_ 1319 DI_a223_surfaceUtility "Drive inverter: a223 surface utility";
CM_ SG_ 1319 DI_a224_brakeFLTemp "Drive inverter: a224 brake FL temp";
CM_ SG_ 1319 DI_a224_brakeFRTemp "Drive inverter: a224 brake FR temp";
CM_ SG_ 1319 DI_a224_brakeRLTemp "Drive inverter: a224 brake RL temp";
CM_ SG_ 1319 DI_a224_brakeRRTemp "Drive inverter: a224 brake RR temp";
CM_ SG_ 1319 DI_a227_hvState "Drive inverter: a227 hv state";
CM_ SG_ 1319 DI_a227_vehiclePowerState "Drive inverter: a227 vehicle power state";
CM_ SG_ 1319 DI_a230_CMP_HVStatus "Drive inverter: a230 CMP HV status";
CM_ SG_ 1319 DI_a230_CMPD_state "Drive inverter: a230 CMPD state";
CM_ SG_ 1319 DI_a232_velocityEstimatorState "Drive inverter: a232 velocity estimator state";
CM_ SG_ 1319 DI_a232_UI_tractionControlMode "Drive inverter: a232 UI traction control mode";
CM_ SG_ 1319 DI_a232_vehicleVelocity "Drive inverter: a232 vehicle velocity";
CM_ SG_ 1319 DI_a232_musurf "Drive inverter: a232 musurf";
CM_ SG_ 1319 DI_a232_musurfHigh "Drive inverter: a232 musurf high";
CM_ SG_ 1319 DI_a232_allWhlSpeedRotationAvail "Drive inverter: a232 all whl speed rotation avail";
CM_ SG_ 1319 DI_a232_BrakeMasterCylPressValid "Drive inverter: a232 brake master cyl press valid";
CM_ SG_ 1319 DI_a232_WheelBrakeTorquesValid "Drive inverter: a232 wheel brake torques valid";
CM_ SG_ 1319 DI_a232_AbsBrakeEventActiveValid "Drive inverter: a232 abs brake event active valid";
CM_ SG_ 1319 DI_a232_UndersteerActiveValid "Drive inverter: a232 understeer active valid";
CM_ SG_ 1319 DI_a232_OversteerActiveValid "Drive inverter: a232 oversteer active valid";
CM_ SG_ 1319 DI_a232_allMotorTorquesValid "Drive inverter: a232 all motor torques valid";
CM_ SG_ 1319 DI_a232_lateralAccelValid "Drive inverter: a232 lateral accel valid";
CM_ SG_ 1319 DI_a232_longitudinalAccelValid "Drive inverter: a232 longitudinal accel valid";
CM_ SG_ 1319 DI_a232_yawRateValid "Drive inverter: a232 yaw rate valid";
CM_ SG_ 1319 DI_a232_steerAngleValid "Drive inverter: a232 steer angle valid";
CM_ SG_ 1319 DI_a236_states "Drive inverter: a236 states";
CM_ SG_ 1319 DI_a237_lateralAccel "Drive inverter: a237 lateral accel";
CM_ SG_ 1319 DI_a237_verticalAccel "Drive inverter: a237 vertical accel";
CM_ SG_ 1319 DI_a237_longitudinalAccel "Drive inverter: a237 longitudinal accel";
CM_ SG_ 1319 DI_a237_vehicleSpeed "Drive inverter: a237 vehicle speed";
CM_ SG_ 1319 DI_a239_numRequests "Drive inverter: a239 num requests";
CM_ SG_ 1319 DI_a243_RCU_status "Drive inverter: a243 RCU status";
CM_ SG_ 1319 DI_a243_RCU_actuation "Drive inverter: a243 RCU actuation";
CM_ SG_ 1319 DI_a245_ebrStatus "Drive inverter: a245 ebr status";
CM_ SG_ 1319 DI_a245_vehicleHoldState "Drive inverter: a245 vehicle hold state";
CM_ SG_ 1319 DI_a246_onePedalDrivingState "Drive inverter: a246 one pedal driving state";
CM_ SG_ 1319 DI_a246_opdUnavailableReason "Drive inverter: a246 opd unavailable reason";
CM_ SG_ 1319 DI_a249_learning_DIF "Drive inverter: a249 learning DIF";
CM_ SG_ 1319 DI_a249_learning_DIR "Drive inverter: a249 learning DIR";
CM_ SG_ 1319 DI_a250_tasRequest "Drive inverter: a250 tas request";
CM_ SG_ 1319 DI_a250_tasMIA "Drive inverter: a250 tas MIA";
BA_DEF_ BO_ "GenMsgCycleTime" INT 0 3600000;
BA_DEF_ BO_ "GenMsgSendType" ENUM "Cyclic","NotUsed","NotUsed","NotUsed","NotUsed","NotUsed","NotUsed","IfActive","NoMsgSendType","NotUsed";
BA_DEF_ BO_ "VFrameFormat" ENUM "StandardCAN","ExtendedCAN","reserved","J1939PG","reserved","reserved","reserved","reserved","reserved","reserved","reserved","reserved","reserved","reserved","StandardCAN_FD","ExtendedCAN_FD";
BA_DEF_ BO_ "CANFD_BRS" ENUM "0","1";
BA_DEF_ SG_ "GenSigSNA" STRING;
BA_DEF_ SG_ "SystemSignalLongSymbol" STRING;
BA_DEF_ SG_ "Confidence" ENUM "validated","plausible","layout-only","contradicted";
BA_DEF_DEF_ "GenMsgCycleTime" 0;
BA_DEF_DEF_ "GenMsgSendType" "NoMsgSendType";
BA_DEF_DEF_ "VFrameFormat" "StandardCAN";
BA_DEF_DEF_ "CANFD_BRS" "1";
BA_DEF_DEF_ "GenSigSNA" "";
BA_DEF_DEF_ "SystemSignalLongSymbol" "";
BA_DEF_DEF_ "Confidence" "layout-only";
BA_ "GenMsgCycleTime" BO_ 935 1000;
BA_ "GenMsgSendType" BO_ 935 0;
BA_ "GenMsgCycleTime" BO_ 2005 100;
BA_ "GenMsgSendType" BO_ 2005 0;
BA_ "GenMsgCycleTime" BO_ 633 100;
BA_ "GenMsgSendType" BO_ 633 0;
BA_ "GenMsgCycleTime" BO_ 821 1000;
BA_ "GenMsgSendType" BO_ 821 0;
BA_ "GenMsgCycleTime" BO_ 2037 100;
BA_ "GenMsgSendType" BO_ 2037 0;
BA_ "GenMsgCycleTime" BO_ 917 100;
BA_ "GenMsgSendType" BO_ 917 0;
BA_ "GenMsgCycleTime" BO_ 614 1000;
BA_ "GenMsgSendType" BO_ 614 0;
BA_ "GenMsgCycleTime" BO_ 598 10;
BA_ "GenMsgSendType" BO_ 598 0;
BA_ "GenMsgCycleTime" BO_ 789 1000;
BA_ "GenMsgSendType" BO_ 789 0;
BA_ "GenMsgCycleTime" BO_ 1495 1000;
BA_ "GenMsgSendType" BO_ 1495 0;
BA_ "GenMsgCycleTime" BO_ 264 10;
BA_ "GenMsgSendType" BO_ 264 0;
BA_ "Confidence" SG_ 935 DIR_matrixIndex 1;
BA_ "SystemSignalLongSymbol" SG_ 935 DIR_a039_exceptionUndefinedInstr "DIR_a039_exceptionUndefinedInstruction";
BA_ "SystemSignalLongSymbol" SG_ 935 DIR_d085_driveInverterBoardFailu "DIR_d085_driveInverterBoardFailure";
BA_ "SystemSignalLongSymbol" SG_ 935 DIR_d138_inverterLVPowerSupplyLo "DIR_d138_inverterLVPowerSupplyLow";
BA_ "SystemSignalLongSymbol" SG_ 935 DIR_d143_wheelSpeedCorrelationIs "DIR_d143_wheelSpeedCorrelationIssue";
BA_ "SystemSignalLongSymbol" SG_ 935 DIR_a178_spindownLearningBrakeAl "DIR_a178_spindownLearningBrakeAllowed";
BA_ "SystemSignalLongSymbol" SG_ 935 DIR_a239_rotorDemagnetizationDet "DIR_a239_rotorDemagnetizationDetected";
BA_ "SystemSignalLongSymbol" SG_ 935 DIR_a249_highStatorTempFromResis "DIR_a249_highStatorTempFromResist";
BA_ "Confidence" SG_ 2005 DIR_debugSelector 1;
BA_ "Confidence" SG_ 2005 DIR_phaseOutBusbarTemp 0;
BA_ "GenSigSNA" SG_ 2005 DIR_phaseOutBusbarTemp "0";
BA_ "Confidence" SG_ 2005 DIR_phaseOutBusbarWeldTemp 0;
BA_ "GenSigSNA" SG_ 2005 DIR_phaseOutBusbarWeldTemp "0";
BA_ "Confidence" SG_ 2005 DIR_phaseOutLugTemp 0;
BA_ "GenSigSNA" SG_ 2005 DIR_phaseOutLugTemp "0";
BA_ "Confidence" SG_ 2005 DIR_dcLinkCapTemp 0;
BA_ "GenSigSNA" SG_ 2005 DIR_dcLinkCapTemp "0";
BA_ "Confidence" SG_ 2005 DIR_hvDcCableTemp 0;
BA_ "GenSigSNA" SG_ 2005 DIR_hvDcCableTemp "0";
BA_ "Confidence" SG_ 2005 DIR_negDcBusbarTemp 0;
BA_ "GenSigSNA" SG_ 2005 DIR_negDcBusbarTemp "0";
BA_ "Confidence" SG_ 2005 DIR_posDcBusbarTemp 0;
BA_ "GenSigSNA" SG_ 2005 DIR_posDcBusbarTemp "0";
BA_ "Confidence" SG_ 2005 DIR_statorEndWindingTemp 0;
BA_ "GenSigSNA" SG_ 2005 DIR_statorEndWindingTemp "0";
BA_ "Confidence" SG_ 2005 DIR_rotorMaxMagnetTemp 0;
BA_ "GenSigSNA" SG_ 2005 DIR_rotorMaxMagnetTemp "0";
BA_ "Confidence" SG_ 2005 DIR_lightSenseV 0;
BA_ "Confidence" SG_ 2005 DIR_pyroSenseV 0;
BA_ "Confidence" SG_ 2005 DIR_statorSlotWindingTemp 0;
BA_ "GenSigSNA" SG_ 2005 DIR_statorSlotWindingTemp "0";
BA_ "Confidence" SG_ 2005 DIR_intervalMaxHvBusV 0;
BA_ "Confidence" SG_ 633 DIR_hvStatusChecksum 0;
BA_ "Confidence" SG_ 633 DIR_hvStatusCounter 0;
BA_ "Confidence" SG_ 633 DIR_hvilCurrent 0;
BA_ "Confidence" SG_ 633 DIR_hvilCmVoltage 0;
BA_ "Confidence" SG_ 633 DIR_hvilStatus 0;
BA_ "GenSigSNA" SG_ 633 DIR_hvilStatus "3";
BA_ "Confidence" SG_ 633 DIR_hvilSupplyState 0;
BA_ "Confidence" SG_ 633 DIR_activeDischargeCtrl 0;
BA_ "Confidence" SG_ 633 DIR_activeDischargeStatus 0;
BA_ "Confidence" SG_ 633 DIR_vBat 0;
BA_ "Confidence" SG_ 633 DIR_vBatQF 0;
BA_ "Confidence" SG_ 633 DIR_powerStageSafeState 0;
BA_ "Confidence" SG_ 633 DIR_fluxState 0;
BA_ "Confidence" SG_ 633 DIR_vBusDiag 0;
BA_ "Confidence" SG_ 633 DIR_gateDriveState 0;
BA_ "Confidence" SG_ 633 DIR_gateDriveSupplyState 0;
BA_ "Confidence" SG_ 821 DIR_infoIndex 1;
BA_ "Confidence" SG_ 821 DIR_buildType 0;
BA_ "Confidence" SG_ 821 DIR_buildConfigurationId 0;
BA_ "Confidence" SG_ 821 DIR_hardwareId 0;
BA_ "Confidence" SG_ 821 DIR_componentId 0;
BA_ "Confidence" SG_ 821 DIR_pcbaId 0;
BA_ "Confidence" SG_ 821 DIR_assemblyId 0;
BA_ "Confidence" SG_ 821 DIR_usageId 0;
BA_ "Confidence" SG_ 821 DIR_subUsageId 0;
BA_ "Confidence" SG_ 821 DIR_motorType 0;
BA_ "GenSigSNA" SG_ 821 DIR_motorType "0";
BA_ "Confidence" SG_ 821 DIR_siliconType 0;
BA_ "Confidence" SG_ 821 DIR_mechSafeStateType 0;
BA_ "GenSigSNA" SG_ 821 DIR_mechSafeStateType "0";
BA_ "Confidence" SG_ 821 DIR_applicationCrc 0;
BA_ "Confidence" SG_ 821 DIR_oilPumpBuildType 0;
BA_ "Confidence" SG_ 821 DIR_oilPumpAppCrc 0;
BA_ "Confidence" SG_ 821 DIR_FPGA_version 0;
BA_ "GenSigSNA" SG_ 821 DIR_FPGA_version "255";
BA_ "Confidence" SG_ 821 DIR_appGitHash 0;
BA_ "Confidence" SG_ 821 DIR_bootGitHash 0;
BA_ "Confidence" SG_ 821 DIR_infoBootLdUdsProtocolVersion 0;
BA_ "Confidence" SG_ 821 DIR_bootloaderCrc 0;
BA_ "Confidence" SG_ 821 DIR_oilPumpPcbaId 0;
BA_ "Confidence" SG_ 821 DIR_oilPumpAssemblyId 0;
BA_ "Confidence" SG_ 821 DIR_oilPumpUsageId 0;
BA_ "Confidence" SG_ 821 DIR_refRotorFlux 0;
BA_ "Confidence" SG_ 821 DIR_refRotorOffset 0;
BA_ "GenSigSNA" SG_ 821 DIR_refRotorOffset "2048";
BA_ "Confidence" SG_ 821 DIR_speedWearTotal 0;
BA_ "GenSigSNA" SG_ 821 DIR_speedWearTotal "255";
BA_ "Confidence" SG_ 821 DIR_torqueWearTotal 0;
BA_ "GenSigSNA" SG_ 821 DIR_torqueWearTotal "255";
BA_ "Confidence" SG_ 2037 DIR_motorCurrent 0;
BA_ "Confidence" SG_ 2037 DIR_switchingFrequency 0;
BA_ "Confidence" SG_ 2037 DIR_targetFluxMode 0;
BA_ "Confidence" SG_ 2037 DIR_switchShortTestRetryCount 0;
BA_ "Confidence" SG_ 2037 DIR_keepAliveRequest 0;
BA_ "Confidence" SG_ 2037 DIR_motorStatusCounter 0;
BA_ "Confidence" SG_ 2037 DIR_motorStatusChecksum 0;
BA_ "Confidence" SG_ 917 DIR_oilPumpState 0;
BA_ "GenSigSNA" SG_ 917 DIR_oilPumpState "7";
BA_ "Confidence" SG_ 917 DIR_oilPumpFluidTQF 0;
BA_ "Confidence" SG_ 917 DIR_oilPumpLeadAngle 0;
BA_ "Confidence" SG_ 917 DIR_oilPumpFlowTarget 0;
BA_ "GenSigSNA" SG_ 917 DIR_oilPumpFlowTarget "255";
BA_ "Confidence" SG_ 917 DIR_oilPumpFlowActual 0;
BA_ "GenSigSNA" SG_ 917 DIR_oilPumpFlowActual "255";
BA_ "Confidence" SG_ 917 DIR_oilPumpFluidT 0;
BA_ "GenSigSNA" SG_ 917 DIR_oilPumpFluidT "255";
BA_ "Confidence" SG_ 917 DIR_oilPumpPhaseCurrent 0;
BA_ "GenSigSNA" SG_ 917 DIR_oilPumpPhaseCurrent "255";
BA_ "Confidence" SG_ 917 DIR_oilPumpPressureEstimate 0;
BA_ "GenSigSNA" SG_ 917 DIR_oilPumpPressureEstimate "255";
BA_ "Confidence" SG_ 917 DIR_oilPumpPressureExpected 0;
BA_ "GenSigSNA" SG_ 917 DIR_oilPumpPressureExpected "255";
BA_ "Confidence" SG_ 917 DIR_oilPumpPressureResidual 0;
BA_ "GenSigSNA" SG_ 917 DIR_oilPumpPressureResidual "255";
BA_ "Confidence" SG_ 614 DIR_elecPower 0;
BA_ "GenSigSNA" SG_ 614 DIR_elecPower "1024";
BA_ "Confidence" SG_ 614 DIR_heatPowerOptimal 0;
BA_ "Confidence" SG_ 614 DIR_heatPowerMax 0;
BA_ "Confidence" SG_ 614 DIR_heatPowerActual 0;
BA_ "Confidence" SG_ 614 DIR_excessHeatCommand 0;
BA_ "Confidence" SG_ 614 DIR_drivePowerMax 0;
BA_ "GenSigSNA" SG_ 614 DIR_drivePowerMax "511";
BA_ "Confidence" SG_ 598 DIR_statusChecksum 0;
BA_ "Confidence" SG_ 598 DIR_statusCounter 0;
BA_ "Confidence" SG_ 598 DIR_state 0;
BA_ "Confidence" SG_ 598 DIR_soptState 1;
BA_ "GenSigSNA" SG_ 598 DIR_soptState "8";
BA_ "Confidence" SG_ 598 DIR_adState 1;
BA_ "Confidence" SG_ 598 DIR_lvSupplyV 0;
BA_ "Confidence" SG_ 598 DIR_driveModeState 1;
BA_ "Confidence" SG_ 598 DIR_wasteState 1;
BA_ "Confidence" SG_ 598 DIR_haltRequest 1;
BA_ "Confidence" SG_ 598 DIR_axleSpeedLimitRequest 1;
BA_ "Confidence" SG_ 598 DIR_adDirection 1;
BA_ "Confidence" SG_ 598 DIR_spinDownLearningState 1;
BA_ "Confidence" SG_ 598 DIR_spinDownLearningMode 1;
BA_ "Confidence" SG_ 789 DIR_tempIndex 1;
BA_ "Confidence" SG_ 789 DIR_inverterTQF 0;
BA_ "Confidence" SG_ 789 DIR_pcbT 0;
BA_ "GenSigSNA" SG_ 789 DIR_pcbT "0";
BA_ "Confidence" SG_ 789 DIR_inverterT 0;
BA_ "Confidence" SG_ 789 DIR_statorT 0;
BA_ "GenSigSNA" SG_ 789 DIR_statorT "0";
BA_ "Confidence" SG_ 789 DIR_dcCapT 0;
BA_ "GenSigSNA" SG_ 789 DIR_dcCapT "0";
BA_ "Confidence" SG_ 789 DIR_heatsinkT 0;
BA_ "GenSigSNA" SG_ 789 DIR_heatsinkT "0";
BA_ "Confidence" SG_ 789 DIR_inverterTpct 0;
BA_ "Confidence" SG_ 789 DIR_statorTpct 0;
BA_ "Confidence" SG_ 789 DIR_fluidInTemp 0;
BA_ "GenSigSNA" SG_ 789 DIR_fluidInTemp "0";
BA_ "Confidence" SG_ 789 DIR_normalFetBurnIn 0;
BA_ "GenSigSNA" SG_ 789 DIR_normalFetBurnIn "65535";
BA_ "Confidence" SG_ 789 DIR_additionalFetBurnIn 0;
BA_ "GenSigSNA" SG_ 789 DIR_additionalFetBurnIn "65535";
BA_ "Confidence" SG_ 789 DIR_currentWeibullMiles 0;
BA_ "GenSigSNA" SG_ 789 DIR_currentWeibullMiles "32767";
BA_ "Confidence" SG_ 789 DIR_endOfServiceWeibullMiles 0;
BA_ "GenSigSNA" SG_ 789 DIR_endOfServiceWeibullMiles "32767";
BA_ "Confidence" SG_ 789 DIR_burnInDamageRatio 0;
BA_ "GenSigSNA" SG_ 789 DIR_burnInDamageRatio "511";
BA_ "Confidence" SG_ 789 DIR_inverterSensorEst 0;
BA_ "Confidence" SG_ 789 DIR_inverterHS1Est 0;
BA_ "Confidence" SG_ 789 DIR_initialBurnInVehicleOdometer 0;
BA_ "GenSigSNA" SG_ 789 DIR_initialBurnInVehicleOdometer "4294967295";
BA_ "Confidence" SG_ 789 DIR_inverterHS2Est 0;
BA_ "Confidence" SG_ 789 DIR_inverterInletEst 0;
BA_ "Confidence" SG_ 789 DIR_statorHousingTemp 0;
BA_ "GenSigSNA" SG_ 789 DIR_statorHousingTemp "0";
BA_ "Confidence" SG_ 1495 DIR_passiveInletTempReq 0;
BA_ "Confidence" SG_ 1495 DIR_activeInletTempReq 0;
BA_ "Confidence" SG_ 1495 DIR_coolantFlowReq 0;
BA_ "Confidence" SG_ 1495 DIR_oilFlowReq 0;
BA_ "GenSigSNA" SG_ 1495 DIR_oilFlowReq "255";
BA_ "Confidence" SG_ 1495 DIR_criticalFlowReq 0;
BA_ "Confidence" SG_ 1495 DIR_burnInStatus 0;
BA_ "Confidence" SG_ 264 DIR_torqueChecksum 0;
BA_ "Confidence" SG_ 264 DIR_torqueCounter 0;
BA_ "Confidence" SG_ 264 DIR_torqueCommand 0;
BA_ "GenSigSNA" SG_ 264 DIR_torqueCommand "4096";
BA_ "Confidence" SG_ 264 DIR_axleSpeedQF 0;
BA_ "Confidence" SG_ 264 DIR_torqueActual 0;
BA_ "GenSigSNA" SG_ 264 DIR_torqueActual "4096";
BA_ "Confidence" SG_ 264 DIR_axleSpeed 0;
BA_ "GenSigSNA" SG_ 264 DIR_axleSpeed "32768";
BA_ "Confidence" SG_ 264 DIR_axleTorqueQF 0;
BA_ "Confidence" SG_ 264 DIR_axlePowerCalcQF 0;
BA_ "Confidence" SG_ 264 DIR_gear 0;
BA_ "GenSigSNA" SG_ 264 DIR_gear "7";
BA_ "Confidence" SG_ 1558 DIR_udsResponseData 1;
BA_ "Confidence" SG_ 1319 DI_alertID 1;
BA_ "Confidence" SG_ 1319 DI_alertState 1;
BA_ "Confidence" SG_ 1319 DI_a004_unavailableReason 1;
BA_ "GenSigSNA" SG_ 1319 DI_a004_unavailableReason "0";
BA_ "Confidence" SG_ 1319 DI_a007_button 1;
BA_ "Confidence" SG_ 1319 DI_a007_buttonStuckTime 1;
BA_ "Confidence" SG_ 1319 DI_a012_accel1SupplyV 1;
BA_ "Confidence" SG_ 1319 DI_a012_accel2SupplyV 1;
BA_ "Confidence" SG_ 1319 DI_a013_errorType 1;
BA_ "Confidence" SG_ 1319 DI_a015_reason 1;
BA_ "Confidence" SG_ 1319 DI_a020_difHvilStatus 1;
BA_ "GenSigSNA" SG_ 1319 DI_a020_difHvilStatus "3";
BA_ "Confidence" SG_ 1319 DI_a020_dirHvilStatus 1;
BA_ "GenSigSNA" SG_ 1319 DI_a020_dirHvilStatus "3";
BA_ "Confidence" SG_ 1319 DI_a020_vehiclePowerState 1;
BA_ "Confidence" SG_ 1319 DI_a020_hvilSystemStatus 1;
BA_ "GenSigSNA" SG_ 1319 DI_a020_hvilSystemStatus "3";
BA_ "Confidence" SG_ 1319 DI_a021_packVoltage 1;
BA_ "Confidence" SG_ 1319 DI_a021_maxBusVoltage 1;
BA_ "Confidence" SG_ 1319 DI_a024_pedalPos 1;
BA_ "Confidence" SG_ 1319 DI_a024_currentGear 1;
BA_ "GenSigSNA" SG_ 1319 DI_a024_currentGear "7";
BA_ "Confidence" SG_ 1319 DI_a025_backfillState 1;
BA_ "Confidence" SG_ 1319 DI_a025_bfillUnavailableReason 1;
BA_ "Confidence" SG_ 1319 DI_a051_dcCableCurrentEst 1;
BA_ "Confidence" SG_ 1319 DI_a051_packCurrent 1;
BA_ "Confidence" SG_ 1319 DI_a062_limpReason 1;
BA_ "Confidence" SG_ 1319 DI_a063_gpoReason 1;
BA_ "Confidence" SG_ 1319 DI_a064_hvState 1;
BA_ "Confidence" SG_ 1319 DI_a064_vehiclePowerState 1;
BA_ "Confidence" SG_ 1319 DI_a064_vehicleSpeed 1;
BA_ "Confidence" SG_ 1319 DI_a074_recoveredGear 1;
BA_ "GenSigSNA" SG_ 1319 DI_a074_recoveredGear "7";
BA_ "Confidence" SG_ 1319 DI_a074_vehicleSpeed 1;
BA_ "Confidence" SG_ 1319 DI_a074_unit0Gear 1;
BA_ "GenSigSNA" SG_ 1319 DI_a074_unit0Gear "7";
BA_ "Confidence" SG_ 1319 DI_a074_unit1Gear 1;
BA_ "GenSigSNA" SG_ 1319 DI_a074_unit1Gear "7";
BA_ "Confidence" SG_ 1319 DI_a074_unit2Gear 1;
BA_ "GenSigSNA" SG_ 1319 DI_a074_unit2Gear "7";
BA_ "Confidence" SG_ 1319 DI_a074_failureReason 1;
BA_ "Confidence" SG_ 1319 DI_a074_epbSystemStatus 1;
BA_ "GenSigSNA" SG_ 1319 DI_a074_epbSystemStatus "15";
BA_ "Confidence" SG_ 1319 DI_a076_lvSupplyV 1;
BA_ "Confidence" SG_ 1319 DI_a077_lvSupplyV 1;
BA_ "SystemSignalLongSymbol" SG_ 1319 DI_a086_DPB_redundantBrakingStat "DI_a086_DPB_redundantBrakingStatus";
BA_ "Confidence" SG_ 1319 DI_a090_reason 1;
BA_ "SystemSignalLongSymbol" SG_ 1319 DI_a091_ESP_redundantBrakingStat "DI_a091_ESP_redundantBrakingStatus";
BA_ "Confidence" SG_ 1319 DI_a097_errorType 1;
BA_ "Confidence" SG_ 1319 DI_a098_errorCode 1;
BA_ "Confidence" SG_ 1319 DI_a104_proxIrrationalReason 1;
BA_ "Confidence" SG_ 1319 DI_a120_blendingState 1;
BA_ "Confidence" SG_ 1319 DI_a120_blendingUnavailableReaso 1;
BA_ "SystemSignalLongSymbol" SG_ 1319 DI_a120_blendingUnavailableReaso "DI_a120_blendingUnavailableReason";
BA_ "Confidence" SG_ 1319 DI_a124_undrivenWheelMPH 1;
BA_ "Confidence" SG_ 1319 DI_a124_cruiseFaultReason 1;
BA_ "GenSigSNA" SG_ 1319 DI_a124_cruiseFaultReason "17";
BA_ "Confidence" SG_ 1319 DI_a124_cruiseFaultStack 1;
BA_ "GenSigSNA" SG_ 1319 DI_a124_cruiseFaultStack "0";
BA_ "Confidence" SG_ 1319 DI_a125_maxDischargeCurrent 1;
BA_ "Confidence" SG_ 1319 DI_a125_maxChargeCurrent 1;
BA_ "Confidence" SG_ 1319 DI_a125_minBusVoltage 1;
BA_ "Confidence" SG_ 1319 DI_a130_aebFaultReason 1;
BA_ "GenSigSNA" SG_ 1319 DI_a130_aebFaultReason "6";
BA_ "Confidence" SG_ 1319 DI_a130_aebSmState 1;
BA_ "Confidence" SG_ 1319 DI_a130_dasAebEvent 1;
BA_ "GenSigSNA" SG_ 1319 DI_a130_dasAebEvent "3";
BA_ "Confidence" SG_ 1319 DI_a130_aebBrakeTorqueCommand 1;
BA_ "Confidence" SG_ 1319 DI_a131_warnSpeedLimit 1;
BA_ "Confidence" SG_ 1319 DI_a133_vhldGrade 1;
BA_ "Confidence" SG_ 1319 DI_a134_wheelSpeedDiffFrL 1;
BA_ "Confidence" SG_ 1319 DI_a134_wheelSpeedDiffFrR 1;
BA_ "Confidence" SG_ 1319 DI_a134_wheelSpeedDiffReL 1;
BA_ "Confidence" SG_ 1319 DI_a134_wheelSpeedDiffReR 1;
BA_ "Confidence" SG_ 1319 DI_a135_vhldFaultReason 1;
BA_ "Confidence" SG_ 1319 DI_a135_vhldBrakeTorqueCommand 1;
BA_ "Confidence" SG_ 1319 DI_a135_vhldTotalBrakeTorque 1;
BA_ "Confidence" SG_ 1319 DI_a135_vhldPropulsiveTorque 1;
BA_ "Confidence" SG_ 1319 DI_a135_vhldGrade 1;
BA_ "SystemSignalLongSymbol" SG_ 1319 DI_a141_DAS_longControlTuningPar "DI_a141_DAS_longControlTuningParameters";
BA_ "SystemSignalLongSymbol" SG_ 1319 DI_a141_DAS_redundantBrakingCont "DI_a141_DAS_redundantBrakingControl";
BA_ "Confidence" SG_ 1319 DI_a146_panicReason 1;
BA_ "SystemSignalLongSymbol" SG_ 1319 DI_a158_IBST_redundantBrakingSta "DI_a158_IBST_redundantBrakingStatus";
BA_ "Confidence" SG_ 1319 DI_a160_kTire 1;
BA_ "Confidence" SG_ 1319 DI_a160_tireFitment 1;
BA_ "GenSigSNA" SG_ 1319 DI_a160_tireFitment "3";
BA_ "Confidence" SG_ 1319 DI_a160_wearFactorFrL 1;
BA_ "Confidence" SG_ 1319 DI_a160_wearFactorFrR 1;
BA_ "Confidence" SG_ 1319 DI_a160_wearFactorReL 1;
BA_ "Confidence" SG_ 1319 DI_a160_distanceSinceLastTireCon 1;
BA_ "GenSigSNA" SG_ 1319 DI_a160_distanceSinceLastTireCon "4095";
BA_ "SystemSignalLongSymbol" SG_ 1319 DI_a160_distanceSinceLastTireCon "DI_a160_distanceSinceLastTireConfig";
BA_ "Confidence" SG_ 1319 DI_a162_shiftDeniedReason 1;
BA_ "Confidence" SG_ 1319 DI_a162_motorSpeed 1;
BA_ "Confidence" SG_ 1319 DI_a162_autonomyBehavior 1;
BA_ "Confidence" SG_ 1319 DI_a162_pedalPos 1;
BA_ "Confidence" SG_ 1319 DI_a162_currentGear 1;
BA_ "GenSigSNA" SG_ 1319 DI_a162_currentGear "7";
BA_ "Confidence" SG_ 1319 DI_a162_requestedGear 1;
BA_ "GenSigSNA" SG_ 1319 DI_a162_requestedGear "7";
BA_ "Confidence" SG_ 1319 DI_a162_requestSource 1;
BA_ "Confidence" SG_ 1319 DI_a162_timeSinceCruiseCancel 1;
BA_ "Confidence" SG_ 1319 DI_a162_sysStateExitCondition 1;
BA_ "Confidence" SG_ 1319 DI_a163_motorSpeed 1;
BA_ "Confidence" SG_ 1319 DI_a163_currentGear 1;
BA_ "GenSigSNA" SG_ 1319 DI_a163_currentGear "7";
BA_ "Confidence" SG_ 1319 DI_a163_requestedGear 1;
BA_ "GenSigSNA" SG_ 1319 DI_a163_requestedGear "7";
BA_ "Confidence" SG_ 1319 DI_a163_requestSource 1;
BA_ "Confidence" SG_ 1319 DI_a164_motorSpeed 1;
BA_ "Confidence" SG_ 1319 DI_a164_pedalPos 1;
BA_ "Confidence" SG_ 1319 DI_a164_torqueDriver 1;
BA_ "Confidence" SG_ 1319 DI_a170_tireSeasonSelected 1;
BA_ "Confidence" SG_ 1319 DI_a170_kTire 1;
BA_ "Confidence" SG_ 1319 DI_a170_tireFitment 1;
BA_ "GenSigSNA" SG_ 1319 DI_a170_tireFitment "3";
BA_ "Confidence" SG_ 1319 DI_a170_wearFactorFrL 1;
BA_ "Confidence" SG_ 1319 DI_a170_wearFactorFrR 1;
BA_ "Confidence" SG_ 1319 DI_a170_wearFactorReL 1;
BA_ "Confidence" SG_ 1319 DI_a170_odometer 1;
BA_ "GenSigSNA" SG_ 1319 DI_a170_odometer "4095";
BA_ "Confidence" SG_ 1319 DI_a170_distanceSinceLastTireCon 1;
BA_ "GenSigSNA" SG_ 1319 DI_a170_distanceSinceLastTireCon "63";
BA_ "SystemSignalLongSymbol" SG_ 1319 DI_a170_distanceSinceLastTireCon "DI_a170_distanceSinceLastTireConfig";
BA_ "Confidence" SG_ 1319 DI_a172_motorSpeed 1;
BA_ "Confidence" SG_ 1319 DI_a172_pedalPos 1;
BA_ "Confidence" SG_ 1319 DI_a172_currentGear 1;
BA_ "GenSigSNA" SG_ 1319 DI_a172_currentGear "7";
BA_ "Confidence" SG_ 1319 DI_a172_timeSinceCruiseCancel 1;
BA_ "Confidence" SG_ 1319 DI_a173_brakeApply 1;
BA_ "Confidence" SG_ 1319 DI_a173_pedalPos 1;
BA_ "Confidence" SG_ 1319 DI_a175_crsNotAvailableReason 1;
BA_ "GenSigSNA" SG_ 1319 DI_a175_crsNotAvailableReason "20";
BA_ "Confidence" SG_ 1319 DI_a175_crsNotAvailableStack 1;
BA_ "GenSigSNA" SG_ 1319 DI_a175_crsNotAvailableStack "0";
BA_ "Confidence" SG_ 1319 DI_a177_newFitment 1;
BA_ "GenSigSNA" SG_ 1319 DI_a177_newFitment "3";
BA_ "Confidence" SG_ 1319 DI_a178_offsetValue 1;
BA_ "Confidence" SG_ 1319 DI_a180_crsNotAvailableReason 1;
BA_ "GenSigSNA" SG_ 1319 DI_a180_crsNotAvailableReason "20";
BA_ "Confidence" SG_ 1319 DI_a184_apcCancelReason 1;
BA_ "Confidence" SG_ 1319 DI_a184_apcUnavailableReason 1;
BA_ "Confidence" SG_ 1319 DI_a184_autoparkInternalState 1;
BA_ "Confidence" SG_ 1319 DI_a185_apcCancelReason 1;
BA_ "Confidence" SG_ 1319 DI_a185_apcUnavailableReason 1;
BA_ "Confidence" SG_ 1319 DI_a185_crsNotAvailableReason 1;
BA_ "GenSigSNA" SG_ 1319 DI_a185_crsNotAvailableReason "20";
BA_ "Confidence" SG_ 1319 DI_a185_crsFaultReason 1;
BA_ "GenSigSNA" SG_ 1319 DI_a185_crsFaultReason "17";
BA_ "Confidence" SG_ 1319 DI_a185_autoparkInternalState 1;
BA_ "Confidence" SG_ 1319 DI_a187_filteredAccel 1;
BA_ "Confidence" SG_ 1319 DI_a187_rawPedal 1;
BA_ "Confidence" SG_ 1319 DI_a187_systemTorqueCommand 1;
BA_ "Confidence" SG_ 1319 DI_a189_accelPedal 1;
BA_ "Confidence" SG_ 1319 DI_a189_grade 1;
BA_ "Confidence" SG_ 1319 DI_a189_systemTorque 1;
BA_ "Confidence" SG_ 1319 DI_a189_motorSpeed 1;
BA_ "Confidence" SG_ 1319 DI_a190_relativeTireTreadDepth 1;
BA_ "Confidence" SG_ 1319 DI_a190_treadWearFactorFrL 1;
BA_ "Confidence" SG_ 1319 DI_a190_treadWearFactorFrR 1;
BA_ "Confidence" SG_ 1319 DI_a190_treadWearFactorReL 1;
BA_ "Confidence" SG_ 1319 DI_a190_treadWearFactorAvgConfid 1;
BA_ "SystemSignalLongSymbol" SG_ 1319 DI_a190_treadWearFactorAvgConfid "DI_a190_treadWearFactorAvgConfidence";
BA_ "Confidence" SG_ 1319 DI_a190_tireFitment 1;
BA_ "GenSigSNA" SG_ 1319 DI_a190_tireFitment "3";
BA_ "Confidence" SG_ 1319 DI_a191_motorSpeed 1;
BA_ "Confidence" SG_ 1319 DI_a191_currentGear 1;
BA_ "GenSigSNA" SG_ 1319 DI_a191_currentGear "7";
BA_ "Confidence" SG_ 1319 DI_a191_requestedGear 1;
BA_ "GenSigSNA" SG_ 1319 DI_a191_requestedGear "7";
BA_ "Confidence" SG_ 1319 DI_a191_requestSource 1;
BA_ "Confidence" SG_ 1319 DI_a191_timeSinceCruiseCancel 1;
BA_ "Confidence" SG_ 1319 DI_a193_brakeTorqueFrL 1;
BA_ "Confidence" SG_ 1319 DI_a193_brakeTorqueFrLLastVal 1;
BA_ "Confidence" SG_ 1319 DI_a193_brakeTorqueFrLCurrVal 1;
BA_ "Confidence" SG_ 1319 DI_a193_brakeTorqueFrR 1;
BA_ "Confidence" SG_ 1319 DI_a193_brakeTorqueFrRLastVal 1;
BA_ "Confidence" SG_ 1319 DI_a193_brakeTorqueFrRCurrVal 1;
BA_ "Confidence" SG_ 1319 DI_a194_brakeTorqueReL 1;
BA_ "Confidence" SG_ 1319 DI_a194_brakeTorqueReLLastVal 1;
BA_ "Confidence" SG_ 1319 DI_a194_brakeTorqueReLCurrVal 1;
BA_ "Confidence" SG_ 1319 DI_a194_brakeTorqueReR 1;
BA_ "Confidence" SG_ 1319 DI_a194_brakeTorqueReRLastVal 1;
BA_ "Confidence" SG_ 1319 DI_a194_brakeTorqueReRCurrVal 1;
BA_ "Confidence" SG_ 1319 DI_a198_MCPressure 1;
BA_ "Confidence" SG_ 1319 DI_a198_MCPressureLastValue 1;
BA_ "Confidence" SG_ 1319 DI_a198_MCPressCurrValue 1;
BA_ "Confidence" SG_ 1319 DI_a198_steeringAngle 1;
BA_ "Confidence" SG_ 1319 DI_a198_steeringAngleLastVal 1;
BA_ "Confidence" SG_ 1319 DI_a198_steeringAngleCurrVal 1;
BA_ "Confidence" SG_ 1319 DI_a199_muVehicleLearnDown 1;
BA_ "Confidence" SG_ 1319 DI_a199_muVehicleDecFilt 1;
BA_ "Confidence" SG_ 1319 DI_a199_bankAngle 1;
BA_ "Confidence" SG_ 1319 DI_a199_lateralAccelFilt 1;
BA_ "Confidence" SG_ 1319 DI_a199_driverIntendedYawRate 1;
BA_ "Confidence" SG_ 1319 DI_a199_vehicleVelocity 1;
BA_ "Confidence" SG_ 1319 DI_a199_sensorYawRate 1;
BA_ "Confidence" SG_ 1319 DI_a199_preControlActive 1;
BA_ "Confidence" SG_ 1319 DI_a199_oversteerdMzActive 1;
BA_ "Confidence" SG_ 1319 DI_a199_decelControlActive 1;
BA_ "Confidence" SG_ 1319 DI_a199_understeerdMzActive 1;
BA_ "Confidence" SG_ 1319 DI_a199_vdcMode 1;
BA_ "Confidence" SG_ 1319 DI_a200_MBPCheckStatus 1;
BA_ "Confidence" SG_ 1319 DI_a200_MBPFailedCase 1;
BA_ "Confidence" SG_ 1319 DI_a200_MBPFaultProbability 1;
BA_ "Confidence" SG_ 1319 DI_a202_reason 1;
BA_ "Confidence" SG_ 1319 DI_a202_movement 1;
BA_ "Confidence" SG_ 1319 DI_a202_sysStateExitCondition 1;
BA_ "Confidence" SG_ 1319 DI_a203_ptcStateLocal 1;
BA_ "GenSigSNA" SG_ 1319 DI_a203_ptcStateLocal "6";
BA_ "Confidence" SG_ 1319 DI_a203_btcState 1;
BA_ "Confidence" SG_ 1319 DI_a204_longAccel 1;
BA_ "Confidence" SG_ 1319 DI_a204_longAccelLastVal 1;
BA_ "Confidence" SG_ 1319 DI_a204_longAccelCurrVal 1;
BA_ "Confidence" SG_ 1319 DI_a204_rollRate 1;
BA_ "Confidence" SG_ 1319 DI_a204_rollRateLastVal 1;
BA_ "Confidence" SG_ 1319 DI_a204_rollRateCurrVal 1;
BA_ "Confidence" SG_ 1319 DI_a205_latAccel 1;
BA_ "Confidence" SG_ 1319 DI_a205_latAccelLastVal 1;
BA_ "Confidence" SG_ 1319 DI_a205_latAccelCurrVal 1;
BA_ "Confidence" SG_ 1319 DI_a205_pitchRate 1;
BA_ "Confidence" SG_ 1319 DI_a205_pitchRateLastVal 1;
BA_ "Confidence" SG_ 1319 DI_a205_pitchRateCurrVal 1;
BA_ "Confidence" SG_ 1319 DI_a206_verticalAccel 1;
BA_ "Confidence" SG_ 1319 DI_a206_verticalAccelLastVal 1;
BA_ "Confidence" SG_ 1319 DI_a206_verticalAccelCurrVal 1;
BA_ "Confidence" SG_ 1319 DI_a206_yawRate 1;
BA_ "Confidence" SG_ 1319 DI_a206_yawRateLastVal 1;
BA_ "Confidence" SG_ 1319 DI_a206_yawRateCurrVal 1;
BA_ "Confidence" SG_ 1319 DI_a210_ptcStateGlobal 1;
BA_ "GenSigSNA" SG_ 1319 DI_a210_ptcStateGlobal "3";
BA_ "Confidence" SG_ 1319 DI_a210_espActuatorState 1;
BA_ "SystemSignalLongSymbol" SG_ 1319 DI_a210_secondaryBrakeActuatorIs "DI_a210_secondaryBrakeActuatorIsMaster";
BA_ "Confidence" SG_ 1319 DI_a223_ptcStateLocal 1;
BA_ "GenSigSNA" SG_ 1319 DI_a223_ptcStateLocal "6";
BA_ "Confidence" SG_ 1319 DI_a223_btcState 1;
BA_ "Confidence" SG_ 1319 DI_a223_velocityEstimatorState 1;
BA_ "Confidence" SG_ 1319 DI_a223_addState_dir 1;
BA_ "Confidence" SG_ 1319 DI_a223_addState_dif 1;
BA_ "Confidence" SG_ 1319 DI_a223_DI_tractionControlMode 1;
BA_ "Confidence" SG_ 1319 DI_a223_UI_tractionControlMode 1;
BA_ "Confidence" SG_ 1319 DI_a223_vehicleVelocity 1;
BA_ "Confidence" SG_ 1319 DI_a223_musurf 1;
BA_ "Confidence" SG_ 1319 DI_a223_musurfHigh 1;
BA_ "Confidence" SG_ 1319 DI_a223_driveTCActive 1;
BA_ "Confidence" SG_ 1319 DI_a223_regenTCActive 1;
BA_ "Confidence" SG_ 1319 DI_a223_surfaceUtility 1;
BA_ "Confidence" SG_ 1319 DI_a224_brakeFLTemp 1;
BA_ "Confidence" SG_ 1319 DI_a224_brakeFRTemp 1;
BA_ "Confidence" SG_ 1319 DI_a224_brakeRLTemp 1;
BA_ "Confidence" SG_ 1319 DI_a224_brakeRRTemp 1;
BA_ "Confidence" SG_ 1319 DI_a227_hvState 1;
BA_ "Confidence" SG_ 1319 DI_a227_vehiclePowerState 1;
BA_ "Confidence" SG_ 1319 DI_a232_velocityEstimatorState 1;
BA_ "Confidence" SG_ 1319 DI_a232_UI_tractionControlMode 1;
BA_ "Confidence" SG_ 1319 DI_a232_vehicleVelocity 1;
BA_ "Confidence" SG_ 1319 DI_a232_musurf 1;
BA_ "Confidence" SG_ 1319 DI_a232_musurfHigh 1;
BA_ "Confidence" SG_ 1319 DI_a232_allWhlSpeedRotationAvail 1;
BA_ "Confidence" SG_ 1319 DI_a232_BrakeMasterCylPressValid 1;
BA_ "Confidence" SG_ 1319 DI_a232_WheelBrakeTorquesValid 1;
BA_ "Confidence" SG_ 1319 DI_a232_AbsBrakeEventActiveValid 1;
BA_ "Confidence" SG_ 1319 DI_a232_UndersteerActiveValid 1;
BA_ "Confidence" SG_ 1319 DI_a232_OversteerActiveValid 1;
BA_ "Confidence" SG_ 1319 DI_a232_allMotorTorquesValid 1;
BA_ "Confidence" SG_ 1319 DI_a232_lateralAccelValid 1;
BA_ "Confidence" SG_ 1319 DI_a232_longitudinalAccelValid 1;
BA_ "Confidence" SG_ 1319 DI_a232_yawRateValid 1;
BA_ "Confidence" SG_ 1319 DI_a232_steerAngleValid 1;
BA_ "Confidence" SG_ 1319 DI_a237_lateralAccel 1;
BA_ "Confidence" SG_ 1319 DI_a237_verticalAccel 1;
BA_ "Confidence" SG_ 1319 DI_a237_longitudinalAccel 1;
BA_ "Confidence" SG_ 1319 DI_a237_vehicleSpeed 1;
BA_ "Confidence" SG_ 1319 DI_a245_ebrStatus 1;
BA_ "Confidence" SG_ 1319 DI_a245_vehicleHoldState 1;
BA_ "Confidence" SG_ 1319 DI_a246_onePedalDrivingState 1;
BA_ "Confidence" SG_ 1319 DI_a246_opdUnavailableReason 1;
VAL_ 935 DIR_matrixIndex 4 "AlertMatrix4" 3 "AlertMatrix3" 2 "AlertMatrix2" 1 "AlertMatrix1" 0 "AlertMatrix0" ;
VAL_ 2005 DIR_debugSelector 132 "Mux132" 131 "Mux131" 128 "Mux128" 73 "Mux73" 72 "Mux72" 70 "Mux70" 69 "Mux69" 68 "Mux68" 67 "Mux67" 66 "Mux66" 64 "Mux64" 63 "Mux63" 52 "Mux52" 50 "Mux50" 49 "Mux49" 48 "Mux48" 47 "Mux47" 46 "Mux46" 44 "Mux44" 43 "Mux43" 42 "Mux42" 41 "Mux41" 40 "Mux40" 39 "Mux39" 38 "Mux38" 37 "Mux37" 36 "Mux36" 35 "Mux35" 34 "Mux34" 33 "Mux33" 32 "Mux32" ;
VAL_ 2005 DIR_phaseOutBusbarTemp 0 "SNA" ;
VAL_ 2005 DIR_phaseOutBusbarWeldTemp 0 "SNA" ;
VAL_ 2005 DIR_phaseOutLugTemp 0 "SNA" ;
VAL_ 2005 DIR_dcLinkCapTemp 0 "SNA" ;
VAL_ 2005 DIR_hvDcCableTemp 0 "SNA" ;
VAL_ 2005 DIR_negDcBusbarTemp 0 "SNA" ;
VAL_ 2005 DIR_posDcBusbarTemp 0 "SNA" ;
VAL_ 2005 DIR_statorEndWindingTemp 0 "SNA" ;
VAL_ 2005 DIR_rotorMaxMagnetTemp 0 "SNA" ;
VAL_ 2005 DIR_statorSlotWindingTemp 0 "SNA" ;
VAL_ 633 DIR_hvilStatus 3 "SNA" 2 "CLOSED" 1 "OPEN" 0 "DISABLED" ;
VAL_ 633 DIR_hvilSupplyState 2 "ACTIVE" 1 "INACTIVE" 0 "NOT_AVAILABLE" ;
VAL_ 633 DIR_vBatQF 1 "QUALIFIED" 0 "NOT_QUALIFIED" ;
VAL_ 633 DIR_powerStageSafeState 3 "PSTG_SAFESTATE_3PS_LOW" 2 "PSTG_SAFESTATE_3PS_HIGH" 1 "PSTG_SAFESTATE_ALL_OFF" 0 "PSTG_SAFESTATE_NONE" ;
VAL_ 633 DIR_fluxState 12 "DI_FLUXSTATE_DISABLED" 11 "DI_FLUXSTATE_MAGNET_FLUX_DETECT" 10 "DI_FLUXSTATE_STATIONARY_WASTE" 9 "DI_FLUXSTATE_FAULT" 7 "DI_FLUXSTATE_VCONTROL" 6 "DI_FLUXSTATE_ICONTROL" 5 "DI_FLUXSTATE_ENABLED" 4 "DI_FLUXSTATE_FLUX_DOWN" 3 "DI_FLUXSTATE_FLUX_UP" 2 "DI_FLUXSTATE_STANDBY" 1 "DI_FLUXSTATE_TEST" 0 "DI_FLUXSTATE_START" ;
VAL_ 633 DIR_gateDriveState 4 "PSTG_GD_STATE_NOT_CONFIGURED" 3 "PSTG_GD_STATE_CONFIGURED" 2 "PSTG_GD_STATE_CONFIGURING" 1 "PSTG_GD_STATE_SELFTEST" 0 "PSTG_GD_STATE_INIT" ;
VAL_ 633 DIR_gateDriveSupplyState 3 "PSTG_GD_SUPPLY_FALLING" 2 "PSTG_GD_SUPPLY_UP" 1 "PSTG_GD_SUPPLY_RISING" 0 "PSTG_GD_SUPPLY_DOWN" ;
VAL_ 821 DIR_infoIndex 255 "INFO_END" 44 "TRACKING_DATA_5" 43 "TRACKING_DATA_4" 42 "TRACKING_DATA_3" 41 "TRACKING_DATA_2" 40 "TRACKING_DATA_1" 34 "INFO_SUBCOMPONENT2_HWID" 33 "INFO_SUBCOMPONENT_HWID" 32 "INFO_SUBCOMPONENT2_GITHASH" 31 "INFO_SUBCOMPONENT_GITHASH" 23 "INFO_SUBCOMPONENT2" 20 "INFO_UDS_PROTOCOL_BOOTCRC" 19 "INFO_VERSION_DEPRECATED" 18 "INFO_BOOTLOADER_GITHASH" 17 "INFO_APP_GITHASH" 16 "INFO_SUBCOMPONENT" 15 "INFO_BOOTLOADER_CRC" 14 "INFO_BOOTLOADER_SVN" 13 "INFO_APP_CRC" 11 "INFO_PCBAID_ASSYID_USAGEID" 10 "INFO_BUILD_HWID_COMPONENTID" 9 "INFO_DEPRECATED_9" 8 "INFO_DEPRECATED_8" 7 "INFO_DEPRECATED_7" 6 "INFO_DEPRECATED_6" 5 "INFO_DEPRECATED_5" 4 "INFO_DEPRECATED_4" 3 "INFO_DEPRECATED_3" 2 "INFO_DEPRECATED_2" 1 "INFO_DEPRECATED_1" 0 "INFO_DEPRECATED_0" ;
VAL_ 821 DIR_buildType 4 "INFO_MFG_BUILD" 3 "INFO_TRACEABLE_CI_BUILD" 2 "INFO_LOCAL_BUILD" 1 "INFO_PLATFORM_BUILD" 0 "INFO_UNKNOWN_BUILD" ;
VAL_ 821 DIR_hardwareId 252 "CONFIGURABLE_HWID_PLACEHOLDER" ;
VAL_ 821 DIR_motorType 36 "DI_MOTOR_PM240C" 35 "DI_MOTOR_IM188A" 34 "DI_MOTOR_IM130E_AL" 32 "DI_MOTOR_PM261D" 31 "DI_MOTOR_PM216E" 20 "DI_MOTOR_PM215D_1KV" 18 "DI_MOTOR_IM260E_1KV" 17 "DI_MOTOR_IM260D_1KV" 16 "DI_MOTOR_PM261C" 15 "DI_MOTOR_PM215C_1KV" 14 "DI_MOTOR_IM260C_1KV" 13 "DI_MOTOR_PM215A_1KV" 12 "DI_MOTOR_IM260A_1KV" 11 "DI_MOTOR_IM228HEA" 10 "DI_MOTOR_PM228HEA" 9 "DI_MOTOR_PM275C" 8 "DI_MOTOR_PM291D" 7 "DI_MOTOR_PM291C" 6 "DI_MOTOR_PM228C" 5 "DI_MOTOR_PM350B" 4 "DI_MOTOR_PM275B" 3 "DI_MOTOR_IM130D_AL" 2 "DI_MOTOR_IM130D" 1 "DI_MOTOR_PM216D" 0 "DI_MOTOR_SNA" ;
VAL_ 821 DIR_siliconType 1 "IGBT" 0 "MOSFET" ;
VAL_ 821 DIR_mechSafeStateType 2 "DI_MECH_SAFE_STATE_TYPE_PRESENT" 1 "DI_MECH_SAFE_STATE_TYPE_NONE" 0 "DI_MECH_SAFE_STATE_TYPE_SNA" ;
VAL_ 821 DIR_oilPumpBuildType 4 "INFO_MFG_BUILD" 3 "INFO_TRACEABLE_CI_BUILD" 2 "INFO_LOCAL_BUILD" 1 "INFO_PLATFORM_BUILD" 0 "INFO_UNKNOWN_BUILD" ;
VAL_ 821 DIR_FPGA_version 255 "SNA" 254 "LOCAL_BUILD" ;
VAL_ 821 DIR_refRotorOffset -2048 "SNA" ;
VAL_ 821 DIR_speedWearTotal 255 "SNA" ;
VAL_ 821 DIR_torqueWearTotal 255 "SNA" ;
VAL_ 2037 DIR_targetFluxMode 2 "DI_FLUXMODE_FW" 1 "DI_FLUXMODE_FS" 0 "DI_FLUXMODE_OPTIMUM" ;
VAL_ 2037 DIR_keepAliveRequest 1 "KEEP_ALIVE" 0 "NO_REQUEST" ;
VAL_ 917 DIR_oilPumpState 7 "OIL_PUMP_SNA" 6 "OIL_PUMP_FAULTED" 2 "OIL_PUMP_COLD_STARTUP" 1 "OIL_PUMP_ENABLE" 0 "OIL_PUMP_STANDBY" ;
VAL_ 917 DIR_oilPumpFluidTQF 1 "OIL_PUMP_FLUIDT_HIGH_CONFIDENCE" 0 "OIL_PUMP_FLUIDT_LOW_CONFIDENCE" ;
VAL_ 917 DIR_oilPumpFlowTarget 255 "SNA" ;
VAL_ 917 DIR_oilPumpFlowActual 255 "SNA" ;
VAL_ 917 DIR_oilPumpFluidT 255 "SNA" ;
VAL_ 917 DIR_oilPumpPhaseCurrent 255 "SNA" ;
VAL_ 917 DIR_oilPumpPressureEstimate 255 "SNA" ;
VAL_ 917 DIR_oilPumpPressureExpected 255 "SNA" ;
VAL_ 917 DIR_oilPumpPressureResidual 255 "SNA" ;
VAL_ 614 DIR_elecPower -1024 "SNA" ;
VAL_ 614 DIR_drivePowerMax 511 "SNA" ;
VAL_ 598 DIR_state 4 "DI_STATE_ENABLE" 3 "DI_STATE_ABORT" 2 "DI_STATE_FAULT" 1 "DI_STATE_STANDBY" 0 "DI_STATE_UNAVAILABLE" ;
VAL_ 598 DIR_soptState 9 "SOPT_DISABLED" 8 "SOPT_SNA" 7 "SOPT_TEST_FAILED" 6 "SOPT_TEST_SKIPPED" 5 "SOPT_TEST_PASSED" 4 "SOPT_CURRENT_TEST" 3 "SOPT_ASC_TEST" 2 "SOPT_PSTG_BRING_UP_AT_SPEED" 1 "SOPT_PSTG_BRING_UP" 0 "SOPT_INIT" ;
VAL_ 598 DIR_adState 3 "AD_STATE_FAULTED" 2 "AD_STATE_BACKUP" 1 "AD_STATE_NORMAL" 0 "AD_STATE_STARTUP" ;
VAL_ 598 DIR_driveModeState 1 "DM_STATE_DRIVE" 0 "DM_STATE_NONDRIVE" ;
VAL_ 598 DIR_wasteState 3 "DI_WASTE_STATIONARY" 2 "DI_WASTE_ON" 1 "DI_WASTE_AVAILABLE" 0 "DI_WASTE_UNAVAILABLE" ;
VAL_ 598 DIR_haltRequest 2 "DI_HALT_GRACEFUL" 1 "DI_HALT_IMMEDIATE" 0 "DI_HALT_NONE" ;
VAL_ 598 DIR_adDirection 1 "AD_FORWARD" 0 "AD_BACKWARD" ;
VAL_ 598 DIR_spinDownLearningState 9 "SPINDOWN_STATE_DONE" 8 "SPINDOWN_STATE_WRITE" 7 "SPINDOWN_STATE_VERIFY" 6 "SPINDOWN_STATE_CORRECT" 5 "SPINDOWN_STATE_MEASURE" 4 "SPINDOWN_STATE_COAST" 3 "SPINDOWN_STATE_ACCELERATE" 2 "SPINDOWN_STATE_WAIT" 1 "SPINDOWN_STATE_PRECHECK" 0 "SPINDOWN_STATE_INIT" ;
VAL_ 598 DIR_spinDownLearningMode 1 "SPINDOWN_MODE_ON_GROUND" 0 "SPINDOWN_MODE_ON_LIFT" ;
VAL_ 789 DIR_tempIndex 4 "Mux4" 3 "Mux3" 2 "Mux2" 1 "Mux1" 0 "Mux0" ;
VAL_ 789 DIR_inverterTQF 3 "INVERTERT_UNKNOWN" 2 "INVERTERT_RATIONAL" 1 "INVERTERT_IRRATIONAL" 0 "INVERTERT_INIT" ;
VAL_ 789 DIR_pcbT 0 "SNA" ;
VAL_ 789 DIR_statorT 0 "SNA" ;
VAL_ 789 DIR_dcCapT 0 "SNA" ;
VAL_ 789 DIR_heatsinkT 0 "SNA" ;
VAL_ 789 DIR_fluidInTemp 0 "SNA" ;
VAL_ 789 DIR_normalFetBurnIn 65535 "SNA" ;
VAL_ 789 DIR_additionalFetBurnIn 65535 "SNA" ;
VAL_ 789 DIR_currentWeibullMiles 32767 "SNA" ;
VAL_ 789 DIR_endOfServiceWeibullMiles 32767 "SNA" ;
VAL_ 789 DIR_burnInDamageRatio 511 "SNA" 510 "DEFAULT_1" ;
VAL_ 789 DIR_initialBurnInVehicleOdometer 4294967295 "SNA" ;
VAL_ 789 DIR_statorHousingTemp 0 "SNA" ;
VAL_ 1495 DIR_oilFlowReq 255 "SNA" ;
VAL_ 1495 DIR_criticalFlowReq 1 "ACTIVE" 0 "NOT_ACTIVE" ;
VAL_ 1495 DIR_burnInStatus 5 "COMPLETE" 4 "ACTIVE" 3 "INCOMPLETE" 2 "UNAVAILABLE" 1 "NOT_REQUIRED" 0 "INIT" ;
VAL_ 264 DIR_torqueCommand -4096 "SNA" ;
VAL_ 264 DIR_axleSpeedQF 2 "FAULTED" 1 "VALID" 0 "INVALID" ;
VAL_ 264 DIR_torqueActual -4096 "SNA" ;
VAL_ 264 DIR_axleSpeed -32768 "SNA" ;
VAL_ 264 DIR_axleTorqueQF 2 "FAULTED" 1 "VALID" 0 "INVALID" ;
VAL_ 264 DIR_axlePowerCalcQF 1 "VALID" 0 "INVALID" ;
VAL_ 264 DIR_gear 7 "DI_GEAR_SNA" 4 "DI_GEAR_D" 3 "DI_GEAR_N" 2 "DI_GEAR_R" 1 "DI_GEAR_P" 0 "DI_GEAR_INVALID" ;
VAL_ 1319 DI_alertID 255 "a255_manualRecoveryMode" 254 "a254_vehicleStuckDetected" 253 "a253_accelSynchWarn" 251 "a251_diPowerOnStateMismatch" 250 "a250_tasSpeedLimitActive" 249 "a249_spinDownLearningInProgress" 248 "a248_vdcPreControlHighDynamicActive" 246 "a246_opdUnavailable" 245 "a245_opdReducedWithoutEbr" 244 "a244_vseRLSMassMismatch" 243 "a243_rcuMIA" 242 "a242_vdcTrailerSwayDetected" 241 "a241_vdcMotorSpeed_dir" 240 "a240_torqueSplitStuck" 239 "a239_neutralRequestByPM" 238 "a238_secondaryCollisionMitigationActive" 237 "a237_undersideAbuse" 236 "a236_tasMIA" 235 "a235_trackModeActive" 233 "a233_frontWheelImpactDetected" 232 "a232_velocityEstimatorDegraded" 231 "a231_softSystemLimpMode" 230 "a230_cmpMIA" 228 "a228_brakeTempEstUnavailable" 227 "a227_contactorsNotClosed" 226 "a226_sysStartConditionNotMet" 225 "a225_vyEstimatorDegradedDebug" 224 "a224_brakeOverTemp" 223 "a223_tractionControlDisabled" 222 "a222_vdcDisabled" 221 "a221_vdcUndersteerdMzActive" 220 "a220_vdcUndersteerDecelActive" 219 "a219_vdcOversteerdMzActive" 218 "a218_vdcOSPreControlActive" 217 "a217_vdcOutputIrrational" 216 "a216_vdcMBPAlmostTripped" 215 "a215_vdcWheelSpeedRe" 214 "a214_vdcWheelSpeedFr" 213 "a213_lowMuProbabilityChange" 212 "a212_vdcWheelRotations" 211 "a211_vdcMotorSpeed_dif" 210 "a210_vdcOtherControllerStates" 208 "a208_vdcPowertrainTorque_dir" 207 "a207_vdcPowertrainTorque_dif" 206 "a206_vdcRcmVertical" 205 "a205_vdcRcmLateral" 204 "a204_vdcRcmLongitudinal" 203 "a203_TCReducedByADD" 202 "a202_excessHeatUnavailable" 201 "a201_decelTorqueLimited" 200 "a200_vdcModelBasedPlausibility" 199 "a199_vdcFaulted" 198 "a198_vdcEspMCPressAndSteering" 197 "a197_vdcEspWheelSaturations" 196 "a196_vdcEspSlipRe" 195 "a195_vdcEspSlipFr" 194 "a194_vdcBrakeTorqueRe" 193 "a193_vdcBrakeTorqueFr" 192 "a192_invalidOdometer" 191 "a191_brakeShiftReq" 190 "a190_tireRotationRecommended" 189 "a189_garageShiftWithPedal" 188 "a188_tireRotationRecommendedGhosted" 187 "a187_pedalMisapplication" 186 "a186_brakeStand" 185 "a185_autoparkAborted" 184 "a184_autoparkCanceled" 183 "a183_holdReleaseRqrd" 182 "a182_frontMotorMode" 181 "a181_rearMotorMode" 180 "a180_crsSeatbeltUnbuckled" 179 "a179_steeringAngleOffsetWarning" 178 "a178_steeringAngleOffsetFault" 177 "a177_tireFitmentChanged" 176 "a176_EBRreleased" 175 "a175_crsNotAvailable" 174 "a174_notOkToStartDrive" 173 "a173_bothPedalsPressed" 172 "a172_accelPressedInNP" 171 "a171_driveRailNotRequested" 170 "a170_tireConfigUpdated" 169 "a169_regenOffOverride" 168 "a168_proximityDriveDenial" 167 "a167_keyNotAuthenticated" 166 "a166_driverLeft" 165 "a165_cruiseCancelled" 164 "a164_brakeOverride" 163 "a163_shiftMotorSpeed" 162 "a162_shiftDenied" 161 "a161_epas3pMIA" 160 "a160_fastLearnComplete" 159 "a159_cruiseSelfCheck" 158 "a158_ibstMIA" 157 "a157_rcmMIA" 155 "a155_vcfrontMIA" 154 "a154_vdcRearSteering" 146 "a146_pbrkPanicEpbFault" 144 "a144_configMismatch" 143 "a143_mcuLimitActive" 142 "a142_potholeDetected" 141 "a141_dasMIA" 140 "a140_ptcMIA" 139 "a139_rearUnitDisabled" 138 "a138_frontUnitDisabled" 137 "a137_noCapableDriveUnits" 135 "a135_vehicleHoldFault" 134 "a134_wheelSpeedIrrational" 133 "a133_vehicleHoldTimedOut" 131 "a131_highSpeedWearLimit" 130 "a130_aebFault" 129 "a129_epbNotApplied" 125 "a125_noBatteryPower" 124 "a124_cruiseFault" 122 "a122_highStackUsage" 121 "a121_qualifiedBrakeEventMitigation" 120 "a120_regenBlendingUnavailable" 119 "a119_latentFaultCheckFailedOnce" 118 "a118_diImmobilizedForFactoryFailsafe" 117 "a117_latentFaultCheckTripped" 116 "a116_motorRecovered" 115 "a115_exceptionDataAbort2" 114 "a114_exceptionDataAbort" 113 "a113_lowBrakeMCPressure" 112 "a112_accelTrack1Incons" 111 "a111_idbMIA" 110 "a110_brakeMIA" 109 "a109_ahbWriteError" 108 "a108_appMIA" 107 "a107_idbBrakeCircuitPressureOffsetSuspect" 106 "a106_idleTaskStarving" 105 "a105_cpMIA" 104 "a104_proximityIrrational" 103 "a103_bbMIA" 102 "a102_exceptionPrefetchAbort" 101 "a101_eccTestData1" 100 "a100_nvramError" 99 "a099_threadOverrun" 98 "a098_eepromManagerError" 97 "a097_eepromError" 96 "a096_memoryError" 95 "a095_canOverrunBusA" 94 "a094_canDataBusA" 93 "a093_canHardwareBusA" 92 "a092_bmsMIA" 91 "a091_espMIA" 90 "a090_pmMIA" 89 "a089_sccmMIA" 88 "a088_uiMIA" 87 "a087_gtwMIA" 86 "a086_dpbMIA" 85 "a085_proximityInEnable" 84 "a084_eccTestData0" 83 "a083_brakePedalSensor" 82 "a082_accelTrack2" 81 "a081_accelTrack1" 80 "a080_accelSynch" 79 "a079_adcRefHigh" 78 "a078_adcRefLow" 77 "a077_lvSupplyUV" 76 "a076_lvSupplyOV" 75 "d075_incorrectImmobilizerKey" 74 "a074_unintendedResetAutoshift" 73 "d073_accelPedalVoltSupplyIssue" 72 "d072_accelPedalSensorIssue" 70 "a070_udsTransactionInitiated" 68 "a068_secondaryWheelSpeedIrrational" 67 "a067_canOverrunBusB" 66 "a066_canDataBusB" 65 "a065_canHardwareBusB" 64 "a064_pmsrmUnitMiaWithHvDown" 63 "a063_systemGracefulPowerOff" 62 "a062_systemLimpMode" 61 "a061_canHardwareBusE" 60 "a060_canOverrunBusE" 59 "a059_canDataBusE" 58 "a058_canHardwareBusD" 57 "a057_canOverrunBusD" 56 "a056_canDataBusD" 55 "a055_canHardwareBusC" 54 "a054_canOverrunBusC" 53 "a053_canDataBusC" 52 "a052_dirMIA" 51 "a051_batteryOvercurrent" 50 "d050_interfaceUnitCommunicationIssue" 49 "d049_invalidOdometerReading" 48 "a048_ecuLogAvailable" 47 "d047_interfacePowerSupplyIssue" 43 "a043_pmrMIA" 42 "a042_pmfMIA" 41 "a041_driverBrakeApplyStuck" 40 "a040_difMIA" 39 "a039_exceptionUndefinedInstruction" 36 "a036_sysStandbyUnitLimitedWait" 31 "a031_closureAccelerationLimit" 28 "a028_secondaryShifterMuted" 27 "a027_steeringAngleOffsetService" 26 "a026_parkPressedWithHighAPedal" 25 "a025_regenBackfillUnavailable" 24 "a024_holdNForNeutral" 23 "a023_carNotParked" 22 "a022_hw5vSupplyUV" 21 "a021_packOvervoltage" 20 "a020_systemHvilNotClosed" 19 "a019_hwAccelPedalPower" 18 "a018_hwLVSupplyUV" 17 "a017_hwPedalMonitor" 16 "a016_parkRequestByPM" 15 "a015_immobilizer" 14 "a014_secGearSelActivated" 13 "a013_eccError" 12 "a012_accel5VSupply" 10 "a010_unintendedReset" 7 "a007_secGearSelButtonStuck" 6 "a006_shifterUnavailable" 5 "a005_stalkPanicked" 4 "a004_smartShiftUnavailable" 3 "a003_suggestedGearOverride" 2 "a002_parkButtonDuringStalkReq" 1 "a001_frunkSpeedLimitActive" 0 "ALERT_DO_NOT_USE_ZERO" ;
VAL_ 1319 DI_alertState 1 "SET" 0 "CLEARED" ;
VAL_ 1319 DI_a004_unavailableReason 18 "UNAVAILABLE_DAS_MIA" 17 "UNAVAILABLE_DAS_NOT_CONFIDENT" 16 "UNAVAILABLE_DISPLAY_ERROR" 15 "UNAVAILABLE_VDC_UNAVAILABLE" 14 "UNAVAILABLE_VHLD_UNAVAILABLE" 13 "UNAVAILABLE_OPD_UNAVAILABLE" 12 "UNAVAILABLE_BLS_UNKNOWN" 11 "UNAVAILABLE_IBST_MIA" 10 "SILENT_UNAVAILABLE_AEB_ACTIVE" 9 "SILENT_UNAVAILABLE_CRUISE_REGULATING" 8 "SILENT_UNAVAILABLE_GTW_NOT_QUALIFIED" 7 "SILENT_UNAVAILABLE_SGS_ACTIVE" 6 "SILENT_UNAVAILABLE_CLOSURE_OPEN" 5 "SILENT_UNAVAILABLE_CHARGE_CABLE_CONNECTED" 4 "SILENT_UNAVAILABLE_DRIVER_BUCKLED_QF" 3 "SILENT_UNAVAILABLE_NON_STANDARD_MODE" 2 "SILENT_UNAVAILABLE_UI_DISABLE" 1 "UNAVAILABLE_NONE" 0 "UNAVAILABLE_SNA" ;
VAL_ 1319 DI_a007_button 3 "D" 2 "N" 1 "R" 0 "P" ;
VAL_ 1319 DI_a013_errorType 12 "RAM_CORRECTABLE_DMA" 11 "RAM_CORRECTABLE_CLA" 10 "RAM_CORRECTABLE_CPU" 9 "RAM_UNCORRECTABLE_DMA" 8 "RAM_UNCORRECTABLE_CLA" 7 "RAM_UNCORRECTABLE_CPU" 6 "FLASH_FAIL1_HIGH" 5 "FLASH_FAIL1_LOW" 4 "FLASH_FAIL0_HIGH" 3 "FLASH_FAIL0_LOW" 2 "FLASH_UNCORRECTABLE_HIGH" 1 "FLASH_UNCORRECTABLE_LOW" 0 "UNKNOWN" ;
VAL_ 1319 DI_a015_reason 1 "ARMED_AFTER_PREAUTH" 0 "AUTH_FAIL" ;
VAL_ 1319 DI_a020_difHvilStatus 3 "SNA" 2 "CLOSED" 1 "OPEN" 0 "DISABLED" ;
VAL_ 1319 DI_a020_dirHvilStatus 3 "SNA" 2 "CLOSED" 1 "OPEN" 0 "DISABLED" ;
VAL_ 1319 DI_a020_vehiclePowerState 3 "DRIVE" 2 "ACCESSORY" 1 "CONDITIONING" 0 "OFF" ;
VAL_ 1319 DI_a020_hvilSystemStatus 3 "SNA" 2 "CLOSED" 1 "OPEN" 0 "DISABLED" ;
VAL_ 1319 DI_a024_currentGear 7 "SNA" 4 "D" 3 "N" 2 "R" 1 "P" 0 "INVALID" ;
VAL_ 1319 DI_a025_backfillState 2 "ACTIVE" 1 "STANDBY" 0 "UNAVAILABLE" ;
VAL_ 1319 DI_a025_bfillUnavailableReason 18 "DI_LATENT_FAULT_TRIP" 17 "EBR_FULL_FAULT" 16 "PM_DISABLE_REQUEST_BPED" 15 "PM_DISABLE_REQUEST_BLEND" 14 "CARBON_CERAMIC_BRAKES" 13 "BRAKE_TEMP" 12 "EBR_FAULT" 11 "PM_DISABLE_REQUEST" 10 "TRACK_MODE_ACTIVE" 9 "VELOCITY_ESTIMATOR_UNAVAILABLE" 8 "TRACTION_CONTROL_UNAVAILABLE" 7 "ACTIVE_DAMPING_UNAVAILABLE" 6 "UI_COASTDOWN_MODE" 5 "SYSTEM_STATE" 4 "NON_DRIVE_GEAR" 3 "EBR_UNAVAILABLE" 2 "UI_DISABLE" 1 "GTW_DISABLE" 0 "NONE" ;
VAL_ 1319 DI_a062_limpReason 43 "UNIT_CHILL_REQUEST" 42 "DEGRADED_REQUEST_VCRIGHT" 41 "DEGRADED_REQUEST_VCLEFT" 40 "DEGRADED_REQUEST_PEPS" 39 "DEGRADED_REQUEST_SEPS" 38 "DEGRADED_REQUEST_PSFA" 37 "DEGRADED_REQUEST_SSFA" 36 "XTAL_OSCILLATOR" 35 "CURRENT_CORE_FALLBACK" 34 "MECHANICAL_SAFE_ST_UNAVAIL" 33 "MOTION_IN_DYNO" 32 "RESIST_STATOR_TEMP" 31 "OIL_PRESSURE_LOW" 30 "HEATSINK_SENSOR_IRRATIONAL" 29 "OIL_PUMP_FLUID_OVERTEMP" 28 "OIL_PUMP_FAILURE" 27 "FACTORY_GLIDER" 26 "SLAVE_MIA" 25 "SLAVE_REQUEST" 24 "CONTACTOR_WELD" 23 "CAPACITOR_OVERTEMP" 22 "GTW_MIA" 21 "TRQCMD_VALIDITY_UNKNOWN" 20 "DI_MIA" 19 "CONFIG_MISMATCH" 18 "HEATSINK_TEMP" 17 "PMREQUEST" 16 "PMHEARTBEAT" 15 "TRQ_CROSS_CHECK" 14 "EXTERNAL_COMMAND" 13 "WRONG_CS_CALIBRATION" 12 "STATOR_TEMP" 11 "DELTAT_TOO_NEGATIVE" 10 "DELTAT_TOO_POSITIVE" 9 "AMBIENT_TEMP" 8 "OUTLET_TEMP" 7 "LOW_FLOW" 6 "BMS_MIA" 5 "LV_SUPPLY_UNDERVOLTAGE" 4 "NO_FLUID" 3 "NO_FUNC_HEATSINK_SENSOR" 2 "NO_FUNC_STATORT_SENSOR" 1 "BUSV_SENSOR_IRRATIONAL" 0 "PHASE_IMBALANCE" ;
VAL_ 1319 DI_a063_gpoReason 15 "MANUAL_RECOVERY_DISTANCE_EXCEEDED" 14 "MOTION_EXPECTED_DURING_SPINDOWN_LEARNING" 13 "FACTORY_DRIVE_DISTANCE_EXCEEDED" 12 "DEGRADED_LIMP_NO_DECEL" 11 "DEGRADED_LIMP_TIMEOUT" 10 "SBW_NODE_UNAVAILABLE" 9 "MOTION_DURING_SPINDOWN_LEARNING" 8 "MOTOR_HALT_REQUEST" 7 "CAPACITOR_OVERTEMP" 6 "NOT_ENOUGH_12V" 5 "NO_BATTERY_POWER" 4 "AMBIENT_OVERTEMP" 3 "FLUID_DELTAT" 2 "STATOR_OVERTEMP" 1 "HEATSINK_OVERTEMP" 0 "OUTLET_OVERTEMP" ;
VAL_ 1319 DI_a064_hvState 6 "UP" 5 "UP_FOR_DC_CHARGE" 4 "UP_FOR_CHARGE" 3 "UP_FOR_DRIVE" 2 "GOING_DOWN" 1 "COMING_UP" 0 "DOWN" ;
VAL_ 1319 DI_a064_vehiclePowerState 3 "DRIVE" 2 "ACCESSORY" 1 "CONDITIONING" 0 "OFF" ;
VAL_ 1319 DI_a074_recoveredGear 7 "SNA" 4 "D" 3 "N" 2 "R" 1 "P" 0 "INVALID" ;
VAL_ 1319 DI_a074_unit0Gear 7 "SNA" 4 "D" 3 "N" 2 "R" 1 "P" 0 "INVALID" ;
VAL_ 1319 DI_a074_unit1Gear 7 "SNA" 4 "D" 3 "N" 2 "R" 1 "P" 0 "INVALID" ;
VAL_ 1319 DI_a074_unit2Gear 7 "SNA" 4 "D" 3 "N" 2 "R" 1 "P" 0 "INVALID" ;
VAL_ 1319 DI_a074_failureReason 10 "SAFETY_CONDITIONS_CHANGED" 9 "NO_UNINTENDED_RESET" 8 "EEPROM_WRITE_FAILED" 7 "SSM_NOT_READY" 6 "SPEED_POLARITY_MISMATCH" 5 "EPB_MIA_OR_ENGAGED" 4 "NOT_IN_NEUTRAL" 3 "UNIT_CONSENSUS_FAILED" 2 "RETRY_LIMIT_EXCEEDED" 1 "EEPROM_INVALID" 0 "RECOVERY_SUCCESS" ;
VAL_ 1319 DI_a074_epbSystemStatus 15 "SNA" 7 "RELEASING" 6 "PANIC_SKID" 5 "PANIC_EPB" 4 "FAULTED" 3 "APPLIED" 2 "REQUESTED" 1 "RELEASED" 0 "UNAVAILABLE" ;
VAL_ 1319 DI_a090_reason 1 "TOOFAST" 0 "TOOSLOW" ;
VAL_ 1319 DI_a097_errorType 6 "DPOT_WRITE" 5 "DPOT_READ" 4 "LOST" 3 "CRC" 2 "WRITE" 1 "READ" 0 "OPEN" ;
VAL_ 1319 DI_a098_errorCode 8 "POST_SWAP_ERASE" 7 "PRE_SWAP_ERASE" 6 "EXCEPTION_ERASE" 5 "NO_RECORD" 4 "BAD_RECORD" 3 "BAD_PAGE" 2 "INIT_ERASE" 1 "SWAP_WRITE" 0 "RECORD_WRITE" ;
VAL_ 1319 DI_a104_proxIrrationalReason 1 "CP_MISMATCH" 0 "PROX_HARDLINE_TOGGLE" ;
VAL_ 1319 DI_a120_blendingState 3 "FRICTION_ONLY" 2 "ACTIVE" 1 "STANDBY" 0 "UNAVAILABLE" ;
VAL_ 1319 DI_a120_blendingUnavailableReaso 18 "DI_LATENT_FAULT_TRIP" 17 "EBR_FULL_FAULT" 16 "PM_DISABLE_REQUEST_BPED" 15 "PM_DISABLE_REQUEST_BLEND" 14 "CARBON_CERAMIC_BRAKES" 13 "BRAKE_TEMP" 12 "EBR_FAULT" 11 "PM_DISABLE_REQUEST" 10 "TRACK_MODE_ACTIVE" 9 "VELOCITY_ESTIMATOR_UNAVAILABLE" 8 "TRACTION_CONTROL_UNAVAILABLE" 7 "ACTIVE_DAMPING_UNAVAILABLE" 6 "UI_COASTDOWN_MODE" 5 "SYSTEM_STATE" 4 "NON_DRIVE_GEAR" 3 "EBR_UNAVAILABLE" 2 "UI_DISABLE" 1 "GTW_DISABLE" 0 "NONE" ;
VAL_ 1319 DI_a124_cruiseFaultReason 22 "VHLD_FAULTED" 21 "CONFIG_MISMATCH" 20 "EPB_MIA" 19 "ACCEL_JERK_OUT_OF_ISO_BOUNDS" 17 "DAS_SNA" 16 "VELOCITY_ESTIMATE_NOT_NORMAL" 15 "ACCEL_OUT_OF_BOUNDS" 14 "EBR_FAULT" 13 "TC_FAULT" 12 "ESP_MIA" 11 "VDC_FAULT" 10 "EPB_FAULT" 9 "BRAKE_MIA" 8 "CRS_STATE_MISM" 7 "ABS_MIA" 6 "CRUISE_SCCM_MIA" 5 "BRAKE_INVALID" 4 "STALK" 3 "PM_REQUEST" 2 "PM_MIA" 1 "MOTOR_SPEED_MISMATCH" 0 "NONE" ;
VAL_ 1319 DI_a124_cruiseFaultStack 6 "DIRECT_TORQUE_CONTROL" 5 "DIRECT_PEDAL_CONTROL" 4 "AEB_CONTROL" 3 "VELOCITY_PROFILE_CONTROL" 2 "LONC_TORQUE_PROFILER" 1 "LEGACY_CRUISE" 0 "REQUEST_STACK_SNA" ;
VAL_ 1319 DI_a130_aebFaultReason 15 "DAS_REQ_DI_UNAVAIL" 14 "ACCEL_REQ_INVALID" 13 "MIN_TIME_BTWN_EVENTS" 12 "ESP_MIA" 11 "ESP_FAULT" 10 "EPB_NOT_PARKED" 9 "ACCEL_OUT_OF_BOUNDS" 8 "PM_REQUEST" 7 "VEL_EST_ABNORMAL" 6 "DAS_SNA" 4 "SPEED_DELTA" 3 "EBR_FAULT" 2 "PM_MIA" 1 "EPB_MIA" 0 "NONE" ;
VAL_ 1319 DI_a130_aebSmState 5 "FAULT" 4 "EXIT" 3 "STANDSTILL" 2 "ENABLE" 1 "STANDBY" 0 "UNAVAILABLE" ;
VAL_ 1319 DI_a130_dasAebEvent 3 "SNA" 2 "FAULT" 1 "ACTIVE" 0 "NOT_ACTIVE" ;
VAL_ 1319 DI_a135_vhldFaultReason 10 "ESP_MIA" 9 "VDC_FAULT" 8 "NOT_STOPPED" 7 "EPB_NOT_PARKED" 6 "PM_REQUEST" 5 "WHEEL_SPDS_INVAL" 4 "BRAKE_INVALID" 3 "EBR_FAULT" 2 "EPB_MIA" 1 "PM_MIA" 0 "NONE" ;
VAL_ 1319 DI_a146_panicReason 6 "EPB_RELEASE_TIMEOUT" 5 "SKID_DETECTED" 4 "EPB_INVALID" 3 "EPB_APPLY_TIMEOUT" 2 "EPB_MIA" 1 "EPB_FAULT" 0 "NONE" ;
VAL_ 1319 DI_a160_tireFitment 3 "SNA" 1 "STAGGERED" 0 "SQUARE" ;
VAL_ 1319 DI_a160_distanceSinceLastTireCon 4095 "SNA" ;
VAL_ 1319 DI_a162_shiftDeniedReason 15 "NONE" 10 "BRAKE_PRESS_REQUIRED" 9 "GARAGE_SHIFT_PEDAL" 8 "DRIVE_RAIL_GOING_DOWN" 7 "SHIFT_AFTER_CRUISE_CANCEL" 6 "BRAKE_AFTER_CRUISE_CANCEL" 5 "ACCEL_PEDAL_PRESSED" 4 "SYS_STATE_NOT_ENABLED" 3 "APC_PARKING" 2 "AUTOPILOT_DRIVER_LOCKOUT" 1 "NO_BRAKES_FACTORY" 0 "MOTOR_SPEED" ;
VAL_ 1319 DI_a162_autonomyBehavior 2 "DRIVERLESS_NO_TAKEOVER" 1 "DRIVERLESS_TAKEOVER" 0 "DRIVER" ;
VAL_ 1319 DI_a162_currentGear 7 "SNA" 4 "D" 3 "N" 2 "R" 1 "P" 0 "INVALID" ;
VAL_ 1319 DI_a162_requestedGear 7 "SNA" 4 "D" 3 "N" 2 "R" 1 "P" 0 "INVALID" ;
VAL_ 1319 DI_a162_requestSource 9 "GRR_AUTOSHIFT" 8 "SMART_SHIFT" 7 "CCCM_SHIFT" 6 "GTW_SHIFT" 5 "PM" 4 "DENIED_SHIFT" 3 "LONC" 2 "AUTOPARK" 1 "EPB" 0 "DRIVER_SHIFT" ;
VAL_ 1319 DI_a162_sysStateExitCondition 20 "IDLE_USB_ETHERNET_CABLE_CONNECTED" 19 "IDLE_TRUNK_OPEN" 18 "UNAVAILABLE_EXIT_OK" 17 "UNAVAILABLE_UNITS_NOT_AVAILABLE" 16 "UNAVAILABLE_SSPD_SPEED_IS_NOT_PUBLISHED" 15 "UNAVAILABLE_ALERTS_ACTIVE" 14 "UNAVAILABLE_HV_IS_NOT_UP" 13 "UNAVAILABLE_SLIM_GPO_OR_CAN_DRIVE_GOING_DOWN" 12 "IDLE_EXIT_OK" 11 "IDLE_FIRMWARE_VERIFICATION" 10 "IDLE_BATTERY_POWER_LIMITS" 9 "IDLE_NON_ZERO_PEDAL_POS" 8 "IDLE_FALCON_DOOR_OPEN" 7 "IDLE_PROX_DETECTED" 6 "IDLE_FRUNK_NOT_LATCHED" 5 "IDLE_IMMOBILIZER_INHIBIT" 4 "IDLE_HV_NOT_UP_FOR_DRIVE" 3 "IDLE_LV_OR_SBW_STATUS_LIMP" 2 "IDLE_LV_OR_SBW_STATUS_NOT_READY" 1 "IDLE_DRIVE_RAIL_NOT_REQUESTED" 0 "IDLE_VEHICLE_POWER_STATE_NOT_DRIVE" ;
VAL_ 1319 DI_a163_currentGear 7 "SNA" 4 "D" 3 "N" 2 "R" 1 "P" 0 "INVALID" ;
VAL_ 1319 DI_a163_requestedGear 7 "SNA" 4 "D" 3 "N" 2 "R" 1 "P" 0 "INVALID" ;
VAL_ 1319 DI_a163_requestSource 9 "GRR_AUTOSHIFT" 8 "SMART_SHIFT" 7 "CCCM_SHIFT" 6 "GTW_SHIFT" 5 "PM" 4 "DENIED_SHIFT" 3 "LONC" 2 "AUTOPARK" 1 "EPB" 0 "DRIVER_SHIFT" ;
VAL_ 1319 DI_a170_tireSeasonSelected 1 "WINTER" 0 "NON_WINTER" ;
VAL_ 1319 DI_a170_tireFitment 3 "SNA" 1 "STAGGERED" 0 "SQUARE" ;
VAL_ 1319 DI_a170_odometer 4095 "SNA" ;
VAL_ 1319 DI_a170_distanceSinceLastTireCon 63 "SNA" ;
VAL_ 1319 DI_a172_currentGear 7 "SNA" 4 "D" 3 "N" 2 "R" 1 "P" 0 "INVALID" ;
VAL_ 1319 DI_a175_crsNotAvailableReason 50 "AIR_COMPRESSOR_FAULT" 49 "ABS_FAULT" 48 "DRIVERLESS_AUTONOMY_BEHAVIOR" 47 "EPB_DYNAMIC_APPLY" 46 "SGS_REQUEST" 45 "VDC_FAULT" 44 "ACCEL_JERK_OUT_OF_ISO_BOUNDS" 43 "REDUNDANT_BRAKES_ACTIVE" 42 "ABS_UNAVAILABLE" 41 "LONC_DEGRADED" 40 "FACTORY_MODE" 39 "EPB_FAULT" 38 "AEB_STACK_UNAVAILABLE" 37 "AEB_STACK_EVENT_INACTIVE" 36 "DFLK_ENGAGED" 35 "INTERFACE_NOT_SUPPORTED" 34 "CANCEL_ACTIVE" 33 "CONTROL_STACK_SWITCH" 32 "SHIFT_OUTSIDE_SPEED_THRESHOLD" 31 "SHIFT_TIMEOUT" 30 "OFFROAD_MODE_ACTIVE" 29 "DAS_CONTROL_MIA" 28 "UNIT0_FAULT" 27 "BRAKE_TEMPERATURE" 26 "ACC_BACKWARD_AT_HIGH_FORWARD_SPEED" 25 "DAS_SET_SPEED_TOO_HIGH_IN_REVERSE" 24 "MOTOR_SPEED_TOO_HIGH_IN_REVERSE" 23 "VHLD_UNAVAILABLE" 22 "CRUISE_FAULTED" 21 "TRACK_MODE_ACTIVE" 20 "DAS_SNA" 19 "UI_MIA" 18 "WAIT_INIT" 17 "VEL_EST" 16 "MAX_SPEED" 15 "MIN_SPEED" 14 "AEB" 13 "CONFIG" 12 "DI_STATE" 11 "MOTOR_SPEED" 10 "EBR" 9 "VALET_MODE" 8 "SEAT_BELT_UNBUCKLED" 7 "CLOSURE_OPEN" 6 "ACC_CANCEL" 5 "ABS_ACTIVE" 4 "TC_ACTIVE" 3 "VDC_ACTIVE_OR_DEGRADED" 2 "VDC_OR_TC_OFF" 1 "NO_ALERT" 0 "NONE" ;
VAL_ 1319 DI_a175_crsNotAvailableStack 6 "DIRECT_TORQUE_CONTROL" 5 "DIRECT_PEDAL_CONTROL" 4 "AEB_CONTROL" 3 "VELOCITY_PROFILE_CONTROL" 2 "LONC_TORQUE_PROFILER" 1 "LEGACY_CRUISE" 0 "REQUEST_STACK_SNA" ;
VAL_ 1319 DI_a177_newFitment 3 "SNA" 1 "STAGGERED" 0 "SQUARE" ;
VAL_ 1319 DI_a180_crsNotAvailableReason 50 "AIR_COMPRESSOR_FAULT" 49 "ABS_FAULT" 48 "DRIVERLESS_AUTONOMY_BEHAVIOR" 47 "EPB_DYNAMIC_APPLY" 46 "SGS_REQUEST" 45 "VDC_FAULT" 44 "ACCEL_JERK_OUT_OF_ISO_BOUNDS" 43 "REDUNDANT_BRAKES_ACTIVE" 42 "ABS_UNAVAILABLE" 41 "LONC_DEGRADED" 40 "FACTORY_MODE" 39 "EPB_FAULT" 38 "AEB_STACK_UNAVAILABLE" 37 "AEB_STACK_EVENT_INACTIVE" 36 "DFLK_ENGAGED" 35 "INTERFACE_NOT_SUPPORTED" 34 "CANCEL_ACTIVE" 33 "CONTROL_STACK_SWITCH" 32 "SHIFT_OUTSIDE_SPEED_THRESHOLD" 31 "SHIFT_TIMEOUT" 30 "OFFROAD_MODE_ACTIVE" 29 "DAS_CONTROL_MIA" 28 "UNIT0_FAULT" 27 "BRAKE_TEMPERATURE" 26 "ACC_BACKWARD_AT_HIGH_FORWARD_SPEED" 25 "DAS_SET_SPEED_TOO_HIGH_IN_REVERSE" 24 "MOTOR_SPEED_TOO_HIGH_IN_REVERSE" 23 "VHLD_UNAVAILABLE" 22 "CRUISE_FAULTED" 21 "TRACK_MODE_ACTIVE" 20 "DAS_SNA" 19 "UI_MIA" 18 "WAIT_INIT" 17 "VEL_EST" 16 "MAX_SPEED" 15 "MIN_SPEED" 14 "AEB" 13 "CONFIG" 12 "DI_STATE" 11 "MOTOR_SPEED" 10 "EBR" 9 "VALET_MODE" 8 "SEAT_BELT_UNBUCKLED" 7 "CLOSURE_OPEN" 6 "ACC_CANCEL" 5 "ABS_ACTIVE" 4 "TC_ACTIVE" 3 "VDC_ACTIVE_OR_DEGRADED" 2 "VDC_OR_TC_OFF" 1 "NO_ALERT" 0 "NONE" ;
VAL_ 1319 DI_a184_apcCancelReason 25 "ABORT_CONTROL_STACK_SWITCH" 24 "ABORT_GEAR_STALK" 23 "ABORT_EPB_INTERLOCK" 22 "ABORT_EPB_FAULT" 21 "ABORT_DISTANCE" 20 "ABORT_GRADE_TOO_STEEP" 19 "ABORT_VEHICLE_SPEED" 18 "ABORT_DAS_SPEED" 17 "CANCEL_SELFPARK_STATE_TIMEOUT" 16 "ABORT_DRIVER_LEAVING" 15 "ABORT_CLOSURE" 14 "ABORT_BRAKE" 13 "ABORT_CRUISE_STATE" 12 "ABORT_STOPPING_TIMEOUT" 11 "ABORT_DI_SYS_STATE" 10 "ABORT_SHIFT_TIMEOUT" 9 "ABORT_CONTROL_INTEGRATOR" 8 "ABORT_DAS_STATE" 7 "ABORT_DAS_REQUEST" 6 "CANCEL_CRUISE" 5 "CANCEL_AEB_ACTIVE" 4 "ABORT_MOTION_TIMEOUT" 3 "ABORT_OVERRIDE" 2 "CANCEL_EPB_APPLY" 1 "CANCEL_GEAR" 0 "CANCEL_NONE" ;
VAL_ 1319 DI_a184_apcUnavailableReason 15 "TEMP_TOO_COLD" 14 "ACCEL_PEDAL" 13 "BRAKE_PEDAL" 12 "SYSTEM_STATE" 11 "EBR" 10 "GEAR" 9 "NOT_SUPPORTED" 8 "TRAILER_MODE" 7 "EPB" 6 "VALET_MODE" 5 "GRADE_TOO_STEEP" 4 "DRIVER_LEAVING" 3 "CLOSURE_OPEN" 2 "VDC" 1 "CRUISE" 0 "NONE" ;
VAL_ 1319 DI_a184_autoparkInternalState 17 "ABORTED" 16 "ABORTING" 15 "UNPARK_COMPLETE" 14 "COMPLETE" 13 "PRE_COMPLETE" 12 "ACTIVE_SHFT_R" 11 "ACTIVE_SHFT_D" 10 "ACTIVE_DRIVE_FW" 9 "ACTIVE_DRIVE_BW" 8 "RESUMED" 7 "PAUSED" 6 "PAUSING" 5 "SELFPARK_UNPARK" 4 "SELFPARK_START" 3 "STARTED_CRUISE" 2 "STARTED_BRAKE" 1 "STANDBY" 0 "UNAVAILABLE" ;
VAL_ 1319 DI_a185_apcCancelReason 25 "ABORT_CONTROL_STACK_SWITCH" 24 "ABORT_GEAR_STALK" 23 "ABORT_EPB_INTERLOCK" 22 "ABORT_EPB_FAULT" 21 "ABORT_DISTANCE" 20 "ABORT_GRADE_TOO_STEEP" 19 "ABORT_VEHICLE_SPEED" 18 "ABORT_DAS_SPEED" 17 "CANCEL_SELFPARK_STATE_TIMEOUT" 16 "ABORT_DRIVER_LEAVING" 15 "ABORT_CLOSURE" 14 "ABORT_BRAKE" 13 "ABORT_CRUISE_STATE" 12 "ABORT_STOPPING_TIMEOUT" 11 "ABORT_DI_SYS_STATE" 10 "ABORT_SHIFT_TIMEOUT" 9 "ABORT_CONTROL_INTEGRATOR" 8 "ABORT_DAS_STATE" 7 "ABORT_DAS_REQUEST" 6 "CANCEL_CRUISE" 5 "CANCEL_AEB_ACTIVE" 4 "ABORT_MOTION_TIMEOUT" 3 "ABORT_OVERRIDE" 2 "CANCEL_EPB_APPLY" 1 "CANCEL_GEAR" 0 "CANCEL_NONE" ;
VAL_ 1319 DI_a185_apcUnavailableReason 15 "TEMP_TOO_COLD" 14 "ACCEL_PEDAL" 13 "BRAKE_PEDAL" 12 "SYSTEM_STATE" 11 "EBR" 10 "GEAR" 9 "NOT_SUPPORTED" 8 "TRAILER_MODE" 7 "EPB" 6 "VALET_MODE" 5 "GRADE_TOO_STEEP" 4 "DRIVER_LEAVING" 3 "CLOSURE_OPEN" 2 "VDC" 1 "CRUISE" 0 "NONE" ;
VAL_ 1319 DI_a185_crsNotAvailableReason 50 "AIR_COMPRESSOR_FAULT" 49 "ABS_FAULT" 48 "DRIVERLESS_AUTONOMY_BEHAVIOR" 47 "EPB_DYNAMIC_APPLY" 46 "SGS_REQUEST" 45 "VDC_FAULT" 44 "ACCEL_JERK_OUT_OF_ISO_BOUNDS" 43 "REDUNDANT_BRAKES_ACTIVE" 42 "ABS_UNAVAILABLE" 41 "LONC_DEGRADED" 40 "FACTORY_MODE" 39 "EPB_FAULT" 38 "AEB_STACK_UNAVAILABLE" 37 "AEB_STACK_EVENT_INACTIVE" 36 "DFLK_ENGAGED" 35 "INTERFACE_NOT_SUPPORTED" 34 "CANCEL_ACTIVE" 33 "CONTROL_STACK_SWITCH" 32 "SHIFT_OUTSIDE_SPEED_THRESHOLD" 31 "SHIFT_TIMEOUT" 30 "OFFROAD_MODE_ACTIVE" 29 "DAS_CONTROL_MIA" 28 "UNIT0_FAULT" 27 "BRAKE_TEMPERATURE" 26 "ACC_BACKWARD_AT_HIGH_FORWARD_SPEED" 25 "DAS_SET_SPEED_TOO_HIGH_IN_REVERSE" 24 "MOTOR_SPEED_TOO_HIGH_IN_REVERSE" 23 "VHLD_UNAVAILABLE" 22 "CRUISE_FAULTED" 21 "TRACK_MODE_ACTIVE" 20 "DAS_SNA" 19 "UI_MIA" 18 "WAIT_INIT" 17 "VEL_EST" 16 "MAX_SPEED" 15 "MIN_SPEED" 14 "AEB" 13 "CONFIG" 12 "DI_STATE" 11 "MOTOR_SPEED" 10 "EBR" 9 "VALET_MODE" 8 "SEAT_BELT_UNBUCKLED" 7 "CLOSURE_OPEN" 6 "ACC_CANCEL" 5 "ABS_ACTIVE" 4 "TC_ACTIVE" 3 "VDC_ACTIVE_OR_DEGRADED" 2 "VDC_OR_TC_OFF" 1 "NO_ALERT" 0 "NONE" ;
VAL_ 1319 DI_a185_crsFaultReason 22 "VHLD_FAULTED" 21 "CONFIG_MISMATCH" 20 "EPB_MIA" 19 "ACCEL_JERK_OUT_OF_ISO_BOUNDS" 17 "DAS_SNA" 16 "VELOCITY_ESTIMATE_NOT_NORMAL" 15 "ACCEL_OUT_OF_BOUNDS" 14 "EBR_FAULT" 13 "TC_FAULT" 12 "ESP_MIA" 11 "VDC_FAULT" 10 "EPB_FAULT" 9 "BRAKE_MIA" 8 "CRS_STATE_MISM" 7 "ABS_MIA" 6 "CRUISE_SCCM_MIA" 5 "BRAKE_INVALID" 4 "STALK" 3 "PM_REQUEST" 2 "PM_MIA" 1 "MOTOR_SPEED_MISMATCH" 0 "NONE" ;
VAL_ 1319 DI_a185_autoparkInternalState 17 "ABORTED" 16 "ABORTING" 15 "UNPARK_COMPLETE" 14 "COMPLETE" 13 "PRE_COMPLETE" 12 "ACTIVE_SHFT_R" 11 "ACTIVE_SHFT_D" 10 "ACTIVE_DRIVE_FW" 9 "ACTIVE_DRIVE_BW" 8 "RESUMED" 7 "PAUSED" 6 "PAUSING" 5 "SELFPARK_UNPARK" 4 "SELFPARK_START" 3 "STARTED_CRUISE" 2 "STARTED_BRAKE" 1 "STANDBY" 0 "UNAVAILABLE" ;
VAL_ 1319 DI_a190_tireFitment 3 "SNA" 1 "STAGGERED" 0 "SQUARE" ;
VAL_ 1319 DI_a191_currentGear 7 "SNA" 4 "D" 3 "N" 2 "R" 1 "P" 0 "INVALID" ;
VAL_ 1319 DI_a191_requestedGear 7 "SNA" 4 "D" 3 "N" 2 "R" 1 "P" 0 "INVALID" ;
VAL_ 1319 DI_a191_requestSource 9 "GRR_AUTOSHIFT" 8 "SMART_SHIFT" 7 "CCCM_SHIFT" 6 "GTW_SHIFT" 5 "PM" 4 "DENIED_SHIFT" 3 "LONC" 2 "AUTOPARK" 1 "EPB" 0 "DRIVER_SHIFT" ;
VAL_ 1319 DI_a193_brakeTorqueFrL 7 "TEMP_QF_INVALID" 6 "QF_VALIDITY" 5 "CAN" 4 "QF" 3 "RATE" 2 "FREEZE" 1 "RANGE" 0 "VALID" ;
VAL_ 1319 DI_a193_brakeTorqueFrR 7 "TEMP_QF_INVALID" 6 "QF_VALIDITY" 5 "CAN" 4 "QF" 3 "RATE" 2 "FREEZE" 1 "RANGE" 0 "VALID" ;
VAL_ 1319 DI_a194_brakeTorqueReL 7 "TEMP_QF_INVALID" 6 "QF_VALIDITY" 5 "CAN" 4 "QF" 3 "RATE" 2 "FREEZE" 1 "RANGE" 0 "VALID" ;
VAL_ 1319 DI_a194_brakeTorqueReR 7 "TEMP_QF_INVALID" 6 "QF_VALIDITY" 5 "CAN" 4 "QF" 3 "RATE" 2 "FREEZE" 1 "RANGE" 0 "VALID" ;
VAL_ 1319 DI_a198_MCPressure 7 "TEMP_QF_INVALID" 6 "QF_VALIDITY" 5 "CAN" 4 "QF" 3 "RATE" 2 "FREEZE" 1 "RANGE" 0 "VALID" ;
VAL_ 1319 DI_a198_steeringAngle 7 "TEMP_QF_INVALID" 6 "QF_VALIDITY" 5 "CAN" 4 "QF" 3 "RATE" 2 "FREEZE" 1 "RANGE" 0 "VALID" ;
VAL_ 1319 DI_a199_preControlActive 1 "ACTIVE" 0 "NOT_ACTIVE" ;
VAL_ 1319 DI_a199_oversteerdMzActive 1 "ACTIVE" 0 "NOT_ACTIVE" ;
VAL_ 1319 DI_a199_decelControlActive 1 "ACTIVE" 0 "NOT_ACTIVE" ;
VAL_ 1319 DI_a199_understeerdMzActive 1 "ACTIVE" 0 "NOT_ACTIVE" ;
VAL_ 1319 DI_a199_vdcMode 2 "TRACK" 1 "ON" 0 "OFF" ;
VAL_ 1319 DI_a200_MBPCheckStatus 1 "ACTIVE" 0 "GHOSTED" ;
VAL_ 1319 DI_a200_MBPFailedCase 33 "FR_DFLK_VS_WHEEL_SPEED_DIFF" 32 "RE_DFLK_VS_WHEEL_SPEED_DIFF" 31 "NONLINEAR_YAW_RATE_STEERING_ANGLE_VELOCITY" 30 "PERSIST_PITCH_RATE" 29 "PERSIST_ROLL_RATE" 28 "GRADE_ANGLE" 27 "BANK_ANGLE" 26 "RWD_FR_RIGHT_WHEEL_SPEED" 25 "RWD_FR_LEFT_WHEEL_SPEED" 24 "IBST_STROKE_VS_MC_PRESSURE" 23 "RER_WHEEL_SLIP_WHEELS_SPEEDS_VEHICLE_VELOCITY" 22 "REL_WHEEL_SLIP_WHEELS_SPEEDS_VEHICLE_VELOCITY" 21 "FRR_WHEEL_SLIP_WHEELS_SPEEDS_VEHICLE_VELOCITY" 20 "FRL_WHEEL_SLIP_WHEELS_SPEEDS_VEHICLE_VELOCITY" 19 "RE_WHEEL_SPEED_VS_VDC_MOTOR_SPEED" 18 "FR_WHEEL_SPEED_VS_VDC_MOTOR_SPEED" 17 "OFFSET_VERT_ACCEL" 16 "VERT_ACCEL" 15 "LAT_ACCEL" 14 "LONG_ACCEL" 13 "YAW_RATE" 12 "PITCH_RATE" 11 "ROLL_RATE" 10 "STEERING_ANGLE_OFFSET" 9 "MC_PRESSURE_BRAKE_PEDAL" 8 "BRAKE_TORQUES_VS_LONG_ACCEL" 7 "VELOCITY_ESTIMATE_VS_WHEEL_SPEEDS" 6 "US_VELOCITY_YAW_RATE_VS_LAT_ACCEL" 5 "OS_VELOCITY_YAW_RATE_VS_LAT_ACCEL" 4 "VELOCITY_YAW_RATE_VS_LAT_ACCEL" 3 "TIRE_MISMATCH_DETECTED" 2 "YAW_RATE_WHEEL_SPEEDS" 1 "LAT_ACCEL_STEERING_ANGLE_VELOCITY" 0 "YAW_RATE_STEERING_ANGLE_VELOCITY" ;
VAL_ 1319 DI_a202_reason 12 "HV_DOWN" 11 "CRUISE" 10 "OPD" 9 "DRV_FAULT" 8 "IMMEDIATE" 7 "SERVICE_MODE" 6 "UPDATE_STARTED" 5 "GPO" 4 "LIMP" 3 "MOVEMENT" 2 "PARKBRAKE" 1 "NO_ALERT" 0 "NONE" ;
VAL_ 1319 DI_a202_sysStateExitCondition 20 "IDLE_USB_ETHERNET_CABLE_CONNECTED" 19 "IDLE_TRUNK_OPEN" 18 "UNAVAILABLE_EXIT_OK" 17 "UNAVAILABLE_UNITS_NOT_AVAILABLE" 16 "UNAVAILABLE_SSPD_SPEED_IS_NOT_PUBLISHED" 15 "UNAVAILABLE_ALERTS_ACTIVE" 14 "UNAVAILABLE_HV_IS_NOT_UP" 13 "UNAVAILABLE_SLIM_GPO_OR_CAN_DRIVE_GOING_DOWN" 12 "IDLE_EXIT_OK" 11 "IDLE_FIRMWARE_VERIFICATION" 10 "IDLE_BATTERY_POWER_LIMITS" 9 "IDLE_NON_ZERO_PEDAL_POS" 8 "IDLE_FALCON_DOOR_OPEN" 7 "IDLE_PROX_DETECTED" 6 "IDLE_FRUNK_NOT_LATCHED" 5 "IDLE_IMMOBILIZER_INHIBIT" 4 "IDLE_HV_NOT_UP_FOR_DRIVE" 3 "IDLE_LV_OR_SBW_STATUS_LIMP" 2 "IDLE_LV_OR_SBW_STATUS_NOT_READY" 1 "IDLE_DRIVE_RAIL_NOT_REQUESTED" 0 "IDLE_VEHICLE_POWER_STATE_NOT_DRIVE" ;
VAL_ 1319 DI_a203_ptcStateLocal 6 "SNA" 5 "STARTUP" 4 "ON" 3 "ADD_REDUCED" 2 "WHEELS_REDUCED" 1 "BACKUP" 0 "FAULTED" ;
VAL_ 1319 DI_a203_btcState 1 "ON" 0 "OFF" ;
VAL_ 1319 DI_a204_longAccel 7 "TEMP_QF_INVALID" 6 "QF_VALIDITY" 5 "CAN" 4 "QF" 3 "RATE" 2 "FREEZE" 1 "RANGE" 0 "VALID" ;
VAL_ 1319 DI_a204_rollRate 7 "TEMP_QF_INVALID" 6 "QF_VALIDITY" 5 "CAN" 4 "QF" 3 "RATE" 2 "FREEZE" 1 "RANGE" 0 "VALID" ;
VAL_ 1319 DI_a205_latAccel 7 "TEMP_QF_INVALID" 6 "QF_VALIDITY" 5 "CAN" 4 "QF" 3 "RATE" 2 "FREEZE" 1 "RANGE" 0 "VALID" ;
VAL_ 1319 DI_a205_pitchRate 7 "TEMP_QF_INVALID" 6 "QF_VALIDITY" 5 "CAN" 4 "QF" 3 "RATE" 2 "FREEZE" 1 "RANGE" 0 "VALID" ;
VAL_ 1319 DI_a206_verticalAccel 7 "TEMP_QF_INVALID" 6 "QF_VALIDITY" 5 "CAN" 4 "QF" 3 "RATE" 2 "FREEZE" 1 "RANGE" 0 "VALID" ;
VAL_ 1319 DI_a206_yawRate 7 "TEMP_QF_INVALID" 6 "QF_VALIDITY" 5 "CAN" 4 "QF" 3 "RATE" 2 "FREEZE" 1 "RANGE" 0 "VALID" ;
VAL_ 1319 DI_a210_ptcStateGlobal 3 "SNA" 2 "ON" 1 "BACKUP" 0 "FAULTED" ;
VAL_ 1319 DI_a210_espActuatorState 3 "COMMAND_INVALID" 2 "ACTUATOR_AVAILABLE" 1 "ACTUATOR_DEGRADED" 0 "ACTUATOR_UNAVAILABLE" ;
VAL_ 1319 DI_a223_ptcStateLocal 6 "SNA" 5 "STARTUP" 4 "ON" 3 "ADD_REDUCED" 2 "WHEELS_REDUCED" 1 "BACKUP" 0 "FAULTED" ;
VAL_ 1319 DI_a223_btcState 1 "ON" 0 "OFF" ;
VAL_ 1319 DI_a223_velocityEstimatorState 5 "BACKUP_MOTOR" 4 "BACKUP_WHEELS_B" 3 "BACKUP_WHEELS_A" 2 "WHEELS_REDUCED" 1 "WHEELS_NORMAL" 0 "NOT_INITIALIZED" ;
VAL_ 1319 DI_a223_addState_dir 3 "FAULTED" 2 "BACKUP" 1 "NORMAL" 0 "STARTUP" ;
VAL_ 1319 DI_a223_addState_dif 3 "FAULTED" 2 "BACKUP" 1 "NORMAL" 0 "STARTUP" ;
VAL_ 1319 DI_a223_DI_tractionControlMode 7 "SLIPPERY_SURFACE" 6 "OFFROAD_ASSIST" 5 "DYNO_MODE" 4 "ROLLS_MODE" 3 "DEV_MODE_2" 2 "DEV_MODE_1" 1 "SLIP_START" 0 "NORMAL" ;
VAL_ 1319 DI_a223_UI_tractionControlMode 7 "SLIPPERY_SURFACE_SELECTED" 6 "OFFROAD_ASSIST_SELECTED" 5 "DYNO_MODE_SELECTED" 4 "ROLLS_MODE_SELECTED" 3 "DEV_MODE_2_SELECTED" 2 "DEV_MODE_1_SELECTED" 1 "SLIP_START_SELECTED" 0 "NORMAL_SELECTED" ;
VAL_ 1319 DI_a223_driveTCActive 1 "ACTIVE" 0 "INACTIVE" ;
VAL_ 1319 DI_a223_regenTCActive 1 "ACTIVE" 0 "INACTIVE" ;
VAL_ 1319 DI_a227_hvState 6 "UP" 5 "UP_FOR_DC_CHARGE" 4 "UP_FOR_CHARGE" 3 "UP_FOR_DRIVE" 2 "GOING_DOWN" 1 "COMING_UP" 0 "DOWN" ;
VAL_ 1319 DI_a227_vehiclePowerState 3 "DRIVE" 2 "ACCESSORY" 1 "CONDITIONING" 0 "OFF" ;
VAL_ 1319 DI_a232_velocityEstimatorState 5 "BACKUP_MOTOR" 4 "BACKUP_WHEELS_B" 3 "BACKUP_WHEELS_A" 2 "WHEELS_REDUCED" 1 "WHEELS_NORMAL" 0 "NOT_INITIALIZED" ;
VAL_ 1319 DI_a232_UI_tractionControlMode 7 "SLIPPERY_SURFACE_SELECTED" 6 "OFFROAD_ASSIST_SELECTED" 5 "DYNO_MODE_SELECTED" 4 "ROLLS_MODE_SELECTED" 3 "DEV_MODE_2_SELECTED" 2 "DEV_MODE_1_SELECTED" 1 "SLIP_START_SELECTED" 0 "NORMAL_SELECTED" ;
VAL_ 1319 DI_a232_allWhlSpeedRotationAvail 1 "AVAILABLE" 0 "UNAVAILABLE" ;
VAL_ 1319 DI_a232_BrakeMasterCylPressValid 1 "VALID" 0 "INVALID" ;
VAL_ 1319 DI_a232_WheelBrakeTorquesValid 1 "VALID" 0 "INVALID" ;
VAL_ 1319 DI_a232_AbsBrakeEventActiveValid 1 "VALID" 0 "INVALID" ;
VAL_ 1319 DI_a232_UndersteerActiveValid 1 "VALID" 0 "INVALID" ;
VAL_ 1319 DI_a232_OversteerActiveValid 1 "VALID" 0 "INVALID" ;
VAL_ 1319 DI_a232_allMotorTorquesValid 1 "VALID" 0 "INVALID" ;
VAL_ 1319 DI_a232_lateralAccelValid 1 "VALID" 0 "INVALID" ;
VAL_ 1319 DI_a232_longitudinalAccelValid 1 "VALID" 0 "INVALID" ;
VAL_ 1319 DI_a232_yawRateValid 1 "VALID" 0 "INVALID" ;
VAL_ 1319 DI_a232_steerAngleValid 1 "VALID" 0 "INVALID" ;
VAL_ 1319 DI_a245_ebrStatus 3 "EBR_COMMAND_INVALID" 2 "ACTUATING_DI_EBR" 1 "EBR_IS_AVAILABLE" 0 "EBR_IS_NOT_AVAILABLE" ;
VAL_ 1319 DI_a245_vehicleHoldState 7 "INIT" 6 "FAULT" 5 "PARK" 4 "BLEND_OUT" 3 "STANDSTILL" 2 "BLEND_IN" 1 "STANDBY" 0 "UNAVAILABLE" ;
VAL_ 1319 DI_a246_onePedalDrivingState 8 "NUM_STATES" 7 "MOTOR_BLEND_IN" 6 "NO_MOTOR" 5 "MOTOR_BLEND_OUT_ACTIVE" 4 "MOTOR_BLEND_OUT_PENDING" 3 "NOMINAL" 2 "STANDBY" 1 "QUICK_BRAKE_RAMP" 0 "UNAVAILABLE" ;
VAL_ 1319 DI_a246_opdUnavailableReason 16 "UNIT0_FAULT" 15 "MOTOR_HOLD_TIMEOUT" 14 "INVALID_MSPD" 13 "PARKED" 12 "TORQUE_LIMIT" 11 "GRADE_ESTIMATE" 10 "TRACTION_CONTROL" 9 "VELOCITY_ESTIMATE" 8 "TRACK_MODE" 7 "EPB_FAULT" 6 "SKID" 5 "INVALID_BRAKE_SENSE" 4 "DI_SYS_STATE" 3 "GEAR" 2 "PM_FAULT" 1 "DISABLED" 0 "NONE" ;
